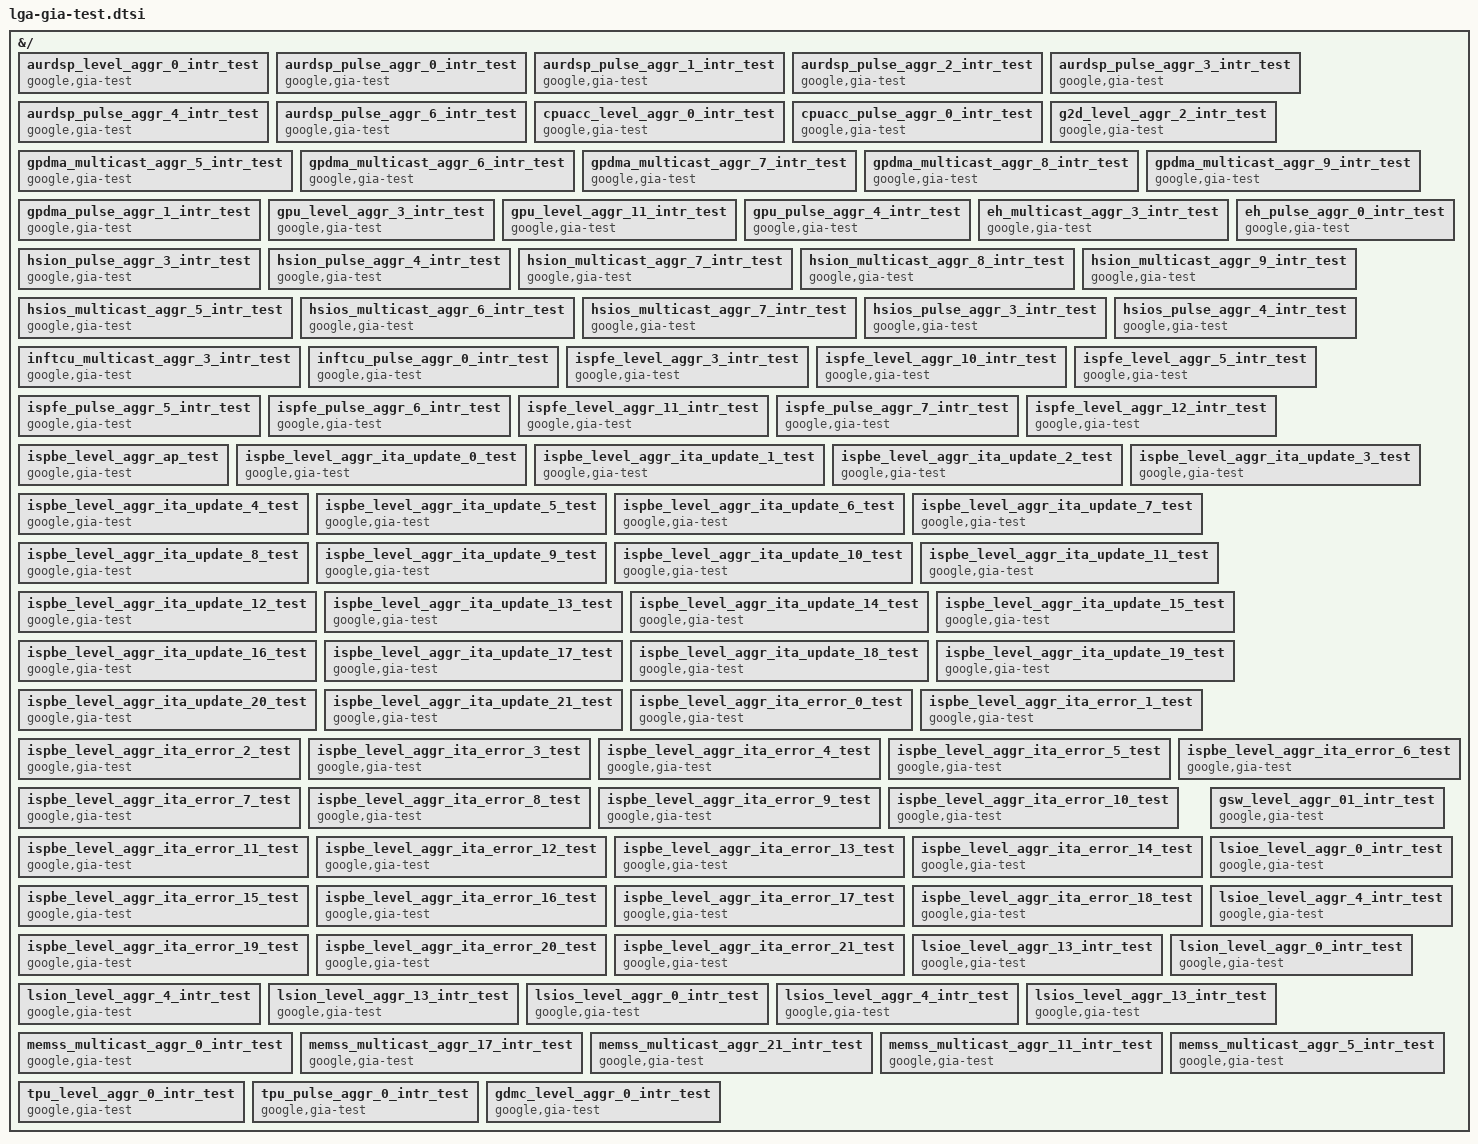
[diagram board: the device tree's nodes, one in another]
// SPDX-License-Identifier: GPL-2.0-only OR BSD-3-Clause
/*
 * !!!!!!!!!!!!!!!!!!!!!!!!!!!!!!!!!!!!!!!!!!!!!!!!!
 * !!!!! THIS IS A GENERATED FILE, DO NOT EDIT !!!!!
 * !!!!!!!!!!!!!!!!!!!!!!!!!!!!!!!!!!!!!!!!!!!!!!!!!
 *
 * This file provides test nodes for use with the GIA test driver
 * Generate using scripts/irqchip/gen-test-gia-dt-nodes.py
 *
 * Copyright 2024 Google LLC
 */

#include <dt-bindings/interrupt-controller/lga-gic.h>
#include <dt-bindings/interrupt-controller/irq-gia-google-lga.h>

&{/} {
	aurdsp_level_aggr_0_intr_test: aurdsp_level_aggr_0_intr_test {
		compatible = "google,gia-test";
		power-domains = <&sswrp_aurora_pd>;
		interrupt-parent = <&aurdsp_level_aggr_0_intr>;
		interrupts =
			<AURDSP_GIA_LEVEL_AGGR_0_AURORA_AUX_RA_CORE_0_NS_INTR>,
			<AURDSP_GIA_LEVEL_AGGR_0_AURORA_AUX_RA_CORE_1_NS_INTR>,
			<AURDSP_GIA_LEVEL_AGGR_0_AURORA_AUX_RA_CORE_2_NS_INTR>,
			<AURDSP_GIA_LEVEL_AGGR_0_AURORA_AUX_RA_MCU_NS_INTR>,
			<AURDSP_GIA_LEVEL_AGGR_0_AURORA_AUX_RFW_XFW_NS_INTR>,
			<AURDSP_GIA_LEVEL_AGGR_0_AURORA_AUX_AUR_TOP_RFW_XFW_NS_INTR>,
			<AURDSP_GIA_LEVEL_AGGR_0_AURORA_AUX_AON_LPCM_RFW_XFW_NS_INTR>,
			<AURDSP_GIA_LEVEL_AGGR_0_AURORA_AUX_TBU0_MFW_NS_INTR>,
			<AURDSP_GIA_LEVEL_AGGR_0_AURORA_AUX_TBU1_MFW_NS_INTR>,
			<AURDSP_GIA_LEVEL_AGGR_0_AURORA_AUX_TBU2_MFW_NS_INTR>,
			<AURDSP_GIA_LEVEL_AGGR_0_AURORA_AUX_TBU3_MFW_NS_INTR>,
			<AURDSP_GIA_LEVEL_AGGR_0_AURORA_AUX_GEM_CORE_0_IRQ>,
			<AURDSP_GIA_LEVEL_AGGR_0_AURORA_AUX_GEM_CORE_1_IRQ>,
			<AURDSP_GIA_LEVEL_AGGR_0_AURORA_AUX_GEM_CORE_2_IRQ>,
			<AURDSP_GIA_LEVEL_AGGR_0_AURORA_AUX_GEM_MCU_IRQ>,
			<AURDSP_GIA_LEVEL_AGGR_0_AURORA_AUX_GEM_TCU_IRQ>,
			<AURDSP_GIA_LEVEL_AGGR_0_AURORA_AURORA_TOP_UNCORE_MCU_UNCORE_NOC_IXBAR0_XBA0_ERR_IRQ>,
			<AURDSP_GIA_LEVEL_AGGR_0_AURORA_AURORA_TOP_UNCORE_MCU_UNCORE_NOC_IXBAR1_XBA1_ERR_IRQ>,
			<AURDSP_GIA_LEVEL_AGGR_0_AURORA_AURORA_TOP_UNCORE_MCU_UNCORE_NOC_IXBAR2_XBA2_ERR_IRQ>,
			<AURDSP_GIA_LEVEL_AGGR_0_AURORA_AURORA_TOP_UNCORE_MCU_UNCORE_NOC_IXBAR3_XBA3_ERR_IRQ>,
			<AURDSP_GIA_LEVEL_AGGR_0_AURORA_AURORA_TOP_UNCORE_MCU_UNCORE_NOC_IXBAR4_XBA4_ERR_IRQ>,
			<AURDSP_GIA_LEVEL_AGGR_0_AURORA_AURORA_TOP_UNCORE_MCU_UNCORE_NOC_IXBAR5_XBA5_ERR_IRQ>,
			<AURDSP_GIA_LEVEL_AGGR_0_AURORA_AUX_CTRL_NOC_XBA0_ERR_IRQ>,
			<AURDSP_GIA_LEVEL_AGGR_0_GIA_PLUSE_PULSE_AGGR_0_INTR>,
			<AURDSP_GIA_LEVEL_AGGR_0_GIA_PLUSE_PULSE_AGGR_1_INTR>,
			<AURDSP_GIA_LEVEL_AGGR_0_GIA_PLUSE_PULSE_AGGR_2_INTR>,
			<AURDSP_GIA_LEVEL_AGGR_0_GIA_PLUSE_PULSE_AGGR_3_INTR>,
			<AURDSP_GIA_LEVEL_AGGR_0_GIA_PLUSE_PULSE_AGGR_4_INTR>,
			<AURDSP_GIA_LEVEL_AGGR_0_GIA_PLUSE_PULSE_AGGR_6_INTR>;
		interrupt-names =
			"AURDSP_GIA_LEVEL_AGGR_0_AURORA_AUX_RA_CORE_0_NS_INTR",
			"AURDSP_GIA_LEVEL_AGGR_0_AURORA_AUX_RA_CORE_1_NS_INTR",
			"AURDSP_GIA_LEVEL_AGGR_0_AURORA_AUX_RA_CORE_2_NS_INTR",
			"AURDSP_GIA_LEVEL_AGGR_0_AURORA_AUX_RA_MCU_NS_INTR",
			"AURDSP_GIA_LEVEL_AGGR_0_AURORA_AUX_RFW_XFW_NS_INTR",
			"AURDSP_GIA_LEVEL_AGGR_0_AURORA_AUX_AUR_TOP_RFW_XFW_NS_INTR",
			"AURDSP_GIA_LEVEL_AGGR_0_AURORA_AUX_AON_LPCM_RFW_XFW_NS_INTR",
			"AURDSP_GIA_LEVEL_AGGR_0_AURORA_AUX_TBU0_MFW_NS_INTR",
			"AURDSP_GIA_LEVEL_AGGR_0_AURORA_AUX_TBU1_MFW_NS_INTR",
			"AURDSP_GIA_LEVEL_AGGR_0_AURORA_AUX_TBU2_MFW_NS_INTR",
			"AURDSP_GIA_LEVEL_AGGR_0_AURORA_AUX_TBU3_MFW_NS_INTR",
			"AURDSP_GIA_LEVEL_AGGR_0_AURORA_AUX_GEM_CORE_0_IRQ",
			"AURDSP_GIA_LEVEL_AGGR_0_AURORA_AUX_GEM_CORE_1_IRQ",
			"AURDSP_GIA_LEVEL_AGGR_0_AURORA_AUX_GEM_CORE_2_IRQ",
			"AURDSP_GIA_LEVEL_AGGR_0_AURORA_AUX_GEM_MCU_IRQ",
			"AURDSP_GIA_LEVEL_AGGR_0_AURORA_AUX_GEM_TCU_IRQ",
			"AURDSP_GIA_LEVEL_AGGR_0_AURORA_AURORA_TOP_UNCORE_MCU_UNCORE_NOC_IXBAR0_XBA0_ERR_IRQ",
			"AURDSP_GIA_LEVEL_AGGR_0_AURORA_AURORA_TOP_UNCORE_MCU_UNCORE_NOC_IXBAR1_XBA1_ERR_IRQ",
			"AURDSP_GIA_LEVEL_AGGR_0_AURORA_AURORA_TOP_UNCORE_MCU_UNCORE_NOC_IXBAR2_XBA2_ERR_IRQ",
			"AURDSP_GIA_LEVEL_AGGR_0_AURORA_AURORA_TOP_UNCORE_MCU_UNCORE_NOC_IXBAR3_XBA3_ERR_IRQ",
			"AURDSP_GIA_LEVEL_AGGR_0_AURORA_AURORA_TOP_UNCORE_MCU_UNCORE_NOC_IXBAR4_XBA4_ERR_IRQ",
			"AURDSP_GIA_LEVEL_AGGR_0_AURORA_AURORA_TOP_UNCORE_MCU_UNCORE_NOC_IXBAR5_XBA5_ERR_IRQ",
			"AURDSP_GIA_LEVEL_AGGR_0_AURORA_AUX_CTRL_NOC_XBA0_ERR_IRQ",
			"AURDSP_GIA_LEVEL_AGGR_0_GIA_PLUSE_PULSE_AGGR_0_INTR",
			"AURDSP_GIA_LEVEL_AGGR_0_GIA_PLUSE_PULSE_AGGR_1_INTR",
			"AURDSP_GIA_LEVEL_AGGR_0_GIA_PLUSE_PULSE_AGGR_2_INTR",
			"AURDSP_GIA_LEVEL_AGGR_0_GIA_PLUSE_PULSE_AGGR_3_INTR",
			"AURDSP_GIA_LEVEL_AGGR_0_GIA_PLUSE_PULSE_AGGR_4_INTR",
			"AURDSP_GIA_LEVEL_AGGR_0_GIA_PLUSE_PULSE_AGGR_6_INTR";
	};

	aurdsp_pulse_aggr_0_intr_test: aurdsp_pulse_aggr_0_intr_test {
		compatible = "google,gia-test";
		power-domains = <&sswrp_aurora_pd>;
		interrupt-parent = <&aurdsp_pulse_aggr_0_intr>;
		interrupts =
			<AURDSP_GIA_PULSE_AGGR_0_AURORA_AUX_SMMU_TBU_WRAPPER_0_TBU_RAS_FHI>,
			<AURDSP_GIA_PULSE_AGGR_0_AURORA_AUX_SMMU_TBU_WRAPPER_0_TBU_RAS_ERI>,
			<AURDSP_GIA_PULSE_AGGR_0_AURORA_AUX_SMMU_TBU_WRAPPER_0_TBU_RAS_CRI>,
			<AURDSP_GIA_PULSE_AGGR_0_AURORA_AUX_SMMU_TBU_WRAPPER_0_TBU_PMU_IRPT>;
		interrupt-names =
			"AURDSP_GIA_PULSE_AGGR_0_AURORA_AUX_SMMU_TBU_WRAPPER_0_TBU_RAS_FHI",
			"AURDSP_GIA_PULSE_AGGR_0_AURORA_AUX_SMMU_TBU_WRAPPER_0_TBU_RAS_ERI",
			"AURDSP_GIA_PULSE_AGGR_0_AURORA_AUX_SMMU_TBU_WRAPPER_0_TBU_RAS_CRI",
			"AURDSP_GIA_PULSE_AGGR_0_AURORA_AUX_SMMU_TBU_WRAPPER_0_TBU_PMU_IRPT";
	};

	aurdsp_pulse_aggr_1_intr_test: aurdsp_pulse_aggr_1_intr_test {
		compatible = "google,gia-test";
		power-domains = <&sswrp_aurora_pd>;
		interrupt-parent = <&aurdsp_pulse_aggr_1_intr>;
		interrupts =
			<AURDSP_GIA_PULSE_AGGR_1_AURORA_AUX_SMMU_TBU_WRAPPER_1_TBU_RAS_FHI>,
			<AURDSP_GIA_PULSE_AGGR_1_AURORA_AUX_SMMU_TBU_WRAPPER_1_TBU_RAS_ERI>,
			<AURDSP_GIA_PULSE_AGGR_1_AURORA_AUX_SMMU_TBU_WRAPPER_1_TBU_RAS_CRI>,
			<AURDSP_GIA_PULSE_AGGR_1_AURORA_AUX_SMMU_TBU_WRAPPER_1_TBU_PMU_IRPT>;
		interrupt-names =
			"AURDSP_GIA_PULSE_AGGR_1_AURORA_AUX_SMMU_TBU_WRAPPER_1_TBU_RAS_FHI",
			"AURDSP_GIA_PULSE_AGGR_1_AURORA_AUX_SMMU_TBU_WRAPPER_1_TBU_RAS_ERI",
			"AURDSP_GIA_PULSE_AGGR_1_AURORA_AUX_SMMU_TBU_WRAPPER_1_TBU_RAS_CRI",
			"AURDSP_GIA_PULSE_AGGR_1_AURORA_AUX_SMMU_TBU_WRAPPER_1_TBU_PMU_IRPT";
	};

	aurdsp_pulse_aggr_2_intr_test: aurdsp_pulse_aggr_2_intr_test {
		compatible = "google,gia-test";
		power-domains = <&sswrp_aurora_pd>;
		interrupt-parent = <&aurdsp_pulse_aggr_2_intr>;
		interrupts =
			<AURDSP_GIA_PULSE_AGGR_2_AURORA_AUX_SMMU_TBU_WRAPPER_2_TBU_RAS_FHI>,
			<AURDSP_GIA_PULSE_AGGR_2_AURORA_AUX_SMMU_TBU_WRAPPER_2_TBU_RAS_ERI>,
			<AURDSP_GIA_PULSE_AGGR_2_AURORA_AUX_SMMU_TBU_WRAPPER_2_TBU_RAS_CRI>,
			<AURDSP_GIA_PULSE_AGGR_2_AURORA_AUX_SMMU_TBU_WRAPPER_2_TBU_PMU_IRPT>;
		interrupt-names =
			"AURDSP_GIA_PULSE_AGGR_2_AURORA_AUX_SMMU_TBU_WRAPPER_2_TBU_RAS_FHI",
			"AURDSP_GIA_PULSE_AGGR_2_AURORA_AUX_SMMU_TBU_WRAPPER_2_TBU_RAS_ERI",
			"AURDSP_GIA_PULSE_AGGR_2_AURORA_AUX_SMMU_TBU_WRAPPER_2_TBU_RAS_CRI",
			"AURDSP_GIA_PULSE_AGGR_2_AURORA_AUX_SMMU_TBU_WRAPPER_2_TBU_PMU_IRPT";
	};

	aurdsp_pulse_aggr_3_intr_test: aurdsp_pulse_aggr_3_intr_test {
		compatible = "google,gia-test";
		power-domains = <&sswrp_aurora_pd>;
		interrupt-parent = <&aurdsp_pulse_aggr_3_intr>;
		interrupts =
			<AURDSP_GIA_PULSE_AGGR_3_AURORA_AUX_SMMU_TBU_WRAPPER_3_TBU_RAS_FHI>,
			<AURDSP_GIA_PULSE_AGGR_3_AURORA_AUX_SMMU_TBU_WRAPPER_3_TBU_RAS_ERI>,
			<AURDSP_GIA_PULSE_AGGR_3_AURORA_AUX_SMMU_TBU_WRAPPER_3_TBU_RAS_CRI>,
			<AURDSP_GIA_PULSE_AGGR_3_AURORA_AUX_SMMU_TBU_WRAPPER_3_TBU_PMU_IRPT>;
		interrupt-names =
			"AURDSP_GIA_PULSE_AGGR_3_AURORA_AUX_SMMU_TBU_WRAPPER_3_TBU_RAS_FHI",
			"AURDSP_GIA_PULSE_AGGR_3_AURORA_AUX_SMMU_TBU_WRAPPER_3_TBU_RAS_ERI",
			"AURDSP_GIA_PULSE_AGGR_3_AURORA_AUX_SMMU_TBU_WRAPPER_3_TBU_RAS_CRI",
			"AURDSP_GIA_PULSE_AGGR_3_AURORA_AUX_SMMU_TBU_WRAPPER_3_TBU_PMU_IRPT";
	};

	aurdsp_pulse_aggr_4_intr_test: aurdsp_pulse_aggr_4_intr_test {
		compatible = "google,gia-test";
		power-domains = <&sswrp_aurora_pd>;
		interrupt-parent = <&aurdsp_pulse_aggr_4_intr>;
		interrupts =
			<AURDSP_GIA_PULSE_AGGR_4_AURORA_AUX_SMMU_TCU_EVENT_Q_IRPT_NS>,
			<AURDSP_GIA_PULSE_AGGR_4_AURORA_AUX_SMMU_TCU_CMD_SYNC_IRPT_NS>,
			<AURDSP_GIA_PULSE_AGGR_4_AURORA_AUX_SMMU_TCU_GLOBAL_IRPT_NS>,
			<AURDSP_GIA_PULSE_AGGR_4_AURORA_AUX_SMMU_TCU_RAS_FHI>,
			<AURDSP_GIA_PULSE_AGGR_4_AURORA_AUX_SMMU_TCU_RAS_ERI>,
			<AURDSP_GIA_PULSE_AGGR_4_AURORA_AUX_SMMU_TCU_RAS_CRI>,
			<AURDSP_GIA_PULSE_AGGR_4_AURORA_AUX_SMMU_TCU_PMU_IRPT>,
			<AURDSP_GIA_PULSE_AGGR_4_AURORA_AUX_SMMU_TCU_PRI_Q_IRPT_NS>;
		interrupt-names =
			"AURDSP_GIA_PULSE_AGGR_4_AURORA_AUX_SMMU_TCU_EVENT_Q_IRPT_NS",
			"AURDSP_GIA_PULSE_AGGR_4_AURORA_AUX_SMMU_TCU_CMD_SYNC_IRPT_NS",
			"AURDSP_GIA_PULSE_AGGR_4_AURORA_AUX_SMMU_TCU_GLOBAL_IRPT_NS",
			"AURDSP_GIA_PULSE_AGGR_4_AURORA_AUX_SMMU_TCU_RAS_FHI",
			"AURDSP_GIA_PULSE_AGGR_4_AURORA_AUX_SMMU_TCU_RAS_ERI",
			"AURDSP_GIA_PULSE_AGGR_4_AURORA_AUX_SMMU_TCU_RAS_CRI",
			"AURDSP_GIA_PULSE_AGGR_4_AURORA_AUX_SMMU_TCU_PMU_IRPT",
			"AURDSP_GIA_PULSE_AGGR_4_AURORA_AUX_SMMU_TCU_PRI_Q_IRPT_NS";
	};

	aurdsp_pulse_aggr_6_intr_test: aurdsp_pulse_aggr_6_intr_test {
		compatible = "google,gia-test";
		power-domains = <&sswrp_aurora_pd>;
		interrupt-parent = <&aurdsp_pulse_aggr_6_intr>;
		interrupts =
			<AURDSP_GIA_PULSE_AGGR_6_AUX_GSPAN_TCU_ICD_ERR_DSCGT>,
			<AURDSP_GIA_PULSE_AGGR_6_AURORA_AUX_GSPAN_CORE_0_ICD_ERR_DSCGT>,
			<AURDSP_GIA_PULSE_AGGR_6_AURORA_AUX_GSPAN_CORE_1_ICD_ERR_DSCGT>,
			<AURDSP_GIA_PULSE_AGGR_6_AURORA_AUX_GSPAN_CORE_2_ICD_ERR_DSCGT>,
			<AURDSP_GIA_PULSE_AGGR_6_AURORA_AUX_GSPAN_MCU_ICD_ERR_DSCGT>,
			<AURDSP_GIA_PULSE_AGGR_6_AURORA_AUX_GSPAN_ATB_ICD_ERR_DSCGT>;
		interrupt-names =
			"AURDSP_GIA_PULSE_AGGR_6_AUX_GSPAN_TCU_ICD_ERR_DSCGT",
			"AURDSP_GIA_PULSE_AGGR_6_AURORA_AUX_GSPAN_CORE_0_ICD_ERR_DSCGT",
			"AURDSP_GIA_PULSE_AGGR_6_AURORA_AUX_GSPAN_CORE_1_ICD_ERR_DSCGT",
			"AURDSP_GIA_PULSE_AGGR_6_AURORA_AUX_GSPAN_CORE_2_ICD_ERR_DSCGT",
			"AURDSP_GIA_PULSE_AGGR_6_AURORA_AUX_GSPAN_MCU_ICD_ERR_DSCGT",
			"AURDSP_GIA_PULSE_AGGR_6_AURORA_AUX_GSPAN_ATB_ICD_ERR_DSCGT";
	};

	cpuacc_level_aggr_0_intr_test: cpuacc_level_aggr_0_intr_test {
		compatible = "google,gia-test";
		interrupt-parent = <&cpuacc_level_aggr_0_intr>;
		interrupts =
			<CPUACC_GIA_LEVEL_AGGR_0_DUMMY_GIA_PULSE_AGGR_0_INTR_10>,
			<CPUACC_GIA_LEVEL_AGGR_0_DUMMY_GIA_PULSE_AGGR_0_INTR_9>,
			<CPUACC_GIA_LEVEL_AGGR_0_DUMMY_GIA_PULSE_AGGR_0_INTR_8>,
			<CPUACC_GIA_LEVEL_AGGR_0_DUMMY_GIA_PULSE_AGGR_0_INTR_7>,
			<CPUACC_GIA_LEVEL_AGGR_0_DUMMY_GIA_PULSE_AGGR_0_INTR_6>,
			<CPUACC_GIA_LEVEL_AGGR_0_DUMMY_GIA_PULSE_AGGR_0_INTR_5>,
			<CPUACC_GIA_LEVEL_AGGR_0_DUMMY_GIA_PULSE_AGGR_0_INTR_4>,
			<CPUACC_GIA_LEVEL_AGGR_0_DUMMY_GIA_PULSE_AGGR_0_INTR_3>,
			<CPUACC_GIA_LEVEL_AGGR_0_DUMMY_GIA_PULSE_AGGR_0_INTR_2>,
			<CPUACC_GIA_LEVEL_AGGR_0_DUMMY_GIA_PULSE_AGGR_0_INTR_1>,
			<CPUACC_GIA_LEVEL_AGGR_0_DUMMY_GIA_PULSE_AGGR_0_INTR_0>,
			<CPUACC_GIA_LEVEL_AGGR_0_AUX_ELA600_ELA_OUTPUT_0>,
			<CPUACC_GIA_LEVEL_AGGR_0_AUX_ELA600_ELA_OUTPUT_1>,
			<CPUACC_GIA_LEVEL_AGGR_0_AUX_ELA600_ELA_OUTPUT_2>,
			<CPUACC_GIA_LEVEL_AGGR_0_AUX_ELA600_ELA_OUTPUT_3>,
			<CPUACC_GIA_LEVEL_AGGR_0_AUX_TCU_ACEM_GEM_IRQ>,
			<CPUACC_GIA_LEVEL_AGGR_0_AUX_GIC_ACEM_GEM_IRQ>,
			<CPUACC_GIA_LEVEL_AGGR_0_AUX_RFW_768_GIC700_NS_INTR>,
			<CPUACC_GIA_LEVEL_AGGR_0_AUX_RFW_128_GIC400_NS_INTR>,
			<CPUACC_GIA_LEVEL_AGGR_0_AUX_AON_RFW_LPCM_NS_INTR>,
			<CPUACC_GIA_LEVEL_AGGR_0_AUX_RFW_768_TCU_NS_INTR>,
			<CPUACC_GIA_LEVEL_AGGR_0_AUX_CPSTBYCPUACC_XBA0_ERR_IRQ>,
			<CPUACC_GIA_LEVEL_AGGR_0_DUMMY_GIA_PULSE_AGGR_1_INTR_3>,
			<CPUACC_GIA_LEVEL_AGGR_0_DUMMY_GIA_PULSE_AGGR_1_INTR_2>,
			<CPUACC_GIA_LEVEL_AGGR_0_DUMMY_GIA_PULSE_AGGR_1_INTR_1>,
			<CPUACC_GIA_LEVEL_AGGR_0_DUMMY_GIA_PULSE_AGGR_1_INTR_0>,
			<CPUACC_GIA_LEVEL_AGGR_0_AUX_GSPAN_ILINK_TGT_ICD_ERR_DSCGT>;
		interrupt-names =
			"CPUACC_GIA_LEVEL_AGGR_0_DUMMY_GIA_PULSE_AGGR_0_INTR_10",
			"CPUACC_GIA_LEVEL_AGGR_0_DUMMY_GIA_PULSE_AGGR_0_INTR_9",
			"CPUACC_GIA_LEVEL_AGGR_0_DUMMY_GIA_PULSE_AGGR_0_INTR_8",
			"CPUACC_GIA_LEVEL_AGGR_0_DUMMY_GIA_PULSE_AGGR_0_INTR_7",
			"CPUACC_GIA_LEVEL_AGGR_0_DUMMY_GIA_PULSE_AGGR_0_INTR_6",
			"CPUACC_GIA_LEVEL_AGGR_0_DUMMY_GIA_PULSE_AGGR_0_INTR_5",
			"CPUACC_GIA_LEVEL_AGGR_0_DUMMY_GIA_PULSE_AGGR_0_INTR_4",
			"CPUACC_GIA_LEVEL_AGGR_0_DUMMY_GIA_PULSE_AGGR_0_INTR_3",
			"CPUACC_GIA_LEVEL_AGGR_0_DUMMY_GIA_PULSE_AGGR_0_INTR_2",
			"CPUACC_GIA_LEVEL_AGGR_0_DUMMY_GIA_PULSE_AGGR_0_INTR_1",
			"CPUACC_GIA_LEVEL_AGGR_0_DUMMY_GIA_PULSE_AGGR_0_INTR_0",
			"CPUACC_GIA_LEVEL_AGGR_0_AUX_ELA600_ELA_OUTPUT_0",
			"CPUACC_GIA_LEVEL_AGGR_0_AUX_ELA600_ELA_OUTPUT_1",
			"CPUACC_GIA_LEVEL_AGGR_0_AUX_ELA600_ELA_OUTPUT_2",
			"CPUACC_GIA_LEVEL_AGGR_0_AUX_ELA600_ELA_OUTPUT_3",
			"CPUACC_GIA_LEVEL_AGGR_0_AUX_TCU_ACEM_GEM_IRQ",
			"CPUACC_GIA_LEVEL_AGGR_0_AUX_GIC_ACEM_GEM_IRQ",
			"CPUACC_GIA_LEVEL_AGGR_0_AUX_RFW_768_GIC700_NS_INTR",
			"CPUACC_GIA_LEVEL_AGGR_0_AUX_RFW_128_GIC400_NS_INTR",
			"CPUACC_GIA_LEVEL_AGGR_0_AUX_AON_RFW_LPCM_NS_INTR",
			"CPUACC_GIA_LEVEL_AGGR_0_AUX_RFW_768_TCU_NS_INTR",
			"CPUACC_GIA_LEVEL_AGGR_0_AUX_CPSTBYCPUACC_XBA0_ERR_IRQ",
			"CPUACC_GIA_LEVEL_AGGR_0_DUMMY_GIA_PULSE_AGGR_1_INTR_3",
			"CPUACC_GIA_LEVEL_AGGR_0_DUMMY_GIA_PULSE_AGGR_1_INTR_2",
			"CPUACC_GIA_LEVEL_AGGR_0_DUMMY_GIA_PULSE_AGGR_1_INTR_1",
			"CPUACC_GIA_LEVEL_AGGR_0_DUMMY_GIA_PULSE_AGGR_1_INTR_0",
			"CPUACC_GIA_LEVEL_AGGR_0_AUX_GSPAN_ILINK_TGT_ICD_ERR_DSCGT";
	};

	cpuacc_pulse_aggr_0_intr_test: cpuacc_pulse_aggr_0_intr_test {
		compatible = "google,gia-test";
		interrupt-parent = <&cpuacc_pulse_aggr_0_intr>;
		interrupts =
			<CPUACC_GIA_PULSE_AGGR_0_AUX_TOP_MMU700_TCU_EVENT_Q_IRPT_NS>,
			<CPUACC_GIA_PULSE_AGGR_0_AUX_TOP_MMU700_TCU_CMD_SYNC_IRPT_NS>,
			<CPUACC_GIA_PULSE_AGGR_0_AUX_TOP_MMU700_TCU_GLOBAL_IRPT_NS>,
			<CPUACC_GIA_PULSE_AGGR_0_AUX_TOP_MMU700_TCU_RAS_FHI>,
			<CPUACC_GIA_PULSE_AGGR_0_AUX_TOP_MMU700_TCU_RAS_ERI>,
			<CPUACC_GIA_PULSE_AGGR_0_AUX_TOP_MMU700_TCU_RAS_CRI>,
			<CPUACC_GIA_PULSE_AGGR_0_AUX_TOP_MMU700_TCU_PMU_IRPT>,
			<CPUACC_GIA_PULSE_AGGR_0_AUX_TOP_MMU700_TCU_PRI_Q_IRPT_NS>,
			<CPUACC_GIA_PULSE_AGGR_0_AUX_TOP_GIC700_FAULT_INT>,
			<CPUACC_GIA_PULSE_AGGR_0_AUX_TOP_GIC700_ERR_INT>,
			<CPUACC_GIA_PULSE_AGGR_0_AUX_TOP_GIC700_PMU_INT>;
		interrupt-names =
			"CPUACC_GIA_PULSE_AGGR_0_AUX_TOP_MMU700_TCU_EVENT_Q_IRPT_NS",
			"CPUACC_GIA_PULSE_AGGR_0_AUX_TOP_MMU700_TCU_CMD_SYNC_IRPT_NS",
			"CPUACC_GIA_PULSE_AGGR_0_AUX_TOP_MMU700_TCU_GLOBAL_IRPT_NS",
			"CPUACC_GIA_PULSE_AGGR_0_AUX_TOP_MMU700_TCU_RAS_FHI",
			"CPUACC_GIA_PULSE_AGGR_0_AUX_TOP_MMU700_TCU_RAS_ERI",
			"CPUACC_GIA_PULSE_AGGR_0_AUX_TOP_MMU700_TCU_RAS_CRI",
			"CPUACC_GIA_PULSE_AGGR_0_AUX_TOP_MMU700_TCU_PMU_IRPT",
			"CPUACC_GIA_PULSE_AGGR_0_AUX_TOP_MMU700_TCU_PRI_Q_IRPT_NS",
			"CPUACC_GIA_PULSE_AGGR_0_AUX_TOP_GIC700_FAULT_INT",
			"CPUACC_GIA_PULSE_AGGR_0_AUX_TOP_GIC700_ERR_INT",
			"CPUACC_GIA_PULSE_AGGR_0_AUX_TOP_GIC700_PMU_INT";
	};

	g2d_level_aggr_2_intr_test: g2d_level_aggr_2_intr_test {
		compatible = "google,gia-test";
		power-domains = <&sswrp_g2d_pd>;
		interrupt-parent = <&g2d_level_aggr_2_intr>;
		interrupts =
			<G2D_GIA_LEVEL_2_AGGR_IP_NS_GIA_INPUT_IRQ_PIPE1_PVRIC_ENCODE_ERROR>,
			<G2D_GIA_LEVEL_2_AGGR_IP_NS_GIA_INPUT_IRQ_PIPE1_PVRIC_DECODE_ERROR>,
			<G2D_GIA_LEVEL_2_AGGR_IP_NS_GIA_INPUT_IRQ_PIPE0_PVRIC_ENCODE_ERROR>,
			<G2D_GIA_LEVEL_2_AGGR_IP_NS_GIA_INPUT_IRQ_PIPE0_PVRIC_DECODE_ERROR>,
			<G2D_GIA_LEVEL_2_AGGR_IP_NS_GIA_INPUT_IRQ_AXI_BUS_ERROR>,
			<G2D_GIA_LEVEL_2_AGGR_IP_NS_GIA_INPUT_IRQ_AXI_WR_BUS_HANG>,
			<G2D_GIA_LEVEL_2_AGGR_IP_NS_GIA_INPUT_IRQ_AXI_RD_BUS_HANG>,
			<G2D_GIA_LEVEL_2_AGGR_IP_NS_GIA_INPUT_IRQ_APB_HANG>,
			<G2D_GIA_LEVEL_2_AGGR_IP_NS_GIA_INPUT_IRQ_PIPE1_FRAME_DONE>,
			<G2D_GIA_LEVEL_2_AGGR_IP_NS_GIA_INPUT_IRQ_PIPE0_FRAME_DONE>,
			<G2D_GIA_LEVEL_2_AGGR_IP_NS_GIA_INPUT_IRQ_PIPE1_FRAME_START>,
			<G2D_GIA_LEVEL_2_AGGR_IP_NS_GIA_INPUT_IRQ_PIPE0_FRAME_START>,
			<G2D_GIA_LEVEL_2_AGGR_IP_NS_GIA_INPUT_IRQ_SW_RST_DONE>,
			<G2D_GIA_LEVEL_2_AGGR_CORE_PDMA_0_NS_GIA_INPUT_NS_PDMA0_IRQ>,
			<G2D_GIA_LEVEL_2_AGGR_CORE_PDMA_1_NS_GIA_INPUT_NS_PDMA1_IRQ>,
			<G2D_GIA_LEVEL_2_AGGR_CORE_RA_NS_GIA_INPUT_NS_RA_INTR>,
			<G2D_GIA_LEVEL_2_AGGR_CORE_MFW_TBU_NS_GIA_INPUT_NS_XFW_INTR>,
			<G2D_GIA_LEVEL_2_AGGR_CORE_RFW_CFGBRG_NS_GIA_INPUT_NS_RFW_INTR>,
			<G2D_GIA_LEVEL_2_AGGR_DUMMY_GIA_NS_GIA_INPUT_PULSE_AGGR_2_INTR>,
			<G2D_GIA_LEVEL_2_AGGR_DUMMY_GIA_NS_GIA_INPUT_PULSE_AGGR_3_INTR>,
			<G2D_GIA_LEVEL_2_AGGR_DUMMY_GIA_NS_GIA_INPUT_PULSE_AGGR_4_INTR>,
			<G2D_GIA_LEVEL_2_AGGR_DUMMY_GIA_NS_GIA_INPUT_PULSE_AGGR_5_INTR>,
			<G2D_GIA_LEVEL_2_AGGR_CORE_GEM_NS_GIA_INPUT_NS_IRQ_GEM>,
			<G2D_GIA_LEVEL_2_AGGR_CPRTG2D_IFABRIC_RT_DPU_NS_GIA_INPUT_NS_XBA0_ERR_IRQ>,
			<G2D_GIA_LEVEL_2_AGGR_DUMMY_GIA_NS_GIA_INPUT_PULSE_AGGR_0_INTR>,
			<G2D_GIA_LEVEL_2_AGGR_DUMMY_GIA_NS_GIA_INPUT_PULSE_AGGR_1_INTR>;
		interrupt-names =
			"G2D_GIA_LEVEL_2_AGGR_IP_NS_GIA_INPUT_IRQ_PIPE1_PVRIC_ENCODE_ERROR",
			"G2D_GIA_LEVEL_2_AGGR_IP_NS_GIA_INPUT_IRQ_PIPE1_PVRIC_DECODE_ERROR",
			"G2D_GIA_LEVEL_2_AGGR_IP_NS_GIA_INPUT_IRQ_PIPE0_PVRIC_ENCODE_ERROR",
			"G2D_GIA_LEVEL_2_AGGR_IP_NS_GIA_INPUT_IRQ_PIPE0_PVRIC_DECODE_ERROR",
			"G2D_GIA_LEVEL_2_AGGR_IP_NS_GIA_INPUT_IRQ_AXI_BUS_ERROR",
			"G2D_GIA_LEVEL_2_AGGR_IP_NS_GIA_INPUT_IRQ_AXI_WR_BUS_HANG",
			"G2D_GIA_LEVEL_2_AGGR_IP_NS_GIA_INPUT_IRQ_AXI_RD_BUS_HANG",
			"G2D_GIA_LEVEL_2_AGGR_IP_NS_GIA_INPUT_IRQ_APB_HANG",
			"G2D_GIA_LEVEL_2_AGGR_IP_NS_GIA_INPUT_IRQ_PIPE1_FRAME_DONE",
			"G2D_GIA_LEVEL_2_AGGR_IP_NS_GIA_INPUT_IRQ_PIPE0_FRAME_DONE",
			"G2D_GIA_LEVEL_2_AGGR_IP_NS_GIA_INPUT_IRQ_PIPE1_FRAME_START",
			"G2D_GIA_LEVEL_2_AGGR_IP_NS_GIA_INPUT_IRQ_PIPE0_FRAME_START",
			"G2D_GIA_LEVEL_2_AGGR_IP_NS_GIA_INPUT_IRQ_SW_RST_DONE",
			"G2D_GIA_LEVEL_2_AGGR_CORE_PDMA_0_NS_GIA_INPUT_NS_PDMA0_IRQ",
			"G2D_GIA_LEVEL_2_AGGR_CORE_PDMA_1_NS_GIA_INPUT_NS_PDMA1_IRQ",
			"G2D_GIA_LEVEL_2_AGGR_CORE_RA_NS_GIA_INPUT_NS_RA_INTR",
			"G2D_GIA_LEVEL_2_AGGR_CORE_MFW_TBU_NS_GIA_INPUT_NS_XFW_INTR",
			"G2D_GIA_LEVEL_2_AGGR_CORE_RFW_CFGBRG_NS_GIA_INPUT_NS_RFW_INTR",
			"G2D_GIA_LEVEL_2_AGGR_DUMMY_GIA_NS_GIA_INPUT_PULSE_AGGR_2_INTR",
			"G2D_GIA_LEVEL_2_AGGR_DUMMY_GIA_NS_GIA_INPUT_PULSE_AGGR_3_INTR",
			"G2D_GIA_LEVEL_2_AGGR_DUMMY_GIA_NS_GIA_INPUT_PULSE_AGGR_4_INTR",
			"G2D_GIA_LEVEL_2_AGGR_DUMMY_GIA_NS_GIA_INPUT_PULSE_AGGR_5_INTR",
			"G2D_GIA_LEVEL_2_AGGR_CORE_GEM_NS_GIA_INPUT_NS_IRQ_GEM",
			"G2D_GIA_LEVEL_2_AGGR_CPRTG2D_IFABRIC_RT_DPU_NS_GIA_INPUT_NS_XBA0_ERR_IRQ",
			"G2D_GIA_LEVEL_2_AGGR_DUMMY_GIA_NS_GIA_INPUT_PULSE_AGGR_0_INTR",
			"G2D_GIA_LEVEL_2_AGGR_DUMMY_GIA_NS_GIA_INPUT_PULSE_AGGR_1_INTR";
	};

	gpdma_multicast_aggr_5_intr_test: gpdma_multicast_aggr_5_intr_test {
		compatible = "google,gia-test";
		power-domains = <&sswrp_gpdma_pd>;
		interrupt-parent = <&gpdma_multicast_aggr_5_intr>;
		interrupts =
			<GPDMA_GIA_MULTICAST_AGGR_5_IP_TOP_GPDMA0_IRQ_0>,
			<GPDMA_GIA_MULTICAST_AGGR_5_IP_TOP_GPDMA0_IRQ_1>,
			<GPDMA_GIA_MULTICAST_AGGR_5_IP_TOP_GPDMA0_IRQ_2>,
			<GPDMA_GIA_MULTICAST_AGGR_5_IP_TOP_GPDMA0_IRQ_3>,
			<GPDMA_GIA_MULTICAST_AGGR_5_IP_TOP_GPDMA0_IRQ_4>,
			<GPDMA_GIA_MULTICAST_AGGR_5_IP_TOP_GPDMA0_IRQ_5>,
			<GPDMA_GIA_MULTICAST_AGGR_5_IP_TOP_GPDMA0_IRQ_6>,
			<GPDMA_GIA_MULTICAST_AGGR_5_IP_TOP_GPDMA0_IRQ_7>,
			<GPDMA_GIA_MULTICAST_AGGR_5_IP_TOP_GPDMA0_IRQ_8>,
			<GPDMA_GIA_MULTICAST_AGGR_5_IP_TOP_GPDMA0_IRQ_9>,
			<GPDMA_GIA_MULTICAST_AGGR_5_IP_TOP_GPDMA0_IRQ_10>,
			<GPDMA_GIA_MULTICAST_AGGR_5_IP_TOP_GPDMA0_IRQ_11>,
			<GPDMA_GIA_MULTICAST_AGGR_5_IP_TOP_GPDMA0_IRQ_12>,
			<GPDMA_GIA_MULTICAST_AGGR_5_IP_TOP_GPDMA0_IRQ_13>,
			<GPDMA_GIA_MULTICAST_AGGR_5_IP_TOP_GPDMA0_IRQ_14>,
			<GPDMA_GIA_MULTICAST_AGGR_5_IP_TOP_GPDMA0_IRQ_15>,
			<GPDMA_GIA_MULTICAST_AGGR_5_IP_TOP_GPDMA0_IRQ_16>,
			<GPDMA_GIA_MULTICAST_AGGR_5_IP_TOP_GPDMA0_IRQ_17>,
			<GPDMA_GIA_MULTICAST_AGGR_5_IP_TOP_GPDMA0_IRQ_18>,
			<GPDMA_GIA_MULTICAST_AGGR_5_IP_TOP_GPDMA0_IRQ_19>,
			<GPDMA_GIA_MULTICAST_AGGR_5_IP_TOP_GPDMA0_IRQ_20>,
			<GPDMA_GIA_MULTICAST_AGGR_5_IP_TOP_GPDMA0_IRQ_21>,
			<GPDMA_GIA_MULTICAST_AGGR_5_IP_TOP_GPDMA0_IRQ_22>,
			<GPDMA_GIA_MULTICAST_AGGR_5_IP_TOP_GPDMA0_IRQ_23>,
			<GPDMA_GIA_MULTICAST_AGGR_5_IP_TOP_GPDMA0_IRQ_24>,
			<GPDMA_GIA_MULTICAST_AGGR_5_IP_TOP_GPDMA0_IRQ_25>,
			<GPDMA_GIA_MULTICAST_AGGR_5_IP_TOP_GPDMA0_IRQ_26>,
			<GPDMA_GIA_MULTICAST_AGGR_5_IP_TOP_GPDMA0_IRQ_27>,
			<GPDMA_GIA_MULTICAST_AGGR_5_IP_TOP_GPDMA0_IRQ_28>,
			<GPDMA_GIA_MULTICAST_AGGR_5_IP_TOP_GPDMA0_IRQ_29>,
			<GPDMA_GIA_MULTICAST_AGGR_5_IP_TOP_GPDMA0_IRQ_30>,
			<GPDMA_GIA_MULTICAST_AGGR_5_IP_TOP_GPDMA0_IRQ_31>;
		interrupt-names =
			"GPDMA_GIA_MULTICAST_AGGR_5_IP_TOP_GPDMA0_IRQ_0",
			"GPDMA_GIA_MULTICAST_AGGR_5_IP_TOP_GPDMA0_IRQ_1",
			"GPDMA_GIA_MULTICAST_AGGR_5_IP_TOP_GPDMA0_IRQ_2",
			"GPDMA_GIA_MULTICAST_AGGR_5_IP_TOP_GPDMA0_IRQ_3",
			"GPDMA_GIA_MULTICAST_AGGR_5_IP_TOP_GPDMA0_IRQ_4",
			"GPDMA_GIA_MULTICAST_AGGR_5_IP_TOP_GPDMA0_IRQ_5",
			"GPDMA_GIA_MULTICAST_AGGR_5_IP_TOP_GPDMA0_IRQ_6",
			"GPDMA_GIA_MULTICAST_AGGR_5_IP_TOP_GPDMA0_IRQ_7",
			"GPDMA_GIA_MULTICAST_AGGR_5_IP_TOP_GPDMA0_IRQ_8",
			"GPDMA_GIA_MULTICAST_AGGR_5_IP_TOP_GPDMA0_IRQ_9",
			"GPDMA_GIA_MULTICAST_AGGR_5_IP_TOP_GPDMA0_IRQ_10",
			"GPDMA_GIA_MULTICAST_AGGR_5_IP_TOP_GPDMA0_IRQ_11",
			"GPDMA_GIA_MULTICAST_AGGR_5_IP_TOP_GPDMA0_IRQ_12",
			"GPDMA_GIA_MULTICAST_AGGR_5_IP_TOP_GPDMA0_IRQ_13",
			"GPDMA_GIA_MULTICAST_AGGR_5_IP_TOP_GPDMA0_IRQ_14",
			"GPDMA_GIA_MULTICAST_AGGR_5_IP_TOP_GPDMA0_IRQ_15",
			"GPDMA_GIA_MULTICAST_AGGR_5_IP_TOP_GPDMA0_IRQ_16",
			"GPDMA_GIA_MULTICAST_AGGR_5_IP_TOP_GPDMA0_IRQ_17",
			"GPDMA_GIA_MULTICAST_AGGR_5_IP_TOP_GPDMA0_IRQ_18",
			"GPDMA_GIA_MULTICAST_AGGR_5_IP_TOP_GPDMA0_IRQ_19",
			"GPDMA_GIA_MULTICAST_AGGR_5_IP_TOP_GPDMA0_IRQ_20",
			"GPDMA_GIA_MULTICAST_AGGR_5_IP_TOP_GPDMA0_IRQ_21",
			"GPDMA_GIA_MULTICAST_AGGR_5_IP_TOP_GPDMA0_IRQ_22",
			"GPDMA_GIA_MULTICAST_AGGR_5_IP_TOP_GPDMA0_IRQ_23",
			"GPDMA_GIA_MULTICAST_AGGR_5_IP_TOP_GPDMA0_IRQ_24",
			"GPDMA_GIA_MULTICAST_AGGR_5_IP_TOP_GPDMA0_IRQ_25",
			"GPDMA_GIA_MULTICAST_AGGR_5_IP_TOP_GPDMA0_IRQ_26",
			"GPDMA_GIA_MULTICAST_AGGR_5_IP_TOP_GPDMA0_IRQ_27",
			"GPDMA_GIA_MULTICAST_AGGR_5_IP_TOP_GPDMA0_IRQ_28",
			"GPDMA_GIA_MULTICAST_AGGR_5_IP_TOP_GPDMA0_IRQ_29",
			"GPDMA_GIA_MULTICAST_AGGR_5_IP_TOP_GPDMA0_IRQ_30",
			"GPDMA_GIA_MULTICAST_AGGR_5_IP_TOP_GPDMA0_IRQ_31";
	};

	gpdma_multicast_aggr_6_intr_test: gpdma_multicast_aggr_6_intr_test {
		compatible = "google,gia-test";
		power-domains = <&sswrp_gpdma_pd>;
		interrupt-parent = <&gpdma_multicast_aggr_6_intr>;
		interrupts =
			<GPDMA_GIA_MULTICAST_AGGR_6_IP_TOP_GPDMA1_IRQ_0>,
			<GPDMA_GIA_MULTICAST_AGGR_6_IP_TOP_GPDMA1_IRQ_1>,
			<GPDMA_GIA_MULTICAST_AGGR_6_IP_TOP_GPDMA1_IRQ_2>,
			<GPDMA_GIA_MULTICAST_AGGR_6_IP_TOP_GPDMA1_IRQ_3>,
			<GPDMA_GIA_MULTICAST_AGGR_6_IP_TOP_GPDMA1_IRQ_4>,
			<GPDMA_GIA_MULTICAST_AGGR_6_IP_TOP_GPDMA1_IRQ_5>,
			<GPDMA_GIA_MULTICAST_AGGR_6_IP_TOP_GPDMA1_IRQ_6>,
			<GPDMA_GIA_MULTICAST_AGGR_6_IP_TOP_GPDMA1_IRQ_7>,
			<GPDMA_GIA_MULTICAST_AGGR_6_IP_TOP_GPDMA1_IRQ_8>,
			<GPDMA_GIA_MULTICAST_AGGR_6_IP_TOP_GPDMA1_IRQ_9>,
			<GPDMA_GIA_MULTICAST_AGGR_6_IP_TOP_GPDMA1_IRQ_10>,
			<GPDMA_GIA_MULTICAST_AGGR_6_IP_TOP_GPDMA1_IRQ_11>,
			<GPDMA_GIA_MULTICAST_AGGR_6_IP_TOP_GPDMA1_IRQ_12>,
			<GPDMA_GIA_MULTICAST_AGGR_6_IP_TOP_GPDMA1_IRQ_13>,
			<GPDMA_GIA_MULTICAST_AGGR_6_IP_TOP_GPDMA1_IRQ_14>,
			<GPDMA_GIA_MULTICAST_AGGR_6_IP_TOP_GPDMA1_IRQ_15>,
			<GPDMA_GIA_MULTICAST_AGGR_6_IP_TOP_GPDMA1_IRQ_16>,
			<GPDMA_GIA_MULTICAST_AGGR_6_IP_TOP_GPDMA1_IRQ_17>,
			<GPDMA_GIA_MULTICAST_AGGR_6_IP_TOP_GPDMA1_IRQ_18>,
			<GPDMA_GIA_MULTICAST_AGGR_6_IP_TOP_GPDMA1_IRQ_19>,
			<GPDMA_GIA_MULTICAST_AGGR_6_IP_TOP_GPDMA1_IRQ_20>,
			<GPDMA_GIA_MULTICAST_AGGR_6_IP_TOP_GPDMA1_IRQ_21>,
			<GPDMA_GIA_MULTICAST_AGGR_6_IP_TOP_GPDMA1_IRQ_22>,
			<GPDMA_GIA_MULTICAST_AGGR_6_IP_TOP_GPDMA1_IRQ_23>,
			<GPDMA_GIA_MULTICAST_AGGR_6_IP_TOP_GPDMA1_IRQ_24>,
			<GPDMA_GIA_MULTICAST_AGGR_6_IP_TOP_GPDMA1_IRQ_25>,
			<GPDMA_GIA_MULTICAST_AGGR_6_IP_TOP_GPDMA1_IRQ_26>,
			<GPDMA_GIA_MULTICAST_AGGR_6_IP_TOP_GPDMA1_IRQ_27>,
			<GPDMA_GIA_MULTICAST_AGGR_6_IP_TOP_GPDMA1_IRQ_28>,
			<GPDMA_GIA_MULTICAST_AGGR_6_IP_TOP_GPDMA1_IRQ_29>,
			<GPDMA_GIA_MULTICAST_AGGR_6_IP_TOP_GPDMA1_IRQ_30>,
			<GPDMA_GIA_MULTICAST_AGGR_6_IP_TOP_GPDMA1_IRQ_31>;
		interrupt-names =
			"GPDMA_GIA_MULTICAST_AGGR_6_IP_TOP_GPDMA1_IRQ_0",
			"GPDMA_GIA_MULTICAST_AGGR_6_IP_TOP_GPDMA1_IRQ_1",
			"GPDMA_GIA_MULTICAST_AGGR_6_IP_TOP_GPDMA1_IRQ_2",
			"GPDMA_GIA_MULTICAST_AGGR_6_IP_TOP_GPDMA1_IRQ_3",
			"GPDMA_GIA_MULTICAST_AGGR_6_IP_TOP_GPDMA1_IRQ_4",
			"GPDMA_GIA_MULTICAST_AGGR_6_IP_TOP_GPDMA1_IRQ_5",
			"GPDMA_GIA_MULTICAST_AGGR_6_IP_TOP_GPDMA1_IRQ_6",
			"GPDMA_GIA_MULTICAST_AGGR_6_IP_TOP_GPDMA1_IRQ_7",
			"GPDMA_GIA_MULTICAST_AGGR_6_IP_TOP_GPDMA1_IRQ_8",
			"GPDMA_GIA_MULTICAST_AGGR_6_IP_TOP_GPDMA1_IRQ_9",
			"GPDMA_GIA_MULTICAST_AGGR_6_IP_TOP_GPDMA1_IRQ_10",
			"GPDMA_GIA_MULTICAST_AGGR_6_IP_TOP_GPDMA1_IRQ_11",
			"GPDMA_GIA_MULTICAST_AGGR_6_IP_TOP_GPDMA1_IRQ_12",
			"GPDMA_GIA_MULTICAST_AGGR_6_IP_TOP_GPDMA1_IRQ_13",
			"GPDMA_GIA_MULTICAST_AGGR_6_IP_TOP_GPDMA1_IRQ_14",
			"GPDMA_GIA_MULTICAST_AGGR_6_IP_TOP_GPDMA1_IRQ_15",
			"GPDMA_GIA_MULTICAST_AGGR_6_IP_TOP_GPDMA1_IRQ_16",
			"GPDMA_GIA_MULTICAST_AGGR_6_IP_TOP_GPDMA1_IRQ_17",
			"GPDMA_GIA_MULTICAST_AGGR_6_IP_TOP_GPDMA1_IRQ_18",
			"GPDMA_GIA_MULTICAST_AGGR_6_IP_TOP_GPDMA1_IRQ_19",
			"GPDMA_GIA_MULTICAST_AGGR_6_IP_TOP_GPDMA1_IRQ_20",
			"GPDMA_GIA_MULTICAST_AGGR_6_IP_TOP_GPDMA1_IRQ_21",
			"GPDMA_GIA_MULTICAST_AGGR_6_IP_TOP_GPDMA1_IRQ_22",
			"GPDMA_GIA_MULTICAST_AGGR_6_IP_TOP_GPDMA1_IRQ_23",
			"GPDMA_GIA_MULTICAST_AGGR_6_IP_TOP_GPDMA1_IRQ_24",
			"GPDMA_GIA_MULTICAST_AGGR_6_IP_TOP_GPDMA1_IRQ_25",
			"GPDMA_GIA_MULTICAST_AGGR_6_IP_TOP_GPDMA1_IRQ_26",
			"GPDMA_GIA_MULTICAST_AGGR_6_IP_TOP_GPDMA1_IRQ_27",
			"GPDMA_GIA_MULTICAST_AGGR_6_IP_TOP_GPDMA1_IRQ_28",
			"GPDMA_GIA_MULTICAST_AGGR_6_IP_TOP_GPDMA1_IRQ_29",
			"GPDMA_GIA_MULTICAST_AGGR_6_IP_TOP_GPDMA1_IRQ_30",
			"GPDMA_GIA_MULTICAST_AGGR_6_IP_TOP_GPDMA1_IRQ_31";
	};

	gpdma_multicast_aggr_7_intr_test: gpdma_multicast_aggr_7_intr_test {
		compatible = "google,gia-test";
		power-domains = <&sswrp_gpdma_pd>;
		interrupt-parent = <&gpdma_multicast_aggr_7_intr>;
		interrupts =
			<GPDMA_GIA_MULTICAST_AGGR_7_IP_TOP_GPDMA2_IRQ_0>,
			<GPDMA_GIA_MULTICAST_AGGR_7_IP_TOP_GPDMA2_IRQ_1>,
			<GPDMA_GIA_MULTICAST_AGGR_7_IP_TOP_GPDMA2_IRQ_2>,
			<GPDMA_GIA_MULTICAST_AGGR_7_IP_TOP_GPDMA2_IRQ_3>,
			<GPDMA_GIA_MULTICAST_AGGR_7_IP_TOP_GPDMA2_IRQ_4>,
			<GPDMA_GIA_MULTICAST_AGGR_7_IP_TOP_GPDMA2_IRQ_5>,
			<GPDMA_GIA_MULTICAST_AGGR_7_IP_TOP_GPDMA2_IRQ_6>,
			<GPDMA_GIA_MULTICAST_AGGR_7_IP_TOP_GPDMA2_IRQ_7>,
			<GPDMA_GIA_MULTICAST_AGGR_7_IP_TOP_GPDMA2_IRQ_8>,
			<GPDMA_GIA_MULTICAST_AGGR_7_IP_TOP_GPDMA2_IRQ_9>,
			<GPDMA_GIA_MULTICAST_AGGR_7_IP_TOP_GPDMA2_IRQ_10>,
			<GPDMA_GIA_MULTICAST_AGGR_7_IP_TOP_GPDMA2_IRQ_11>,
			<GPDMA_GIA_MULTICAST_AGGR_7_IP_TOP_GPDMA2_IRQ_12>,
			<GPDMA_GIA_MULTICAST_AGGR_7_IP_TOP_GPDMA2_IRQ_13>,
			<GPDMA_GIA_MULTICAST_AGGR_7_IP_TOP_GPDMA2_IRQ_14>,
			<GPDMA_GIA_MULTICAST_AGGR_7_IP_TOP_GPDMA2_IRQ_15>,
			<GPDMA_GIA_MULTICAST_AGGR_7_IP_TOP_GPDMA2_IRQ_16>,
			<GPDMA_GIA_MULTICAST_AGGR_7_IP_TOP_GPDMA2_IRQ_17>,
			<GPDMA_GIA_MULTICAST_AGGR_7_IP_TOP_GPDMA2_IRQ_18>,
			<GPDMA_GIA_MULTICAST_AGGR_7_IP_TOP_GPDMA2_IRQ_19>,
			<GPDMA_GIA_MULTICAST_AGGR_7_IP_TOP_GPDMA2_IRQ_20>,
			<GPDMA_GIA_MULTICAST_AGGR_7_IP_TOP_GPDMA2_IRQ_21>,
			<GPDMA_GIA_MULTICAST_AGGR_7_IP_TOP_GPDMA2_IRQ_22>,
			<GPDMA_GIA_MULTICAST_AGGR_7_IP_TOP_GPDMA2_IRQ_23>,
			<GPDMA_GIA_MULTICAST_AGGR_7_IP_TOP_GPDMA2_IRQ_24>,
			<GPDMA_GIA_MULTICAST_AGGR_7_IP_TOP_GPDMA2_IRQ_25>,
			<GPDMA_GIA_MULTICAST_AGGR_7_IP_TOP_GPDMA2_IRQ_26>,
			<GPDMA_GIA_MULTICAST_AGGR_7_IP_TOP_GPDMA2_IRQ_27>,
			<GPDMA_GIA_MULTICAST_AGGR_7_IP_TOP_GPDMA2_IRQ_28>,
			<GPDMA_GIA_MULTICAST_AGGR_7_IP_TOP_GPDMA2_IRQ_29>,
			<GPDMA_GIA_MULTICAST_AGGR_7_IP_TOP_GPDMA2_IRQ_30>,
			<GPDMA_GIA_MULTICAST_AGGR_7_IP_TOP_GPDMA2_IRQ_31>;
		interrupt-names =
			"GPDMA_GIA_MULTICAST_AGGR_7_IP_TOP_GPDMA2_IRQ_0",
			"GPDMA_GIA_MULTICAST_AGGR_7_IP_TOP_GPDMA2_IRQ_1",
			"GPDMA_GIA_MULTICAST_AGGR_7_IP_TOP_GPDMA2_IRQ_2",
			"GPDMA_GIA_MULTICAST_AGGR_7_IP_TOP_GPDMA2_IRQ_3",
			"GPDMA_GIA_MULTICAST_AGGR_7_IP_TOP_GPDMA2_IRQ_4",
			"GPDMA_GIA_MULTICAST_AGGR_7_IP_TOP_GPDMA2_IRQ_5",
			"GPDMA_GIA_MULTICAST_AGGR_7_IP_TOP_GPDMA2_IRQ_6",
			"GPDMA_GIA_MULTICAST_AGGR_7_IP_TOP_GPDMA2_IRQ_7",
			"GPDMA_GIA_MULTICAST_AGGR_7_IP_TOP_GPDMA2_IRQ_8",
			"GPDMA_GIA_MULTICAST_AGGR_7_IP_TOP_GPDMA2_IRQ_9",
			"GPDMA_GIA_MULTICAST_AGGR_7_IP_TOP_GPDMA2_IRQ_10",
			"GPDMA_GIA_MULTICAST_AGGR_7_IP_TOP_GPDMA2_IRQ_11",
			"GPDMA_GIA_MULTICAST_AGGR_7_IP_TOP_GPDMA2_IRQ_12",
			"GPDMA_GIA_MULTICAST_AGGR_7_IP_TOP_GPDMA2_IRQ_13",
			"GPDMA_GIA_MULTICAST_AGGR_7_IP_TOP_GPDMA2_IRQ_14",
			"GPDMA_GIA_MULTICAST_AGGR_7_IP_TOP_GPDMA2_IRQ_15",
			"GPDMA_GIA_MULTICAST_AGGR_7_IP_TOP_GPDMA2_IRQ_16",
			"GPDMA_GIA_MULTICAST_AGGR_7_IP_TOP_GPDMA2_IRQ_17",
			"GPDMA_GIA_MULTICAST_AGGR_7_IP_TOP_GPDMA2_IRQ_18",
			"GPDMA_GIA_MULTICAST_AGGR_7_IP_TOP_GPDMA2_IRQ_19",
			"GPDMA_GIA_MULTICAST_AGGR_7_IP_TOP_GPDMA2_IRQ_20",
			"GPDMA_GIA_MULTICAST_AGGR_7_IP_TOP_GPDMA2_IRQ_21",
			"GPDMA_GIA_MULTICAST_AGGR_7_IP_TOP_GPDMA2_IRQ_22",
			"GPDMA_GIA_MULTICAST_AGGR_7_IP_TOP_GPDMA2_IRQ_23",
			"GPDMA_GIA_MULTICAST_AGGR_7_IP_TOP_GPDMA2_IRQ_24",
			"GPDMA_GIA_MULTICAST_AGGR_7_IP_TOP_GPDMA2_IRQ_25",
			"GPDMA_GIA_MULTICAST_AGGR_7_IP_TOP_GPDMA2_IRQ_26",
			"GPDMA_GIA_MULTICAST_AGGR_7_IP_TOP_GPDMA2_IRQ_27",
			"GPDMA_GIA_MULTICAST_AGGR_7_IP_TOP_GPDMA2_IRQ_28",
			"GPDMA_GIA_MULTICAST_AGGR_7_IP_TOP_GPDMA2_IRQ_29",
			"GPDMA_GIA_MULTICAST_AGGR_7_IP_TOP_GPDMA2_IRQ_30",
			"GPDMA_GIA_MULTICAST_AGGR_7_IP_TOP_GPDMA2_IRQ_31";
	};

	gpdma_multicast_aggr_8_intr_test: gpdma_multicast_aggr_8_intr_test {
		compatible = "google,gia-test";
		power-domains = <&sswrp_gpdma_pd>;
		interrupt-parent = <&gpdma_multicast_aggr_8_intr>;
		interrupts =
			<GPDMA_GIA_MULTICAST_AGGR_8_IP_TOP_GPDMA3_IRQ_0>,
			<GPDMA_GIA_MULTICAST_AGGR_8_IP_TOP_GPDMA3_IRQ_1>,
			<GPDMA_GIA_MULTICAST_AGGR_8_IP_TOP_GPDMA3_IRQ_2>,
			<GPDMA_GIA_MULTICAST_AGGR_8_IP_TOP_GPDMA3_IRQ_3>,
			<GPDMA_GIA_MULTICAST_AGGR_8_IP_TOP_GPDMA3_IRQ_4>,
			<GPDMA_GIA_MULTICAST_AGGR_8_IP_TOP_GPDMA3_IRQ_5>,
			<GPDMA_GIA_MULTICAST_AGGR_8_IP_TOP_GPDMA3_IRQ_6>,
			<GPDMA_GIA_MULTICAST_AGGR_8_IP_TOP_GPDMA3_IRQ_7>,
			<GPDMA_GIA_MULTICAST_AGGR_8_IP_TOP_GPDMA3_IRQ_8>,
			<GPDMA_GIA_MULTICAST_AGGR_8_IP_TOP_GPDMA3_IRQ_9>,
			<GPDMA_GIA_MULTICAST_AGGR_8_IP_TOP_GPDMA3_IRQ_10>,
			<GPDMA_GIA_MULTICAST_AGGR_8_IP_TOP_GPDMA3_IRQ_11>,
			<GPDMA_GIA_MULTICAST_AGGR_8_IP_TOP_GPDMA3_IRQ_12>,
			<GPDMA_GIA_MULTICAST_AGGR_8_IP_TOP_GPDMA3_IRQ_13>,
			<GPDMA_GIA_MULTICAST_AGGR_8_IP_TOP_GPDMA3_IRQ_14>,
			<GPDMA_GIA_MULTICAST_AGGR_8_IP_TOP_GPDMA3_IRQ_15>,
			<GPDMA_GIA_MULTICAST_AGGR_8_IP_TOP_GPDMA3_IRQ_16>,
			<GPDMA_GIA_MULTICAST_AGGR_8_IP_TOP_GPDMA3_IRQ_17>,
			<GPDMA_GIA_MULTICAST_AGGR_8_IP_TOP_GPDMA3_IRQ_18>,
			<GPDMA_GIA_MULTICAST_AGGR_8_IP_TOP_GPDMA3_IRQ_19>,
			<GPDMA_GIA_MULTICAST_AGGR_8_IP_TOP_GPDMA3_IRQ_20>,
			<GPDMA_GIA_MULTICAST_AGGR_8_IP_TOP_GPDMA3_IRQ_21>,
			<GPDMA_GIA_MULTICAST_AGGR_8_IP_TOP_GPDMA3_IRQ_22>,
			<GPDMA_GIA_MULTICAST_AGGR_8_IP_TOP_GPDMA3_IRQ_23>,
			<GPDMA_GIA_MULTICAST_AGGR_8_IP_TOP_GPDMA3_IRQ_24>,
			<GPDMA_GIA_MULTICAST_AGGR_8_IP_TOP_GPDMA3_IRQ_25>,
			<GPDMA_GIA_MULTICAST_AGGR_8_IP_TOP_GPDMA3_IRQ_26>,
			<GPDMA_GIA_MULTICAST_AGGR_8_IP_TOP_GPDMA3_IRQ_27>,
			<GPDMA_GIA_MULTICAST_AGGR_8_IP_TOP_GPDMA3_IRQ_28>,
			<GPDMA_GIA_MULTICAST_AGGR_8_IP_TOP_GPDMA3_IRQ_29>,
			<GPDMA_GIA_MULTICAST_AGGR_8_IP_TOP_GPDMA3_IRQ_30>,
			<GPDMA_GIA_MULTICAST_AGGR_8_IP_TOP_GPDMA3_IRQ_31>;
		interrupt-names =
			"GPDMA_GIA_MULTICAST_AGGR_8_IP_TOP_GPDMA3_IRQ_0",
			"GPDMA_GIA_MULTICAST_AGGR_8_IP_TOP_GPDMA3_IRQ_1",
			"GPDMA_GIA_MULTICAST_AGGR_8_IP_TOP_GPDMA3_IRQ_2",
			"GPDMA_GIA_MULTICAST_AGGR_8_IP_TOP_GPDMA3_IRQ_3",
			"GPDMA_GIA_MULTICAST_AGGR_8_IP_TOP_GPDMA3_IRQ_4",
			"GPDMA_GIA_MULTICAST_AGGR_8_IP_TOP_GPDMA3_IRQ_5",
			"GPDMA_GIA_MULTICAST_AGGR_8_IP_TOP_GPDMA3_IRQ_6",
			"GPDMA_GIA_MULTICAST_AGGR_8_IP_TOP_GPDMA3_IRQ_7",
			"GPDMA_GIA_MULTICAST_AGGR_8_IP_TOP_GPDMA3_IRQ_8",
			"GPDMA_GIA_MULTICAST_AGGR_8_IP_TOP_GPDMA3_IRQ_9",
			"GPDMA_GIA_MULTICAST_AGGR_8_IP_TOP_GPDMA3_IRQ_10",
			"GPDMA_GIA_MULTICAST_AGGR_8_IP_TOP_GPDMA3_IRQ_11",
			"GPDMA_GIA_MULTICAST_AGGR_8_IP_TOP_GPDMA3_IRQ_12",
			"GPDMA_GIA_MULTICAST_AGGR_8_IP_TOP_GPDMA3_IRQ_13",
			"GPDMA_GIA_MULTICAST_AGGR_8_IP_TOP_GPDMA3_IRQ_14",
			"GPDMA_GIA_MULTICAST_AGGR_8_IP_TOP_GPDMA3_IRQ_15",
			"GPDMA_GIA_MULTICAST_AGGR_8_IP_TOP_GPDMA3_IRQ_16",
			"GPDMA_GIA_MULTICAST_AGGR_8_IP_TOP_GPDMA3_IRQ_17",
			"GPDMA_GIA_MULTICAST_AGGR_8_IP_TOP_GPDMA3_IRQ_18",
			"GPDMA_GIA_MULTICAST_AGGR_8_IP_TOP_GPDMA3_IRQ_19",
			"GPDMA_GIA_MULTICAST_AGGR_8_IP_TOP_GPDMA3_IRQ_20",
			"GPDMA_GIA_MULTICAST_AGGR_8_IP_TOP_GPDMA3_IRQ_21",
			"GPDMA_GIA_MULTICAST_AGGR_8_IP_TOP_GPDMA3_IRQ_22",
			"GPDMA_GIA_MULTICAST_AGGR_8_IP_TOP_GPDMA3_IRQ_23",
			"GPDMA_GIA_MULTICAST_AGGR_8_IP_TOP_GPDMA3_IRQ_24",
			"GPDMA_GIA_MULTICAST_AGGR_8_IP_TOP_GPDMA3_IRQ_25",
			"GPDMA_GIA_MULTICAST_AGGR_8_IP_TOP_GPDMA3_IRQ_26",
			"GPDMA_GIA_MULTICAST_AGGR_8_IP_TOP_GPDMA3_IRQ_27",
			"GPDMA_GIA_MULTICAST_AGGR_8_IP_TOP_GPDMA3_IRQ_28",
			"GPDMA_GIA_MULTICAST_AGGR_8_IP_TOP_GPDMA3_IRQ_29",
			"GPDMA_GIA_MULTICAST_AGGR_8_IP_TOP_GPDMA3_IRQ_30",
			"GPDMA_GIA_MULTICAST_AGGR_8_IP_TOP_GPDMA3_IRQ_31";
	};

	gpdma_multicast_aggr_9_intr_test: gpdma_multicast_aggr_9_intr_test {
		compatible = "google,gia-test";
		power-domains = <&sswrp_gpdma_pd>;
		interrupt-parent = <&gpdma_multicast_aggr_9_intr>;
		interrupts =
			<GPDMA_GIA_MULTICAST_AGGR_9_AUX_AON_LPCM_XFW_PWRAP_NS_INTR>,
			<GPDMA_GIA_MULTICAST_AGGR_9_AUX_GIA_PULSE_AGGR_1_INTR>,
			<GPDMA_GIA_MULTICAST_AGGR_9_AUX_NIC_XFW_AWRAP_NS_INTR>,
			<GPDMA_GIA_MULTICAST_AGGR_9_AUX_TBU_SS_TBU_MFW_NS_INTR>,
			<GPDMA_GIA_MULTICAST_AGGR_9_AUX_TBU_SS_RA_NS_INTR>,
			<GPDMA_GIA_MULTICAST_AGGR_9_AUX_TBU_SS_GEM_IRQ>,
			<GPDMA_GIA_MULTICAST_AGGR_9_AUX_CPSYSSGPDMA_SYSS_GPDMATOP_XBA0_ERR_IRQ>,
			<GPDMA_GIA_MULTICAST_AGGR_9_IP_TOP_GPDMA0_IRQ_ABORT>,
			<GPDMA_GIA_MULTICAST_AGGR_9_IP_TOP_GPDMA1_IRQ_ABORT>,
			<GPDMA_GIA_MULTICAST_AGGR_9_IP_TOP_GPDMA2_IRQ_ABORT>,
			<GPDMA_GIA_MULTICAST_AGGR_9_IP_TOP_GPDMA3_IRQ_ABORT>,
			<31>;
		interrupt-names =
			"GPDMA_GIA_MULTICAST_AGGR_9_AUX_AON_LPCM_XFW_PWRAP_NS_INTR",
			"GPDMA_GIA_MULTICAST_AGGR_9_AUX_GIA_PULSE_AGGR_1_INTR",
			"GPDMA_GIA_MULTICAST_AGGR_9_AUX_NIC_XFW_AWRAP_NS_INTR",
			"GPDMA_GIA_MULTICAST_AGGR_9_AUX_TBU_SS_TBU_MFW_NS_INTR",
			"GPDMA_GIA_MULTICAST_AGGR_9_AUX_TBU_SS_RA_NS_INTR",
			"GPDMA_GIA_MULTICAST_AGGR_9_AUX_TBU_SS_GEM_IRQ",
			"GPDMA_GIA_MULTICAST_AGGR_9_AUX_CPSYSSGPDMA_SYSS_GPDMATOP_XBA0_ERR_IRQ",
			"GPDMA_GIA_MULTICAST_AGGR_9_IP_TOP_GPDMA0_IRQ_ABORT",
			"GPDMA_GIA_MULTICAST_AGGR_9_IP_TOP_GPDMA1_IRQ_ABORT",
			"GPDMA_GIA_MULTICAST_AGGR_9_IP_TOP_GPDMA2_IRQ_ABORT",
			"GPDMA_GIA_MULTICAST_AGGR_9_IP_TOP_GPDMA3_IRQ_ABORT",
			"TEST_LINE_31";
	};

	gpdma_pulse_aggr_1_intr_test: gpdma_pulse_aggr_1_intr_test {
		compatible = "google,gia-test";
		power-domains = <&sswrp_gpdma_pd>;
		interrupt-parent = <&gpdma_pulse_aggr_1_intr>;
		interrupts =
			<GPDMA_GIA_PULSE_AGGR_1_AUX_GSPAN_AXI_INI_ICD_ERR_DSCGT>,
			<GPDMA_GIA_PULSE_AGGR_1_AUX_TBU_SS_TBU_TBU_RAS_FHI>,
			<GPDMA_GIA_PULSE_AGGR_1_AUX_TBU_SS_TBU_TBU_RAS_ERI>,
			<GPDMA_GIA_PULSE_AGGR_1_AUX_TBU_SS_TBU_TBU_RAS_CRI>,
			<GPDMA_GIA_PULSE_AGGR_1_AUX_TBU_SS_TBU_TBU_PMU_IRPT>,
			<31>;
		interrupt-names =
			"GPDMA_GIA_PULSE_AGGR_1_AUX_GSPAN_AXI_INI_ICD_ERR_DSCGT",
			"GPDMA_GIA_PULSE_AGGR_1_AUX_TBU_SS_TBU_TBU_RAS_FHI",
			"GPDMA_GIA_PULSE_AGGR_1_AUX_TBU_SS_TBU_TBU_RAS_ERI",
			"GPDMA_GIA_PULSE_AGGR_1_AUX_TBU_SS_TBU_TBU_RAS_CRI",
			"GPDMA_GIA_PULSE_AGGR_1_AUX_TBU_SS_TBU_TBU_PMU_IRPT",
			"TEST_LINE_31";
	};

	gpu_level_aggr_3_intr_test: gpu_level_aggr_3_intr_test {
		compatible = "google,gia-test";
		power-domains = <&sswrp_gpu_pd>;
		interrupt-parent = <&gpu_level_aggr_3_intr>;
		interrupts =
			<GPU_GIA_LEVEL_AGGR_3_AUX_AON_LPCM_PWRAP_RFW_G0R128_NS_INTR>,
			<GPU_GIA_LEVEL_AGGR_3_AUX_AON_AON_PWRAP_RFW_G0R32_NS_INTR>,
			<GPU_GIA_LEVEL_AGGR_3_DUMMY_GIA_LEVEL_AGGR_11_INTR>;
		interrupt-names =
			"GPU_GIA_LEVEL_AGGR_3_AUX_AON_LPCM_PWRAP_RFW_G0R128_NS_INTR",
			"GPU_GIA_LEVEL_AGGR_3_AUX_AON_AON_PWRAP_RFW_G0R32_NS_INTR",
			"GPU_GIA_LEVEL_AGGR_3_DUMMY_GIA_LEVEL_AGGR_11_INTR";
	};

	gpu_level_aggr_11_intr_test: gpu_level_aggr_11_intr_test {
		compatible = "google,gia-test";
		power-domains = <&sswrp_gpu_pd>;
		interrupt-parent = <&gpu_level_aggr_11_intr>;
		interrupts =
			<GPU_GIA_LEVEL_AGGR_11_AUX_APB2MAPB_PWRAP_RFW_G0R1280_NS_INTR>,
			<GPU_GIA_LEVEL_AGGR_11_AUX_TOP_AWRAP_RFW_G0R512_NS_INTR>,
			<GPU_GIA_LEVEL_AGGR_11_AUX_DS_INST_RA_TOP_0_NS_INTR>,
			<GPU_GIA_LEVEL_AGGR_11_AUX_DS_INST_RA_TOP_1_NS_INTR>,
			<GPU_GIA_LEVEL_AGGR_11_AUX_DS_INST_RA_TOP_2_NS_INTR>,
			<GPU_GIA_LEVEL_AGGR_11_AUX_DS_INST_GEM_TOP_TBU_MST0_IRQ>,
			<GPU_GIA_LEVEL_AGGR_11_AUX_DS_INST_GEM_TOP_TBU_MST1_IRQ>,
			<GPU_GIA_LEVEL_AGGR_11_AUX_DS_INST_GEM_TOP_TBU_MST2_IRQ>,
			<GPU_GIA_LEVEL_AGGR_11_AUX_DS_INST_GEM_TOP_TCU_INST_IRQ>,
			<GPU_GIA_LEVEL_AGGR_11_DUMMY_GIA_PULSE_AGGR_0_INTR>,
			<GPU_GIA_LEVEL_AGGR_11_DUMMY_GIA_PULSE_AGGR_1_INTR>,
			<GPU_GIA_LEVEL_AGGR_11_DUMMY_GIA_PULSE_AGGR_2_INTR>,
			<GPU_GIA_LEVEL_AGGR_11_DUMMY_GIA_PULSE_AGGR_4_INTR>,
			<GPU_GIA_LEVEL_AGGR_11_DUMMY_GIA_PULSE_AGGR_5_INTR>,
			<GPU_GIA_LEVEL_AGGR_11_AUX_DS_INST_CPHBWGPU_IFABRIC_HBW_CTRL_PLANE_FABRIC_INTR>,
			<GPU_GIA_LEVEL_AGGR_11_AUX_DS_INST_IFABRIC_FABWRPGPU_IWLINK_FABRIC_INTR>;
		interrupt-names =
			"GPU_GIA_LEVEL_AGGR_11_AUX_APB2MAPB_PWRAP_RFW_G0R1280_NS_INTR",
			"GPU_GIA_LEVEL_AGGR_11_AUX_TOP_AWRAP_RFW_G0R512_NS_INTR",
			"GPU_GIA_LEVEL_AGGR_11_AUX_DS_INST_RA_TOP_0_NS_INTR",
			"GPU_GIA_LEVEL_AGGR_11_AUX_DS_INST_RA_TOP_1_NS_INTR",
			"GPU_GIA_LEVEL_AGGR_11_AUX_DS_INST_RA_TOP_2_NS_INTR",
			"GPU_GIA_LEVEL_AGGR_11_AUX_DS_INST_GEM_TOP_TBU_MST0_IRQ",
			"GPU_GIA_LEVEL_AGGR_11_AUX_DS_INST_GEM_TOP_TBU_MST1_IRQ",
			"GPU_GIA_LEVEL_AGGR_11_AUX_DS_INST_GEM_TOP_TBU_MST2_IRQ",
			"GPU_GIA_LEVEL_AGGR_11_AUX_DS_INST_GEM_TOP_TCU_INST_IRQ",
			"GPU_GIA_LEVEL_AGGR_11_DUMMY_GIA_PULSE_AGGR_0_INTR",
			"GPU_GIA_LEVEL_AGGR_11_DUMMY_GIA_PULSE_AGGR_1_INTR",
			"GPU_GIA_LEVEL_AGGR_11_DUMMY_GIA_PULSE_AGGR_2_INTR",
			"GPU_GIA_LEVEL_AGGR_11_DUMMY_GIA_PULSE_AGGR_4_INTR",
			"GPU_GIA_LEVEL_AGGR_11_DUMMY_GIA_PULSE_AGGR_5_INTR",
			"GPU_GIA_LEVEL_AGGR_11_AUX_DS_INST_CPHBWGPU_IFABRIC_HBW_CTRL_PLANE_FABRIC_INTR",
			"GPU_GIA_LEVEL_AGGR_11_AUX_DS_INST_IFABRIC_FABWRPGPU_IWLINK_FABRIC_INTR";
	};

	gpu_pulse_aggr_4_intr_test: gpu_pulse_aggr_4_intr_test {
		compatible = "google,gia-test";
		power-domains = <&sswrp_gpu_pd>;
		interrupt-parent = <&gpu_pulse_aggr_4_intr>;
		interrupts =
			<GPU_GIA_PULSE_AGGR_4_AUX_DS_INST_SMMU_TCU_PMU_IRPT>,
			<GPU_GIA_PULSE_AGGR_4_AUX_DS_INST_SMMU_TCU_RAS_CRI>,
			<GPU_GIA_PULSE_AGGR_4_AUX_DS_INST_SMMU_TCU_RAS_ERI>,
			<GPU_GIA_PULSE_AGGR_4_AUX_DS_INST_SMMU_TCU_RAS_FHI>,
			<GPU_GIA_PULSE_AGGR_4_AUX_DS_INST_SMMU_TCU_GLOBAL_IRPT_NS>,
			<GPU_GIA_PULSE_AGGR_4_AUX_DS_INST_SMMU_TCU_CMD_SYNC_IRPT_NS>,
			<GPU_GIA_PULSE_AGGR_4_AUX_DS_INST_SMMU_TCU_EVENT_Q_IRPT_NS>;
		interrupt-names =
			"GPU_GIA_PULSE_AGGR_4_AUX_DS_INST_SMMU_TCU_PMU_IRPT",
			"GPU_GIA_PULSE_AGGR_4_AUX_DS_INST_SMMU_TCU_RAS_CRI",
			"GPU_GIA_PULSE_AGGR_4_AUX_DS_INST_SMMU_TCU_RAS_ERI",
			"GPU_GIA_PULSE_AGGR_4_AUX_DS_INST_SMMU_TCU_RAS_FHI",
			"GPU_GIA_PULSE_AGGR_4_AUX_DS_INST_SMMU_TCU_GLOBAL_IRPT_NS",
			"GPU_GIA_PULSE_AGGR_4_AUX_DS_INST_SMMU_TCU_CMD_SYNC_IRPT_NS",
			"GPU_GIA_PULSE_AGGR_4_AUX_DS_INST_SMMU_TCU_EVENT_Q_IRPT_NS";
	};

	eh_multicast_aggr_3_intr_test: eh_multicast_aggr_3_intr_test {
		compatible = "google,gia-test";
		power-domains = <&sswrp_eh_pd>;
		interrupt-parent = <&eh_multicast_aggr_3_intr>;
		interrupts =
			<EH_GIA_MULTICAST_AGGR_3_AUX_RFW_LPCM_IRQ_NS>,
			<EH_GIA_MULTICAST_AGGR_3_AUX_RFW_AWRAP_NS_INTR>,
			<EH_GIA_MULTICAST_AGGR_3_AUX_RA_NS_INTR>,
			<EH_GIA_MULTICAST_AGGR_3_AUX_GEM_IRQ>,
			<EH_GIA_MULTICAST_AGGR_3_AUX_TOP_INST_IRQ_0>,
			<EH_GIA_MULTICAST_AGGR_3_AUX_GIA_PULSE_AGGR_0_INTR>,
			<EH_GIA_MULTICAST_AGGR_3_AUX_IFABRIC_XBA0_ERR_IRQ>,
			<31>;
		interrupt-names =
			"EH_GIA_MULTICAST_AGGR_3_AUX_RFW_LPCM_IRQ_NS",
			"EH_GIA_MULTICAST_AGGR_3_AUX_RFW_AWRAP_NS_INTR",
			"EH_GIA_MULTICAST_AGGR_3_AUX_RA_NS_INTR",
			"EH_GIA_MULTICAST_AGGR_3_AUX_GEM_IRQ",
			"EH_GIA_MULTICAST_AGGR_3_AUX_TOP_INST_IRQ_0",
			"EH_GIA_MULTICAST_AGGR_3_AUX_GIA_PULSE_AGGR_0_INTR",
			"EH_GIA_MULTICAST_AGGR_3_AUX_IFABRIC_XBA0_ERR_IRQ",
			"TEST_LINE_31";
	};

	eh_pulse_aggr_0_intr_test: eh_pulse_aggr_0_intr_test {
		compatible = "google,gia-test";
		power-domains = <&sswrp_eh_pd>;
		interrupt-parent = <&eh_pulse_aggr_0_intr>;
		interrupts =
			<EH_GIA_PULSE_AGGR_0_AUX_TBU_TBU_PMU_IRPT>,
			<EH_GIA_PULSE_AGGR_0_AUX_TBU_TBU_RAS_CRI>,
			<EH_GIA_PULSE_AGGR_0_AUX_TBU_TBU_RAS_ERI>,
			<EH_GIA_PULSE_AGGR_0_AUX_TBU_TBU_RAS_FHI>,
			<EH_GIA_PULSE_AGGR_0_AUX_GSPAN_AXI_INITIATOR_INST_ICD_ERR_DSCGT>,
			<EH_GIA_PULSE_AGGR_0_AUX_GSPAN_ATB_INITIATOR_INST_ICD_ERR_DSCGT>,
			<31>;
		interrupt-names =
			"EH_GIA_PULSE_AGGR_0_AUX_TBU_TBU_PMU_IRPT",
			"EH_GIA_PULSE_AGGR_0_AUX_TBU_TBU_RAS_CRI",
			"EH_GIA_PULSE_AGGR_0_AUX_TBU_TBU_RAS_ERI",
			"EH_GIA_PULSE_AGGR_0_AUX_TBU_TBU_RAS_FHI",
			"EH_GIA_PULSE_AGGR_0_AUX_GSPAN_AXI_INITIATOR_INST_ICD_ERR_DSCGT",
			"EH_GIA_PULSE_AGGR_0_AUX_GSPAN_ATB_INITIATOR_INST_ICD_ERR_DSCGT",
			"TEST_LINE_31";
	};

	hsion_pulse_aggr_3_intr_test: hsion_pulse_aggr_3_intr_test {
		compatible = "google,gia-test";
		interrupt-parent = <&hsion_pulse_aggr_3_intr>;
		interrupts =
			<HSIO_N_GIA_PULSE_AGGR_3_AUX_GSPAN_PCIE0_INITIATOR_ICD_ERR_DSCGT>,
			<HSIO_N_GIA_PULSE_AGGR_3_AUX_USBM_ACCESS_CNTL_TBU_TBU_RAS_ERI>,
			<HSIO_N_GIA_PULSE_AGGR_3_AUX_USBM_ACCESS_CNTL_TBU_TBU_RAS_CRI>,
			<HSIO_N_GIA_PULSE_AGGR_3_AUX_USBM_ACCESS_CNTL_TBU_TBU_PMU_IRPT>,
			<HSIO_N_GIA_PULSE_AGGR_3_AUX_HSION_PCIE0_TRGT_CPL_TIMEOUT_INT_TRIG>,
			<HSIO_N_GIA_PULSE_AGGR_3_AUX_HSION_PCIE0_SMLH_REQ_RST>,
			<HSIO_N_GIA_PULSE_AGGR_3_AUX_HSION_GSPAN_USB_INITIATOR_ICD_ERR_DSCGT>,
			<HSIO_N_GIA_PULSE_AGGR_3_AUX_HSION_PCIE0_RADM_INTA_ASSERTED_INT_TRIG>,
			<HSIO_N_GIA_PULSE_AGGR_3_AUX_HSION_PCIE0_RADM_INTA_DEASSERTED_INT_TRIG>,
			<HSIO_N_GIA_PULSE_AGGR_3_AUX_HSION_PCIE0_RADM_INTB_ASSERTED_INT_TRIG>,
			<HSIO_N_GIA_PULSE_AGGR_3_AUX_HSION_PCIE0_RADM_INTB_DEASSERTED_INT_TRIG>,
			<HSIO_N_GIA_PULSE_AGGR_3_AUX_HSION_PCIE0_RADM_INTC_ASSERTED_INT_TRIG>,
			<HSIO_N_GIA_PULSE_AGGR_3_AUX_HSION_PCIE0_RADM_INTC_DEASSERTED_INT_TRIG>,
			<HSIO_N_GIA_PULSE_AGGR_3_AUX_HSION_PCIE0_RADM_INTD_ASSERTED_INT_TRIG>,
			<HSIO_N_GIA_PULSE_AGGR_3_AUX_HSION_PCIE0_RADM_INTD_DEASSERTED_INT_TRIG>,
			<HSIO_N_GIA_PULSE_AGGR_3_AUX_HSION_PCIE0_RADM_VENDOR_MSG_INT>,
			<HSIO_N_GIA_PULSE_AGGR_3_AUX_EBU_INIT_PULSE_SYNC_RPULSE>,
			<HSIO_N_GIA_PULSE_AGGR_3_AUX_HSION_PCIE0_HP_MSI_TRIG>,
			<HSIO_N_GIA_PULSE_AGGR_3_AUX_HSION_PCIE0_HP_PME_TRIG>,
			<HSIO_N_GIA_PULSE_AGGR_3_AUX_GSPAN_ILINK_ENDPOINT_RX_ERR>,
			<HSIO_N_GIA_PULSE_AGGR_3_AUX_CTL_PLANE_AGG4_IWL_TX_ERR>,
			<HSIO_N_GIA_PULSE_AGGR_3_AUX_GSPAN_ATB_INITIATOR_ICD_ERR_DSCGT>,
			<HSIO_N_GIA_PULSE_AGGR_3_AUX_AXIM_ACCESS_CNTL_PCIE_TBU_TBU_RAS_FHI>,
			<HSIO_N_GIA_PULSE_AGGR_3_AUX_AXIM_ACCESS_CNTL_PCIE_TBU_TBU_RAS_ERI>,
			<HSIO_N_GIA_PULSE_AGGR_3_AUX_AXIM_ACCESS_CNTL_PCIE_TBU_TBU_RAS_CRI>,
			<HSIO_N_GIA_PULSE_AGGR_3_AUX_AXIM_ACCESS_CNTL_PCIE_TBU_TBU_PMU_IRPT>,
			<HSIO_N_GIA_PULSE_AGGR_3_AUX_USBM_ACCESS_CNTL_TBU_TBU_RAS_FHI>,
			<31>;
		interrupt-names =
			"HSIO_N_GIA_PULSE_AGGR_3_AUX_GSPAN_PCIE0_INITIATOR_ICD_ERR_DSCGT",
			"HSIO_N_GIA_PULSE_AGGR_3_AUX_USBM_ACCESS_CNTL_TBU_TBU_RAS_ERI",
			"HSIO_N_GIA_PULSE_AGGR_3_AUX_USBM_ACCESS_CNTL_TBU_TBU_RAS_CRI",
			"HSIO_N_GIA_PULSE_AGGR_3_AUX_USBM_ACCESS_CNTL_TBU_TBU_PMU_IRPT",
			"HSIO_N_GIA_PULSE_AGGR_3_AUX_HSION_PCIE0_TRGT_CPL_TIMEOUT_INT_TRIG",
			"HSIO_N_GIA_PULSE_AGGR_3_AUX_HSION_PCIE0_SMLH_REQ_RST",
			"HSIO_N_GIA_PULSE_AGGR_3_AUX_HSION_GSPAN_USB_INITIATOR_ICD_ERR_DSCGT",
			"HSIO_N_GIA_PULSE_AGGR_3_AUX_HSION_PCIE0_RADM_INTA_ASSERTED_INT_TRIG",
			"HSIO_N_GIA_PULSE_AGGR_3_AUX_HSION_PCIE0_RADM_INTA_DEASSERTED_INT_TRIG",
			"HSIO_N_GIA_PULSE_AGGR_3_AUX_HSION_PCIE0_RADM_INTB_ASSERTED_INT_TRIG",
			"HSIO_N_GIA_PULSE_AGGR_3_AUX_HSION_PCIE0_RADM_INTB_DEASSERTED_INT_TRIG",
			"HSIO_N_GIA_PULSE_AGGR_3_AUX_HSION_PCIE0_RADM_INTC_ASSERTED_INT_TRIG",
			"HSIO_N_GIA_PULSE_AGGR_3_AUX_HSION_PCIE0_RADM_INTC_DEASSERTED_INT_TRIG",
			"HSIO_N_GIA_PULSE_AGGR_3_AUX_HSION_PCIE0_RADM_INTD_ASSERTED_INT_TRIG",
			"HSIO_N_GIA_PULSE_AGGR_3_AUX_HSION_PCIE0_RADM_INTD_DEASSERTED_INT_TRIG",
			"HSIO_N_GIA_PULSE_AGGR_3_AUX_HSION_PCIE0_RADM_VENDOR_MSG_INT",
			"HSIO_N_GIA_PULSE_AGGR_3_AUX_EBU_INIT_PULSE_SYNC_RPULSE",
			"HSIO_N_GIA_PULSE_AGGR_3_AUX_HSION_PCIE0_HP_MSI_TRIG",
			"HSIO_N_GIA_PULSE_AGGR_3_AUX_HSION_PCIE0_HP_PME_TRIG",
			"HSIO_N_GIA_PULSE_AGGR_3_AUX_GSPAN_ILINK_ENDPOINT_RX_ERR",
			"HSIO_N_GIA_PULSE_AGGR_3_AUX_CTL_PLANE_AGG4_IWL_TX_ERR",
			"HSIO_N_GIA_PULSE_AGGR_3_AUX_GSPAN_ATB_INITIATOR_ICD_ERR_DSCGT",
			"HSIO_N_GIA_PULSE_AGGR_3_AUX_AXIM_ACCESS_CNTL_PCIE_TBU_TBU_RAS_FHI",
			"HSIO_N_GIA_PULSE_AGGR_3_AUX_AXIM_ACCESS_CNTL_PCIE_TBU_TBU_RAS_ERI",
			"HSIO_N_GIA_PULSE_AGGR_3_AUX_AXIM_ACCESS_CNTL_PCIE_TBU_TBU_RAS_CRI",
			"HSIO_N_GIA_PULSE_AGGR_3_AUX_AXIM_ACCESS_CNTL_PCIE_TBU_TBU_PMU_IRPT",
			"HSIO_N_GIA_PULSE_AGGR_3_AUX_USBM_ACCESS_CNTL_TBU_TBU_RAS_FHI",
			"TEST_LINE_31";
	};

	hsion_pulse_aggr_4_intr_test: hsion_pulse_aggr_4_intr_test {
		compatible = "google,gia-test";
		interrupt-parent = <&hsion_pulse_aggr_4_intr>;
		interrupts =
			<HSIO_N_GIA_PULSE_AGGR_4_AUX_PCIE0_CFG_AER_RC_ERR_MSI_INT>,
			<HSIO_N_GIA_PULSE_AGGR_4_AUX_PCIE0_CFG_BW_MGT_MSI_INT>,
			<HSIO_N_GIA_PULSE_AGGR_4_AUX_PCIE0_CFG_LINK_AUTO_BW_MSI_INT>,
			<HSIO_N_GIA_PULSE_AGGR_4_AUX_PCIE0_CFG_PME_MSI_INT>,
			<HSIO_N_GIA_PULSE_AGGR_4_AUX_HSION_PCIE0_CFG_SYS_ERR_RC_INT_TRIG>,
			<HSIO_N_GIA_PULSE_AGGR_4_AUX_HSION_PCIE0_RADM_CORRECTABLE_ERR_INT_TRIG>,
			<HSIO_N_GIA_PULSE_AGGR_4_AUX_HSION_PCIE0_RADM_CPL_TIMEOUT_INT_TRIG>,
			<HSIO_N_GIA_PULSE_AGGR_4_AUX_HSION_PCIE0_RADM_FATAL_ERR_INT_TRIG>,
			<HSIO_N_GIA_PULSE_AGGR_4_AUX_HSION_PCIE0_RADM_NONFATAL_ERR_INT_TRIG>,
			<31>;
		interrupt-names =
			"HSIO_N_GIA_PULSE_AGGR_4_AUX_PCIE0_CFG_AER_RC_ERR_MSI_INT",
			"HSIO_N_GIA_PULSE_AGGR_4_AUX_PCIE0_CFG_BW_MGT_MSI_INT",
			"HSIO_N_GIA_PULSE_AGGR_4_AUX_PCIE0_CFG_LINK_AUTO_BW_MSI_INT",
			"HSIO_N_GIA_PULSE_AGGR_4_AUX_PCIE0_CFG_PME_MSI_INT",
			"HSIO_N_GIA_PULSE_AGGR_4_AUX_HSION_PCIE0_CFG_SYS_ERR_RC_INT_TRIG",
			"HSIO_N_GIA_PULSE_AGGR_4_AUX_HSION_PCIE0_RADM_CORRECTABLE_ERR_INT_TRIG",
			"HSIO_N_GIA_PULSE_AGGR_4_AUX_HSION_PCIE0_RADM_CPL_TIMEOUT_INT_TRIG",
			"HSIO_N_GIA_PULSE_AGGR_4_AUX_HSION_PCIE0_RADM_FATAL_ERR_INT_TRIG",
			"HSIO_N_GIA_PULSE_AGGR_4_AUX_HSION_PCIE0_RADM_NONFATAL_ERR_INT_TRIG",
			"TEST_LINE_31";
	};

	hsion_multicast_aggr_7_intr_test: hsion_multicast_aggr_7_intr_test {
		compatible = "google,gia-test";
		interrupt-parent = <&hsion_multicast_aggr_7_intr>;
		interrupts =
			<HSIO_N_GIA_MULTICAST_AGGR_7_AUX_LPCM_RFW_NS_INTR>,
			<HSIO_N_GIA_MULTICAST_AGGR_7_AUX_HDCP_MFW_NS_INTR>,
			<HSIO_N_GIA_MULTICAST_AGGR_7_AUX_AXIM_ACCESS_CNTL_PCIE_RA_NS_INTR>,
			<HSIO_N_GIA_MULTICAST_AGGR_7_AUX_USBM_ACCESS_CNTL_RA_NS_INTR>,
			<HSIO_N_GIA_MULTICAST_AGGR_7_AUX_AXIM_ACCESS_CNTL_PCIE_GEM_IRQ>,
			<HSIO_N_GIA_MULTICAST_AGGR_7_AUX_USBM_ACCESS_CNTL_GEM_IRQ>,
			<HSIO_N_GIA_MULTICAST_AGGR_7_AUX_PCIESLV_GEM_IRQ>,
			<HSIO_N_GIA_MULTICAST_AGGR_7_AUX_CTL_PLANE_XBA0_ERR_IRQ>,
			<HSIO_N_GIA_MULTICAST_AGGR_7_AUX_PCIE0_DBI_RFW_NS_INTR>,
			<HSIO_N_GIA_MULTICAST_AGGR_7_AUX_DTA_TOP_ELA600_ELAOUTPUT>,
			<HSIO_N_GIA_MULTICAST_AGGR_7_AUX_HSION_PCIE0_MSI_CTRL_INT>,
			<HSIO_N_GIA_MULTICAST_AGGR_7_AUX_USB_NIC_RFW_NS_INTR>,
			<HSIO_N_GIA_MULTICAST_AGGR_7_AUX_HSION_PCIE0_HP_INT>,
			<HSIO_N_GIA_MULTICAST_AGGR_7_AUX_HSION_PCIE0_CFG_AER_RC_ERR_INT_TRIG>,
			<HSIO_N_GIA_MULTICAST_AGGR_7_AUX_PCIE_NIC_RFW_NS_INTR>,
			<HSIO_N_GIA_MULTICAST_AGGR_7_AUX_GENIP_RFW_NS_INTR>,
			<HSIO_N_GIA_MULTICAST_AGGR_7_AUX_GEMIP_RFW_NS_INTR>,
			<HSIO_N_GIA_MULTICAST_AGGR_7_AUX_DP_NIC_RFW_NS_INTR>,
			<HSIO_N_GIA_MULTICAST_AGGR_7_AUX_AXIM_ACCESS_CNTL_PCIE_MFW_NS_INTR>,
			<HSIO_N_GIA_MULTICAST_AGGR_7_AUX_USBM_ACCESS_CNTL_MFW_NS_INTR>,
			<HSIO_N_GIA_MULTICAST_AGGR_7_AUX_PCIE_SLV_MFW_NS_INTR>,
			<31>;
		interrupt-names =
			"HSIO_N_GIA_MULTICAST_AGGR_7_AUX_LPCM_RFW_NS_INTR",
			"HSIO_N_GIA_MULTICAST_AGGR_7_AUX_HDCP_MFW_NS_INTR",
			"HSIO_N_GIA_MULTICAST_AGGR_7_AUX_AXIM_ACCESS_CNTL_PCIE_RA_NS_INTR",
			"HSIO_N_GIA_MULTICAST_AGGR_7_AUX_USBM_ACCESS_CNTL_RA_NS_INTR",
			"HSIO_N_GIA_MULTICAST_AGGR_7_AUX_AXIM_ACCESS_CNTL_PCIE_GEM_IRQ",
			"HSIO_N_GIA_MULTICAST_AGGR_7_AUX_USBM_ACCESS_CNTL_GEM_IRQ",
			"HSIO_N_GIA_MULTICAST_AGGR_7_AUX_PCIESLV_GEM_IRQ",
			"HSIO_N_GIA_MULTICAST_AGGR_7_AUX_CTL_PLANE_XBA0_ERR_IRQ",
			"HSIO_N_GIA_MULTICAST_AGGR_7_AUX_PCIE0_DBI_RFW_NS_INTR",
			"HSIO_N_GIA_MULTICAST_AGGR_7_AUX_DTA_TOP_ELA600_ELAOUTPUT",
			"HSIO_N_GIA_MULTICAST_AGGR_7_AUX_HSION_PCIE0_MSI_CTRL_INT",
			"HSIO_N_GIA_MULTICAST_AGGR_7_AUX_USB_NIC_RFW_NS_INTR",
			"HSIO_N_GIA_MULTICAST_AGGR_7_AUX_HSION_PCIE0_HP_INT",
			"HSIO_N_GIA_MULTICAST_AGGR_7_AUX_HSION_PCIE0_CFG_AER_RC_ERR_INT_TRIG",
			"HSIO_N_GIA_MULTICAST_AGGR_7_AUX_PCIE_NIC_RFW_NS_INTR",
			"HSIO_N_GIA_MULTICAST_AGGR_7_AUX_GENIP_RFW_NS_INTR",
			"HSIO_N_GIA_MULTICAST_AGGR_7_AUX_GEMIP_RFW_NS_INTR",
			"HSIO_N_GIA_MULTICAST_AGGR_7_AUX_DP_NIC_RFW_NS_INTR",
			"HSIO_N_GIA_MULTICAST_AGGR_7_AUX_AXIM_ACCESS_CNTL_PCIE_MFW_NS_INTR",
			"HSIO_N_GIA_MULTICAST_AGGR_7_AUX_USBM_ACCESS_CNTL_MFW_NS_INTR",
			"HSIO_N_GIA_MULTICAST_AGGR_7_AUX_PCIE_SLV_MFW_NS_INTR",
			"TEST_LINE_31";
	};

	hsion_multicast_aggr_8_intr_test: hsion_multicast_aggr_8_intr_test {
		compatible = "google,gia-test";
		interrupt-parent = <&hsion_multicast_aggr_8_intr>;
		interrupts =
			<HSIO_N_GIA_MULTICAST_AGGR_8_AUX_HSION_PCIE0_EDMA_INT>,
			<HSIO_N_GIA_MULTICAST_AGGR_8_AUX_HSION_PCIE0_CFG_BW_MGT_INT>,
			<HSIO_N_GIA_MULTICAST_AGGR_8_AUX_HSION_PCIE0_CFG_LINK_AUTO_BW_INT>,
			<HSIO_N_GIA_MULTICAST_AGGR_8_AUX_HSION_PCIE0_CFG_LINK_EQ_REQ_INT>,
			<HSIO_N_GIA_MULTICAST_AGGR_8_AUX_HSION_PCIE0_CFG_PME_INT>,
			<HSIO_N_GIA_MULTICAST_AGGR_8_AUX_HSION_PCIE0_USP_EQ_REDO_EXECUTED_INT>,
			<HSIO_N_GIA_MULTICAST_AGGR_8_AUX_HSION_PCIE0_RADM_MSG_LTR_INT>,
			<HSIO_N_GIA_MULTICAST_AGGR_8_AUX_HSION_BK_XHSION_GPIO0_IRQ>,
			<HSIO_N_GIA_MULTICAST_AGGR_8_AUX_HSION_BK_XHSION_GPIO1_IRQ>,
			<HSIO_N_GIA_MULTICAST_AGGR_8_AUX_HSION_BK_XHSION_GPIO2_IRQ>,
			<HSIO_N_GIA_MULTICAST_AGGR_8_AUX_HSION_BK_XHSION_GPIO3_IRQ>,
			<HSIO_N_GIA_MULTICAST_AGGR_8_AUX_HSION_BK_XHSION_GPIO4_IRQ>,
			<HSIO_N_GIA_MULTICAST_AGGR_8_AUX_HSION_BK_XHSION_GPIO5_IRQ>,
			<HSIO_N_GIA_MULTICAST_AGGR_8_AUX_HSION_BK_XHSION_GPIO6_IRQ>,
			<HSIO_N_GIA_MULTICAST_AGGR_8_AUX_HSION_BK_XHSION_GPIO7_IRQ>,
			<HSIO_N_GIA_MULTICAST_AGGR_8_AUX_HSION_BK_XHSION_GPIO8_IRQ>,
			<HSIO_N_GIA_MULTICAST_AGGR_8_AUX_HSION_BK_XHSION_PCIE0_CLKREQN0_IRQ>,
			<HSIO_N_GIA_MULTICAST_AGGR_8_AUX_HSION_BK_XHSION_PCIE0_PERSTN0_IRQ>,
			<HSIO_N_GIA_MULTICAST_AGGR_8_AUX_HSION_EBU_TOP_INTR>,
			<HSIO_N_GIA_MULTICAST_AGGR_8_AUX_HSION_DP_INTERRUPT_O>,
			<HSIO_N_GIA_MULTICAST_AGGR_8_AUX_HSION_PCIE0_MSI_CTRL_INT_VEC>,
			<31>;
		interrupt-names =
			"HSIO_N_GIA_MULTICAST_AGGR_8_AUX_HSION_PCIE0_EDMA_INT",
			"HSIO_N_GIA_MULTICAST_AGGR_8_AUX_HSION_PCIE0_CFG_BW_MGT_INT",
			"HSIO_N_GIA_MULTICAST_AGGR_8_AUX_HSION_PCIE0_CFG_LINK_AUTO_BW_INT",
			"HSIO_N_GIA_MULTICAST_AGGR_8_AUX_HSION_PCIE0_CFG_LINK_EQ_REQ_INT",
			"HSIO_N_GIA_MULTICAST_AGGR_8_AUX_HSION_PCIE0_CFG_PME_INT",
			"HSIO_N_GIA_MULTICAST_AGGR_8_AUX_HSION_PCIE0_USP_EQ_REDO_EXECUTED_INT",
			"HSIO_N_GIA_MULTICAST_AGGR_8_AUX_HSION_PCIE0_RADM_MSG_LTR_INT",
			"HSIO_N_GIA_MULTICAST_AGGR_8_AUX_HSION_BK_XHSION_GPIO0_IRQ",
			"HSIO_N_GIA_MULTICAST_AGGR_8_AUX_HSION_BK_XHSION_GPIO1_IRQ",
			"HSIO_N_GIA_MULTICAST_AGGR_8_AUX_HSION_BK_XHSION_GPIO2_IRQ",
			"HSIO_N_GIA_MULTICAST_AGGR_8_AUX_HSION_BK_XHSION_GPIO3_IRQ",
			"HSIO_N_GIA_MULTICAST_AGGR_8_AUX_HSION_BK_XHSION_GPIO4_IRQ",
			"HSIO_N_GIA_MULTICAST_AGGR_8_AUX_HSION_BK_XHSION_GPIO5_IRQ",
			"HSIO_N_GIA_MULTICAST_AGGR_8_AUX_HSION_BK_XHSION_GPIO6_IRQ",
			"HSIO_N_GIA_MULTICAST_AGGR_8_AUX_HSION_BK_XHSION_GPIO7_IRQ",
			"HSIO_N_GIA_MULTICAST_AGGR_8_AUX_HSION_BK_XHSION_GPIO8_IRQ",
			"HSIO_N_GIA_MULTICAST_AGGR_8_AUX_HSION_BK_XHSION_PCIE0_CLKREQN0_IRQ",
			"HSIO_N_GIA_MULTICAST_AGGR_8_AUX_HSION_BK_XHSION_PCIE0_PERSTN0_IRQ",
			"HSIO_N_GIA_MULTICAST_AGGR_8_AUX_HSION_EBU_TOP_INTR",
			"HSIO_N_GIA_MULTICAST_AGGR_8_AUX_HSION_DP_INTERRUPT_O",
			"HSIO_N_GIA_MULTICAST_AGGR_8_AUX_HSION_PCIE0_MSI_CTRL_INT_VEC",
			"TEST_LINE_31";
	};

	hsion_multicast_aggr_9_intr_test: hsion_multicast_aggr_9_intr_test {
		compatible = "google,gia-test";
		interrupt-parent = <&hsion_multicast_aggr_9_intr>;
		interrupts =
			<HSIO_N_GIA_MULTICAST_AGGR_9_AUX_HSION_DP_TRNG_O_IRQ>,
			<HSIO_N_GIA_MULTICAST_AGGR_9_AUX_HSION_USBDRD_PME_GEN_U3P_INTR>,
			<HSIO_N_GIA_MULTICAST_AGGR_9_AUX_HSION_U2PHY_LINESTATE_CHANGE_P_INTR>,
			<HSIO_N_GIA_MULTICAST_AGGR_9_AUX_HSION_U2PHY_LINESTATE_CHANGE_M_INTR>,
			<HSIO_N_GIA_MULTICAST_AGGR_9_AUX_HSION_USBDRD_SOF_NUM_CHANGE_INTR>,
			<HSIO_N_GIA_MULTICAST_AGGR_9_AUX_HSION_USBDRD_PS_CHANGE_INTR>,
			<HSIO_N_GIA_MULTICAST_AGGR_9_AUX_HSION_USBDP_TCA_INT>,
			<HSIO_N_GIA_MULTICAST_AGGR_9_AUX_HSION_DP_TRNG_O_EDU_VTRNG_IRQ_2>,
			<HSIO_N_GIA_MULTICAST_AGGR_9_AUX_HSION_DP_TRNG_O_EDU_VTRNG_IRQ_3>,
			<HSIO_N_GIA_MULTICAST_AGGR_9_AUX_HSION_DP_TRNG_O_EDU_VTRNG_IRQ_4>,
			<HSIO_N_GIA_MULTICAST_AGGR_9_AUX_HSION_DP_TRNG_O_EDU_VTRNG_IRQ_5>,
			<HSIO_N_GIA_MULTICAST_AGGR_9_AUX_HSION_DP_TRNG_O_EDU_IRQ>,
			<HSIO_N_GIA_MULTICAST_AGGR_9_AUX_HSION_DP_TRNG_O_EDU_VTRNG_IRQ_0>,
			<HSIO_N_GIA_MULTICAST_AGGR_9_AUX_HSION_DP_TRNG_O_EDU_VTRNG_IRQ_1>,
			<HSIO_N_GIA_MULTICAST_AGGR_9_AUX_HSION_DP_HDCP_O_HPI_IRQ>,
			<HSIO_N_GIA_MULTICAST_AGGR_9_AUX_HSION_USBDRD_INTERRUPT>,
			<HSIO_N_GIA_MULTICAST_AGGR_9_AUX_HSION_USBDRD_HOST_SYSTEM_ERR>,
			<HSIO_N_GIA_MULTICAST_AGGR_9_AUX_HSION_USBDRD_PME_GEN_INTR>,
			<HSIO_N_GIA_MULTICAST_AGGR_9_AUX_HSION_USBDRD_PME_GEN_U2P_INTR>,
			<31>;
		interrupt-names =
			"HSIO_N_GIA_MULTICAST_AGGR_9_AUX_HSION_DP_TRNG_O_IRQ",
			"HSIO_N_GIA_MULTICAST_AGGR_9_AUX_HSION_USBDRD_PME_GEN_U3P_INTR",
			"HSIO_N_GIA_MULTICAST_AGGR_9_AUX_HSION_U2PHY_LINESTATE_CHANGE_P_INTR",
			"HSIO_N_GIA_MULTICAST_AGGR_9_AUX_HSION_U2PHY_LINESTATE_CHANGE_M_INTR",
			"HSIO_N_GIA_MULTICAST_AGGR_9_AUX_HSION_USBDRD_SOF_NUM_CHANGE_INTR",
			"HSIO_N_GIA_MULTICAST_AGGR_9_AUX_HSION_USBDRD_PS_CHANGE_INTR",
			"HSIO_N_GIA_MULTICAST_AGGR_9_AUX_HSION_USBDP_TCA_INT",
			"HSIO_N_GIA_MULTICAST_AGGR_9_AUX_HSION_DP_TRNG_O_EDU_VTRNG_IRQ_2",
			"HSIO_N_GIA_MULTICAST_AGGR_9_AUX_HSION_DP_TRNG_O_EDU_VTRNG_IRQ_3",
			"HSIO_N_GIA_MULTICAST_AGGR_9_AUX_HSION_DP_TRNG_O_EDU_VTRNG_IRQ_4",
			"HSIO_N_GIA_MULTICAST_AGGR_9_AUX_HSION_DP_TRNG_O_EDU_VTRNG_IRQ_5",
			"HSIO_N_GIA_MULTICAST_AGGR_9_AUX_HSION_DP_TRNG_O_EDU_IRQ",
			"HSIO_N_GIA_MULTICAST_AGGR_9_AUX_HSION_DP_TRNG_O_EDU_VTRNG_IRQ_0",
			"HSIO_N_GIA_MULTICAST_AGGR_9_AUX_HSION_DP_TRNG_O_EDU_VTRNG_IRQ_1",
			"HSIO_N_GIA_MULTICAST_AGGR_9_AUX_HSION_DP_HDCP_O_HPI_IRQ",
			"HSIO_N_GIA_MULTICAST_AGGR_9_AUX_HSION_USBDRD_INTERRUPT",
			"HSIO_N_GIA_MULTICAST_AGGR_9_AUX_HSION_USBDRD_HOST_SYSTEM_ERR",
			"HSIO_N_GIA_MULTICAST_AGGR_9_AUX_HSION_USBDRD_PME_GEN_INTR",
			"HSIO_N_GIA_MULTICAST_AGGR_9_AUX_HSION_USBDRD_PME_GEN_U2P_INTR",
			"TEST_LINE_31";
	};

	hsios_multicast_aggr_5_intr_test: hsios_multicast_aggr_5_intr_test {
		compatible = "google,gia-test";
		power-domains = <&sswrp_hsio_s_pd>;
		interrupt-parent = <&hsios_multicast_aggr_5_intr>;
		interrupts =
			<HSIO_S_GIA_MULTICAST_AGGR_5_AUX_AON_XFW_PWRAP_RFW_G0R128_LPCM_NS_INTR>,
			<HSIO_S_GIA_MULTICAST_AGGR_5_AUX_XFW_AWRAP_RFW_G0R1024_PCIE0_NS_INTR>,
			<HSIO_S_GIA_MULTICAST_AGGR_5_AUX_XFW_AWRAP_RFW_G0R256_NS_INTR>,
			<HSIO_S_GIA_MULTICAST_AGGR_5_AUX_XFW_AWRAP_RFW_G0R256_GEM_NS_INTR>,
			<HSIO_S_GIA_MULTICAST_AGGR_5_AUX_XFW_AWRAP_RFW_G0R256_UFS_NS_INTR>,
			<HSIO_S_GIA_MULTICAST_AGGR_5_AUX_XFW_AWRAP_RFW_G0R256_PCIECSR_NS_INTR>,
			<HSIO_S_GIA_MULTICAST_AGGR_5_AUX_XFW_AWRAP_RFW_G0R32_SD_NS_INTR>,
			<HSIO_S_GIA_MULTICAST_AGGR_5_AUX_MASTER_WRAPPER_SD_MFW_NS_INTR>,
			<HSIO_S_GIA_MULTICAST_AGGR_5_AUX_MASTER_WRAPPER_PCIE_MFW_NS_INTR>,
			<HSIO_S_GIA_MULTICAST_AGGR_5_AUX_MASTER_WRAPPER_UFS_MFW_NS_INTR>,
			<HSIO_S_GIA_MULTICAST_AGGR_5_AUX_XFW_AWRAP_MFW_T_G0R32M35_PCIE_NS_INTR>,
			<HSIO_S_GIA_MULTICAST_AGGR_5_AUX_XFW_AWRAP_MFW_T_G0R32M35_UFS_NS_INTR>,
			<HSIO_S_GIA_MULTICAST_AGGR_5_AUX_MASTER_WRAPPER_SD_RA_NS_INTR>,
			<HSIO_S_GIA_MULTICAST_AGGR_5_AUX_MASTER_WRAPPER_PCIE_RA_NS_INTR>,
			<HSIO_S_GIA_MULTICAST_AGGR_5_AUX_MASTER_WRAPPER_UFS_RA_NS_INTR>,
			<HSIO_S_GIA_MULTICAST_AGGR_5_AUX_MASTER_WRAPPER_SD_GEM_IRQ>,
			<HSIO_S_GIA_MULTICAST_AGGR_5_AUX_MASTER_WRAPPER_PCIE_GEM_IRQ>,
			<HSIO_S_GIA_MULTICAST_AGGR_5_AUX_MASTER_WRAPPER_UFS_GEM_IRQ>,
			<HSIO_S_GIA_MULTICAST_AGGR_5_AUX_GEM3_TOP_IRQ>,
			<HSIO_S_GIA_MULTICAST_AGGR_5_AUX_CPSYSSHSIOS_IFABRIC_SYSS_XBA0_ERR_IRQ>,
			<HSIO_S_GIA_MULTICAST_AGGR_5_AUX_DTA_TOP_ELA600_ELAOUTPUT_0>,
			<HSIO_S_GIA_MULTICAST_AGGR_5_AUX_DTA_TOP_ELA600_ELAOUTPUT_1>,
			<HSIO_S_GIA_MULTICAST_AGGR_5_AUX_DTA_TOP_ELA600_ELAOUTPUT_2>,
			<HSIO_S_GIA_MULTICAST_AGGR_5_AUX_DTA_TOP_ELA600_ELAOUTPUT_3>,
			<31>;
		interrupt-names =
			"HSIO_S_GIA_MULTICAST_AGGR_5_AUX_AON_XFW_PWRAP_RFW_G0R128_LPCM_NS_INTR",
			"HSIO_S_GIA_MULTICAST_AGGR_5_AUX_XFW_AWRAP_RFW_G0R1024_PCIE0_NS_INTR",
			"HSIO_S_GIA_MULTICAST_AGGR_5_AUX_XFW_AWRAP_RFW_G0R256_NS_INTR",
			"HSIO_S_GIA_MULTICAST_AGGR_5_AUX_XFW_AWRAP_RFW_G0R256_GEM_NS_INTR",
			"HSIO_S_GIA_MULTICAST_AGGR_5_AUX_XFW_AWRAP_RFW_G0R256_UFS_NS_INTR",
			"HSIO_S_GIA_MULTICAST_AGGR_5_AUX_XFW_AWRAP_RFW_G0R256_PCIECSR_NS_INTR",
			"HSIO_S_GIA_MULTICAST_AGGR_5_AUX_XFW_AWRAP_RFW_G0R32_SD_NS_INTR",
			"HSIO_S_GIA_MULTICAST_AGGR_5_AUX_MASTER_WRAPPER_SD_MFW_NS_INTR",
			"HSIO_S_GIA_MULTICAST_AGGR_5_AUX_MASTER_WRAPPER_PCIE_MFW_NS_INTR",
			"HSIO_S_GIA_MULTICAST_AGGR_5_AUX_MASTER_WRAPPER_UFS_MFW_NS_INTR",
			"HSIO_S_GIA_MULTICAST_AGGR_5_AUX_XFW_AWRAP_MFW_T_G0R32M35_PCIE_NS_INTR",
			"HSIO_S_GIA_MULTICAST_AGGR_5_AUX_XFW_AWRAP_MFW_T_G0R32M35_UFS_NS_INTR",
			"HSIO_S_GIA_MULTICAST_AGGR_5_AUX_MASTER_WRAPPER_SD_RA_NS_INTR",
			"HSIO_S_GIA_MULTICAST_AGGR_5_AUX_MASTER_WRAPPER_PCIE_RA_NS_INTR",
			"HSIO_S_GIA_MULTICAST_AGGR_5_AUX_MASTER_WRAPPER_UFS_RA_NS_INTR",
			"HSIO_S_GIA_MULTICAST_AGGR_5_AUX_MASTER_WRAPPER_SD_GEM_IRQ",
			"HSIO_S_GIA_MULTICAST_AGGR_5_AUX_MASTER_WRAPPER_PCIE_GEM_IRQ",
			"HSIO_S_GIA_MULTICAST_AGGR_5_AUX_MASTER_WRAPPER_UFS_GEM_IRQ",
			"HSIO_S_GIA_MULTICAST_AGGR_5_AUX_GEM3_TOP_IRQ",
			"HSIO_S_GIA_MULTICAST_AGGR_5_AUX_CPSYSSHSIOS_IFABRIC_SYSS_XBA0_ERR_IRQ",
			"HSIO_S_GIA_MULTICAST_AGGR_5_AUX_DTA_TOP_ELA600_ELAOUTPUT_0",
			"HSIO_S_GIA_MULTICAST_AGGR_5_AUX_DTA_TOP_ELA600_ELAOUTPUT_1",
			"HSIO_S_GIA_MULTICAST_AGGR_5_AUX_DTA_TOP_ELA600_ELAOUTPUT_2",
			"HSIO_S_GIA_MULTICAST_AGGR_5_AUX_DTA_TOP_ELA600_ELAOUTPUT_3",
			"TEST_LINE_31";
	};

	hsios_multicast_aggr_6_intr_test: hsios_multicast_aggr_6_intr_test {
		compatible = "google,gia-test";
		power-domains = <&sswrp_hsio_s_pd>;
		interrupt-parent = <&hsios_multicast_aggr_6_intr>;
		interrupts =
			<HSIO_S_GIA_MULTICAST_AGGR_6_AUX_GPIO_HSIOS_BK_XHSIOS_GPIO0_IRQ>,
			<HSIO_S_GIA_MULTICAST_AGGR_6_AUX_GPIO_HSIOS_BK_XHSIOS_GPIO1_IRQ>,
			<HSIO_S_GIA_MULTICAST_AGGR_6_AUX_GPIO_HSIOS_BK_XHSIOS_GPIO2_IRQ>,
			<HSIO_S_GIA_MULTICAST_AGGR_6_AUX_GPIO_HSIOS_BK_XHSIOS_GPIO3_IRQ>,
			<HSIO_S_GIA_MULTICAST_AGGR_6_AUX_GPIO_HSIOS_BK_XHSIOS_GPIO4_IRQ>,
			<HSIO_S_GIA_MULTICAST_AGGR_6_AUX_GPIO_HSIOS_BK_XHSIOS_GPIO5_IRQ>,
			<HSIO_S_GIA_MULTICAST_AGGR_6_AUX_GPIO_HSIOS_BK_XHSIOS_GPIO6_IRQ>,
			<HSIO_S_GIA_MULTICAST_AGGR_6_AUX_GPIO_HSIOS_BK_XHSIOS_GPIO7_IRQ>,
			<HSIO_S_GIA_MULTICAST_AGGR_6_AUX_GPIO_HSIOS_BK_XHSIOS_GPIO8_IRQ>,
			<HSIO_S_GIA_MULTICAST_AGGR_6_AUX_GPIO_HSIOS_BK_XHSIOS_UFS_RESETB_IRQ>,
			<HSIO_S_GIA_MULTICAST_AGGR_6_AUX_GPIO_HSIOS_BK_XHSIOS_UFS_PWR_EN_IRQ>,
			<HSIO_S_GIA_MULTICAST_AGGR_6_AUX_GPIO_HSIOS_BK_XHSIOS_PCIE1_CLKREQN0_IRQ>,
			<HSIO_S_GIA_MULTICAST_AGGR_6_AUX_GPIO_HSIOS_BK_XHSIOS_PCIE1_PERSTN0_IRQ>,
			<HSIO_S_GIA_MULTICAST_AGGR_6_AUX_GPIO_HSIOS_BK_XHSIOS_VSYNC4_IRQ>,
			<HSIO_S_GIA_MULTICAST_AGGR_6_UFS_SD_TOP_UFS_TOP_UFS_SS_SINTERRUPT>,
			<HSIO_S_GIA_MULTICAST_AGGR_6_UFS_SD_TOP_UFSWR_SELFTEST_FAIL_INTR>,
			<HSIO_S_GIA_MULTICAST_AGGR_6_UFS_SD_TOP_UFSWR_SELFTEST_PASS_INTR>,
			<HSIO_S_GIA_MULTICAST_AGGR_6_UFS_SD_TOP_SD_TOP_INTR>,
			<HSIO_S_GIA_MULTICAST_AGGR_6_UFS_SD_TOP_SD_TOP_WAKEUP_INTR>,
			<HSIO_S_GIA_MULTICAST_AGGR_6_PCIE_TOP_PCIE0_MSI_CTRL_INT>,
			<HSIO_S_GIA_MULTICAST_AGGR_6_PCIE_TOP_PCIE_MSI_CTRL_INT_VEC_0>,
			<HSIO_S_GIA_MULTICAST_AGGR_6_PCIE_TOP_PCIE_MSI_CTRL_INT_VEC_1>,
			<HSIO_S_GIA_MULTICAST_AGGR_6_PCIE_TOP_PCIE_MSI_CTRL_INT_VEC_2>,
			<HSIO_S_GIA_MULTICAST_AGGR_6_PCIE_TOP_PCIE_MSI_CTRL_INT_VEC_3>,
			<HSIO_S_GIA_MULTICAST_AGGR_6_PCIE_TOP_PCIE_MSI_CTRL_INT_VEC_4>,
			<HSIO_S_GIA_MULTICAST_AGGR_6_PCIE_TOP_PCIE_MSI_CTRL_INT_VEC_5>,
			<HSIO_S_GIA_MULTICAST_AGGR_6_PCIE_TOP_PCIE_MSI_CTRL_INT_VEC_6>,
			<HSIO_S_GIA_MULTICAST_AGGR_6_PCIE_TOP_PCIE_MSI_CTRL_INT_VEC_7>,
			<HSIO_S_GIA_MULTICAST_AGGR_6_PCIE_TOP_PCIE0_HP_INT>,
			<31>;
		interrupt-names =
			"HSIO_S_GIA_MULTICAST_AGGR_6_AUX_GPIO_HSIOS_BK_XHSIOS_GPIO0_IRQ",
			"HSIO_S_GIA_MULTICAST_AGGR_6_AUX_GPIO_HSIOS_BK_XHSIOS_GPIO1_IRQ",
			"HSIO_S_GIA_MULTICAST_AGGR_6_AUX_GPIO_HSIOS_BK_XHSIOS_GPIO2_IRQ",
			"HSIO_S_GIA_MULTICAST_AGGR_6_AUX_GPIO_HSIOS_BK_XHSIOS_GPIO3_IRQ",
			"HSIO_S_GIA_MULTICAST_AGGR_6_AUX_GPIO_HSIOS_BK_XHSIOS_GPIO4_IRQ",
			"HSIO_S_GIA_MULTICAST_AGGR_6_AUX_GPIO_HSIOS_BK_XHSIOS_GPIO5_IRQ",
			"HSIO_S_GIA_MULTICAST_AGGR_6_AUX_GPIO_HSIOS_BK_XHSIOS_GPIO6_IRQ",
			"HSIO_S_GIA_MULTICAST_AGGR_6_AUX_GPIO_HSIOS_BK_XHSIOS_GPIO7_IRQ",
			"HSIO_S_GIA_MULTICAST_AGGR_6_AUX_GPIO_HSIOS_BK_XHSIOS_GPIO8_IRQ",
			"HSIO_S_GIA_MULTICAST_AGGR_6_AUX_GPIO_HSIOS_BK_XHSIOS_UFS_RESETB_IRQ",
			"HSIO_S_GIA_MULTICAST_AGGR_6_AUX_GPIO_HSIOS_BK_XHSIOS_UFS_PWR_EN_IRQ",
			"HSIO_S_GIA_MULTICAST_AGGR_6_AUX_GPIO_HSIOS_BK_XHSIOS_PCIE1_CLKREQN0_IRQ",
			"HSIO_S_GIA_MULTICAST_AGGR_6_AUX_GPIO_HSIOS_BK_XHSIOS_PCIE1_PERSTN0_IRQ",
			"HSIO_S_GIA_MULTICAST_AGGR_6_AUX_GPIO_HSIOS_BK_XHSIOS_VSYNC4_IRQ",
			"HSIO_S_GIA_MULTICAST_AGGR_6_UFS_SD_TOP_UFS_TOP_UFS_SS_SINTERRUPT",
			"HSIO_S_GIA_MULTICAST_AGGR_6_UFS_SD_TOP_UFSWR_SELFTEST_FAIL_INTR",
			"HSIO_S_GIA_MULTICAST_AGGR_6_UFS_SD_TOP_UFSWR_SELFTEST_PASS_INTR",
			"HSIO_S_GIA_MULTICAST_AGGR_6_UFS_SD_TOP_SD_TOP_INTR",
			"HSIO_S_GIA_MULTICAST_AGGR_6_UFS_SD_TOP_SD_TOP_WAKEUP_INTR",
			"HSIO_S_GIA_MULTICAST_AGGR_6_PCIE_TOP_PCIE0_MSI_CTRL_INT",
			"HSIO_S_GIA_MULTICAST_AGGR_6_PCIE_TOP_PCIE_MSI_CTRL_INT_VEC_0",
			"HSIO_S_GIA_MULTICAST_AGGR_6_PCIE_TOP_PCIE_MSI_CTRL_INT_VEC_1",
			"HSIO_S_GIA_MULTICAST_AGGR_6_PCIE_TOP_PCIE_MSI_CTRL_INT_VEC_2",
			"HSIO_S_GIA_MULTICAST_AGGR_6_PCIE_TOP_PCIE_MSI_CTRL_INT_VEC_3",
			"HSIO_S_GIA_MULTICAST_AGGR_6_PCIE_TOP_PCIE_MSI_CTRL_INT_VEC_4",
			"HSIO_S_GIA_MULTICAST_AGGR_6_PCIE_TOP_PCIE_MSI_CTRL_INT_VEC_5",
			"HSIO_S_GIA_MULTICAST_AGGR_6_PCIE_TOP_PCIE_MSI_CTRL_INT_VEC_6",
			"HSIO_S_GIA_MULTICAST_AGGR_6_PCIE_TOP_PCIE_MSI_CTRL_INT_VEC_7",
			"HSIO_S_GIA_MULTICAST_AGGR_6_PCIE_TOP_PCIE0_HP_INT",
			"TEST_LINE_31";
	};

	hsios_multicast_aggr_7_intr_test: hsios_multicast_aggr_7_intr_test {
		compatible = "google,gia-test";
		power-domains = <&sswrp_hsio_s_pd>;
		interrupt-parent = <&hsios_multicast_aggr_7_intr>;
		interrupts =
			<HSIO_S_GIA_MULTICAST_AGGR_7_PCIE_TOP_PCIE0_EDMA_INT_0>,
			<HSIO_S_GIA_MULTICAST_AGGR_7_PCIE_TOP_PCIE0_EDMA_INT_1>,
			<HSIO_S_GIA_MULTICAST_AGGR_7_PCIE_TOP_PCIE0_EDMA_INT_2>,
			<HSIO_S_GIA_MULTICAST_AGGR_7_PCIE_TOP_PCIE0_EDMA_INT_3>,
			<HSIO_S_GIA_MULTICAST_AGGR_7_PCIE_TOP_PCIE0_CFG_AER_RC_ERR_INT>,
			<HSIO_S_GIA_MULTICAST_AGGR_7_PCIE_TOP_PCIE0_CFG_BW_MGT_INT>,
			<HSIO_S_GIA_MULTICAST_AGGR_7_PCIE_TOP_PCIE0_CFG_LINK_AUTO_BW_INT>,
			<HSIO_S_GIA_MULTICAST_AGGR_7_PCIE_TOP_PCIE0_CFG_LINK_EQ_REQ_INT>,
			<HSIO_S_GIA_MULTICAST_AGGR_7_PCIE_TOP_PCIE0_CFG_PME_INT>,
			<HSIO_S_GIA_MULTICAST_AGGR_7_PCIE_TOP_PCIE0_USP_EQ_REDO_EXECUTED_INT>,
			<HSIO_S_GIA_MULTICAST_AGGR_7_PCIE_TOP_PCIE0_RADM_MSG_LTR_INT>,
			<31>;
		interrupt-names =
			"HSIO_S_GIA_MULTICAST_AGGR_7_PCIE_TOP_PCIE0_EDMA_INT_0",
			"HSIO_S_GIA_MULTICAST_AGGR_7_PCIE_TOP_PCIE0_EDMA_INT_1",
			"HSIO_S_GIA_MULTICAST_AGGR_7_PCIE_TOP_PCIE0_EDMA_INT_2",
			"HSIO_S_GIA_MULTICAST_AGGR_7_PCIE_TOP_PCIE0_EDMA_INT_3",
			"HSIO_S_GIA_MULTICAST_AGGR_7_PCIE_TOP_PCIE0_CFG_AER_RC_ERR_INT",
			"HSIO_S_GIA_MULTICAST_AGGR_7_PCIE_TOP_PCIE0_CFG_BW_MGT_INT",
			"HSIO_S_GIA_MULTICAST_AGGR_7_PCIE_TOP_PCIE0_CFG_LINK_AUTO_BW_INT",
			"HSIO_S_GIA_MULTICAST_AGGR_7_PCIE_TOP_PCIE0_CFG_LINK_EQ_REQ_INT",
			"HSIO_S_GIA_MULTICAST_AGGR_7_PCIE_TOP_PCIE0_CFG_PME_INT",
			"HSIO_S_GIA_MULTICAST_AGGR_7_PCIE_TOP_PCIE0_USP_EQ_REDO_EXECUTED_INT",
			"HSIO_S_GIA_MULTICAST_AGGR_7_PCIE_TOP_PCIE0_RADM_MSG_LTR_INT",
			"TEST_LINE_31";
	};

	hsios_pulse_aggr_3_intr_test: hsios_pulse_aggr_3_intr_test {
		compatible = "google,gia-test";
		power-domains = <&sswrp_hsio_s_pd>;
		interrupt-parent = <&hsios_pulse_aggr_3_intr>;
		interrupts =
			<HSIO_S_GIA_PULSE_AGGR_3_AUX_SD_GSPAN_ACELITE_INI_ICD_ERR_DSCGT>,
			<HSIO_S_GIA_PULSE_AGGR_3_AUX_PCI_GSPAN_ACELITE_INI_1_ICD_ERR_DSCGT>,
			<HSIO_S_GIA_PULSE_AGGR_3_AUX_UFS_GSPAN_ACELITE_INI_ICD_ERR_DSCGT>,
			<HSIO_S_GIA_PULSE_AGGR_3_AUX_GSPAN_ATB_INITIATOR_ICD_ERR_DSCGT>,
			<HSIO_S_GIA_PULSE_AGGR_3_AUX_MASTER_WRAPPER_SD_TBU_TBU_RAS_FHI>,
			<HSIO_S_GIA_PULSE_AGGR_3_AUX_MASTER_WRAPPER_SD_TBU_TBU_RAS_ERI>,
			<HSIO_S_GIA_PULSE_AGGR_3_AUX_MASTER_WRAPPER_SD_TBU_TBU_RAS_CRI>,
			<HSIO_S_GIA_PULSE_AGGR_3_AUX_MASTER_WRAPPER_SD_TBU_TBU_PMU_IRPT>,
			<HSIO_S_GIA_PULSE_AGGR_3_AUX_MASTER_WRAPPER_PCIE_TBU_TBU_RAS_FHI>,
			<HSIO_S_GIA_PULSE_AGGR_3_AUX_MASTER_WRAPPER_PCIE_TBU_TBU_RAS_ERI>,
			<HSIO_S_GIA_PULSE_AGGR_3_AUX_MASTER_WRAPPER_PCIE_TBU_TBU_RAS_CRI>,
			<HSIO_S_GIA_PULSE_AGGR_3_AUX_MASTER_WRAPPER_PCIE_TBU_TBU_PMU_IRPT>,
			<HSIO_S_GIA_PULSE_AGGR_3_AUX_MASTER_WRAPPER_UFS_TBU_TBU_RAS_FHI>,
			<HSIO_S_GIA_PULSE_AGGR_3_AUX_MASTER_WRAPPER_UFS_TBU_TBU_RAS_ERI>,
			<HSIO_S_GIA_PULSE_AGGR_3_AUX_MASTER_WRAPPER_UFS_TBU_TBU_RAS_CRI>,
			<HSIO_S_GIA_PULSE_AGGR_3_AUX_MASTER_WRAPPER_UFS_TBU_TBU_PMU_IRPT>,
			<HSIO_S_GIA_PULSE_AGGR_3_PCIE_TOP_TRGT_CPL_TIMEOUT_INT>,
			<HSIO_S_GIA_PULSE_AGGR_3_PCIE_TOP_PCIE_SPARE_OUT_4>,
			<HSIO_S_GIA_PULSE_AGGR_3_AUX_HSIOS_UFS_FBE_TOP_ACCESS_CONTROL_ERR>,
			<HSIO_S_GIA_PULSE_AGGR_3_AUX_HSIOS_UFS_FBE_TOP_KEY_SLOT_ID_ERR>,
			<HSIO_S_GIA_PULSE_AGGR_3_AUX_HSIOS_UFS_FBE_TOP_KEY_POLICY_ERR>,
			<HSIO_S_GIA_PULSE_AGGR_3_AUX_HSIOS_UFS_FBE_TOP_KDN_SW_MODE_ERR>,
			<HSIO_S_GIA_PULSE_AGGR_3_AUX_HSIOS_UFS_FBE_TOP_CRC_CHECK_ERR>,
			<HSIO_S_GIA_PULSE_AGGR_3_PCIE_TOP_PCIE0_RADM_INTA_ASSERTED_INT>,
			<HSIO_S_GIA_PULSE_AGGR_3_PCIE_TOP_PCIE0_RADM_INTA_DEASSERTED_INT>,
			<HSIO_S_GIA_PULSE_AGGR_3_PCIE_TOP_PCIE0_RADM_INTB_ASSERTED_INT>,
			<31>;
		interrupt-names =
			"HSIO_S_GIA_PULSE_AGGR_3_AUX_SD_GSPAN_ACELITE_INI_ICD_ERR_DSCGT",
			"HSIO_S_GIA_PULSE_AGGR_3_AUX_PCI_GSPAN_ACELITE_INI_1_ICD_ERR_DSCGT",
			"HSIO_S_GIA_PULSE_AGGR_3_AUX_UFS_GSPAN_ACELITE_INI_ICD_ERR_DSCGT",
			"HSIO_S_GIA_PULSE_AGGR_3_AUX_GSPAN_ATB_INITIATOR_ICD_ERR_DSCGT",
			"HSIO_S_GIA_PULSE_AGGR_3_AUX_MASTER_WRAPPER_SD_TBU_TBU_RAS_FHI",
			"HSIO_S_GIA_PULSE_AGGR_3_AUX_MASTER_WRAPPER_SD_TBU_TBU_RAS_ERI",
			"HSIO_S_GIA_PULSE_AGGR_3_AUX_MASTER_WRAPPER_SD_TBU_TBU_RAS_CRI",
			"HSIO_S_GIA_PULSE_AGGR_3_AUX_MASTER_WRAPPER_SD_TBU_TBU_PMU_IRPT",
			"HSIO_S_GIA_PULSE_AGGR_3_AUX_MASTER_WRAPPER_PCIE_TBU_TBU_RAS_FHI",
			"HSIO_S_GIA_PULSE_AGGR_3_AUX_MASTER_WRAPPER_PCIE_TBU_TBU_RAS_ERI",
			"HSIO_S_GIA_PULSE_AGGR_3_AUX_MASTER_WRAPPER_PCIE_TBU_TBU_RAS_CRI",
			"HSIO_S_GIA_PULSE_AGGR_3_AUX_MASTER_WRAPPER_PCIE_TBU_TBU_PMU_IRPT",
			"HSIO_S_GIA_PULSE_AGGR_3_AUX_MASTER_WRAPPER_UFS_TBU_TBU_RAS_FHI",
			"HSIO_S_GIA_PULSE_AGGR_3_AUX_MASTER_WRAPPER_UFS_TBU_TBU_RAS_ERI",
			"HSIO_S_GIA_PULSE_AGGR_3_AUX_MASTER_WRAPPER_UFS_TBU_TBU_RAS_CRI",
			"HSIO_S_GIA_PULSE_AGGR_3_AUX_MASTER_WRAPPER_UFS_TBU_TBU_PMU_IRPT",
			"HSIO_S_GIA_PULSE_AGGR_3_PCIE_TOP_TRGT_CPL_TIMEOUT_INT",
			"HSIO_S_GIA_PULSE_AGGR_3_PCIE_TOP_PCIE_SPARE_OUT_4",
			"HSIO_S_GIA_PULSE_AGGR_3_AUX_HSIOS_UFS_FBE_TOP_ACCESS_CONTROL_ERR",
			"HSIO_S_GIA_PULSE_AGGR_3_AUX_HSIOS_UFS_FBE_TOP_KEY_SLOT_ID_ERR",
			"HSIO_S_GIA_PULSE_AGGR_3_AUX_HSIOS_UFS_FBE_TOP_KEY_POLICY_ERR",
			"HSIO_S_GIA_PULSE_AGGR_3_AUX_HSIOS_UFS_FBE_TOP_KDN_SW_MODE_ERR",
			"HSIO_S_GIA_PULSE_AGGR_3_AUX_HSIOS_UFS_FBE_TOP_CRC_CHECK_ERR",
			"HSIO_S_GIA_PULSE_AGGR_3_PCIE_TOP_PCIE0_RADM_INTA_ASSERTED_INT",
			"HSIO_S_GIA_PULSE_AGGR_3_PCIE_TOP_PCIE0_RADM_INTA_DEASSERTED_INT",
			"HSIO_S_GIA_PULSE_AGGR_3_PCIE_TOP_PCIE0_RADM_INTB_ASSERTED_INT",
			"TEST_LINE_31";
	};

	hsios_pulse_aggr_4_intr_test: hsios_pulse_aggr_4_intr_test {
		compatible = "google,gia-test";
		power-domains = <&sswrp_hsio_s_pd>;
		interrupt-parent = <&hsios_pulse_aggr_4_intr>;
		interrupts =
			<HSIO_S_GIA_PULSE_AGGR_4_PCIE_TOP_PCIE0_RADM_INTB_DEASSERTED_INT>,
			<HSIO_S_GIA_PULSE_AGGR_4_PCIE_TOP_PCIE0_RADM_INTC_ASSERTED_INT>,
			<HSIO_S_GIA_PULSE_AGGR_4_PCIE_TOP_PCIE0_RADM_INTC_DEASSERTED_INT>,
			<HSIO_S_GIA_PULSE_AGGR_4_PCIE_TOP_PCIE0_RADM_INTD_ASSERTED_INT>,
			<HSIO_S_GIA_PULSE_AGGR_4_PCIE_TOP_PCIE0_RADM_INTD_DEASSERTED_INT>,
			<HSIO_S_GIA_PULSE_AGGR_4_PCIE_TOP_PCIE0_RADM_VENDOR_MSG_INT>,
			<HSIO_S_GIA_PULSE_AGGR_4_PCIE_TOP_PCIE0_HP_MSI_INT>,
			<HSIO_S_GIA_PULSE_AGGR_4_PCIE_TOP_PCIE0_HP_PME_INT>,
			<HSIO_S_GIA_PULSE_AGGR_4_PCIE_TOP_PCIE0_CFG_AER_RC_ERR_MSI_INT>,
			<HSIO_S_GIA_PULSE_AGGR_4_PCIE_TOP_PCIE0_CFG_BW_MGT_MSI_INT>,
			<HSIO_S_GIA_PULSE_AGGR_4_PCIE_TOP_PCIE0_CFG_LINK_AUTO_BW_MSI_INT>,
			<HSIO_S_GIA_PULSE_AGGR_4_PCIE_TOP_PCIE0_CFG_PME_MSI_INT>,
			<HSIO_S_GIA_PULSE_AGGR_4_PCIE_TOP_PCIE0_CFG_SYS_ERR_RC_INT>,
			<HSIO_S_GIA_PULSE_AGGR_4_PCIE_TOP_PCIE0_RADM_CORRECTABLE_ERR_INT>,
			<HSIO_S_GIA_PULSE_AGGR_4_PCIE_TOP_PCIE0_RADM_CPL_TIMEOUT_INT>,
			<HSIO_S_GIA_PULSE_AGGR_4_PCIE_TOP_PCIE0_RADM_FATAL_ERR_INT>,
			<HSIO_S_GIA_PULSE_AGGR_4_PCIE_TOP_PCIE0_RADM_NONFATAL_ERR_INT>,
			<31>;
		interrupt-names =
			"HSIO_S_GIA_PULSE_AGGR_4_PCIE_TOP_PCIE0_RADM_INTB_DEASSERTED_INT",
			"HSIO_S_GIA_PULSE_AGGR_4_PCIE_TOP_PCIE0_RADM_INTC_ASSERTED_INT",
			"HSIO_S_GIA_PULSE_AGGR_4_PCIE_TOP_PCIE0_RADM_INTC_DEASSERTED_INT",
			"HSIO_S_GIA_PULSE_AGGR_4_PCIE_TOP_PCIE0_RADM_INTD_ASSERTED_INT",
			"HSIO_S_GIA_PULSE_AGGR_4_PCIE_TOP_PCIE0_RADM_INTD_DEASSERTED_INT",
			"HSIO_S_GIA_PULSE_AGGR_4_PCIE_TOP_PCIE0_RADM_VENDOR_MSG_INT",
			"HSIO_S_GIA_PULSE_AGGR_4_PCIE_TOP_PCIE0_HP_MSI_INT",
			"HSIO_S_GIA_PULSE_AGGR_4_PCIE_TOP_PCIE0_HP_PME_INT",
			"HSIO_S_GIA_PULSE_AGGR_4_PCIE_TOP_PCIE0_CFG_AER_RC_ERR_MSI_INT",
			"HSIO_S_GIA_PULSE_AGGR_4_PCIE_TOP_PCIE0_CFG_BW_MGT_MSI_INT",
			"HSIO_S_GIA_PULSE_AGGR_4_PCIE_TOP_PCIE0_CFG_LINK_AUTO_BW_MSI_INT",
			"HSIO_S_GIA_PULSE_AGGR_4_PCIE_TOP_PCIE0_CFG_PME_MSI_INT",
			"HSIO_S_GIA_PULSE_AGGR_4_PCIE_TOP_PCIE0_CFG_SYS_ERR_RC_INT",
			"HSIO_S_GIA_PULSE_AGGR_4_PCIE_TOP_PCIE0_RADM_CORRECTABLE_ERR_INT",
			"HSIO_S_GIA_PULSE_AGGR_4_PCIE_TOP_PCIE0_RADM_CPL_TIMEOUT_INT",
			"HSIO_S_GIA_PULSE_AGGR_4_PCIE_TOP_PCIE0_RADM_FATAL_ERR_INT",
			"HSIO_S_GIA_PULSE_AGGR_4_PCIE_TOP_PCIE0_RADM_NONFATAL_ERR_INT",
			"TEST_LINE_31";
	};

	inftcu_multicast_aggr_3_intr_test: inftcu_multicast_aggr_3_intr_test {
		compatible = "google,gia-test";
		interrupt-parent = <&inftcu_multicast_aggr_3_intr>;
		interrupts =
			<INF_TCU_GIA_MULTICAST_AGGR_3_AUX_AON_GIA_PULSE_AGGR_0_INTR>,
			<INF_TCU_GIA_MULTICAST_AGGR_3_AUX_AON_XFW_TOP_LPCM_RFW_G0R32_NS_INTR>,
			<INF_TCU_GIA_MULTICAST_AGGR_3_AUX_AON_RFW_AP_NS_INTR>,
			<INF_TCU_GIA_MULTICAST_AGGR_3_AUX_AON_XBA0_ERR_IRQ>,
			<INF_TCU_GIA_MULTICAST_AGGR_3_AUX_AON_ELAOUTPUT0>,
			<INF_TCU_GIA_MULTICAST_AGGR_3_AUX_AON_ELAOUTPUT1>,
			<INF_TCU_GIA_MULTICAST_AGGR_3_AUX_AON_ELAOUTPUT2>,
			<INF_TCU_GIA_MULTICAST_AGGR_3_AUX_AON_ELAOUTPUT3>,
			<INF_TCU_GIA_MULTICAST_AGGR_3_AUX_AON_GEM_IRQ>,
			<31>;
		interrupt-names =
			"INF_TCU_GIA_MULTICAST_AGGR_3_AUX_AON_GIA_PULSE_AGGR_0_INTR",
			"INF_TCU_GIA_MULTICAST_AGGR_3_AUX_AON_XFW_TOP_LPCM_RFW_G0R32_NS_INTR",
			"INF_TCU_GIA_MULTICAST_AGGR_3_AUX_AON_RFW_AP_NS_INTR",
			"INF_TCU_GIA_MULTICAST_AGGR_3_AUX_AON_XBA0_ERR_IRQ",
			"INF_TCU_GIA_MULTICAST_AGGR_3_AUX_AON_ELAOUTPUT0",
			"INF_TCU_GIA_MULTICAST_AGGR_3_AUX_AON_ELAOUTPUT1",
			"INF_TCU_GIA_MULTICAST_AGGR_3_AUX_AON_ELAOUTPUT2",
			"INF_TCU_GIA_MULTICAST_AGGR_3_AUX_AON_ELAOUTPUT3",
			"INF_TCU_GIA_MULTICAST_AGGR_3_AUX_AON_GEM_IRQ",
			"TEST_LINE_31";
	};

	inftcu_pulse_aggr_0_intr_test: inftcu_pulse_aggr_0_intr_test {
		compatible = "google,gia-test";
		interrupt-parent = <&inftcu_pulse_aggr_0_intr>;
		interrupts =
			<INF_TCU_GIA_PULSE_AGGR_0_AUX_AON_EVENT_Q_IRPT_NS_RIS_SYNC>,
			<INF_TCU_GIA_PULSE_AGGR_0_AUX_AON_CMD_SYNC_IRPT_NS_RIS_SYNC>,
			<INF_TCU_GIA_PULSE_AGGR_0_AUX_AON_GLOBAL_IRPT_NS_RIS_SYNC>,
			<INF_TCU_GIA_PULSE_AGGR_0_AUX_AON_RAS_FHI_RIS_SYNC>,
			<INF_TCU_GIA_PULSE_AGGR_0_AUX_AON_RAS_ERI_RIS_SYNC>,
			<INF_TCU_GIA_PULSE_AGGR_0_AUX_AON_RAS_CRI_RIS_SYNC>,
			<INF_TCU_GIA_PULSE_AGGR_0_AUX_AON_PMU_IRPT_RIS_SYNC>,
			<INF_TCU_GIA_PULSE_AGGR_0_AUX_AON_PRI_Q_IRPT_NS_RIS_SYNC>,
			<INF_TCU_GIA_PULSE_AGGR_0_AUX_AON_ACELITE_INIT_ICD_ERR_DSCGT_SYNC>,
			<INF_TCU_GIA_PULSE_AGGR_0_AUX_AON_ATB_INIT_ICD_ERR_DSCGT_SYNC>,
			<31>;
		interrupt-names =
			"INF_TCU_GIA_PULSE_AGGR_0_AUX_AON_EVENT_Q_IRPT_NS_RIS_SYNC",
			"INF_TCU_GIA_PULSE_AGGR_0_AUX_AON_CMD_SYNC_IRPT_NS_RIS_SYNC",
			"INF_TCU_GIA_PULSE_AGGR_0_AUX_AON_GLOBAL_IRPT_NS_RIS_SYNC",
			"INF_TCU_GIA_PULSE_AGGR_0_AUX_AON_RAS_FHI_RIS_SYNC",
			"INF_TCU_GIA_PULSE_AGGR_0_AUX_AON_RAS_ERI_RIS_SYNC",
			"INF_TCU_GIA_PULSE_AGGR_0_AUX_AON_RAS_CRI_RIS_SYNC",
			"INF_TCU_GIA_PULSE_AGGR_0_AUX_AON_PMU_IRPT_RIS_SYNC",
			"INF_TCU_GIA_PULSE_AGGR_0_AUX_AON_PRI_Q_IRPT_NS_RIS_SYNC",
			"INF_TCU_GIA_PULSE_AGGR_0_AUX_AON_ACELITE_INIT_ICD_ERR_DSCGT_SYNC",
			"INF_TCU_GIA_PULSE_AGGR_0_AUX_AON_ATB_INIT_ICD_ERR_DSCGT_SYNC",
			"TEST_LINE_31";
	};

	ispfe_level_aggr_3_intr_test: ispfe_level_aggr_3_intr_test {
		compatible = "google,gia-test";
		power-domains = <&ispfe_pipe_pd>;
		interrupt-parent = <&ispfe_level_aggr_3_intr>;
		interrupts =
			<ISPFE_GIA_LEVEL_AGGR_3_GIA_LEVEL_AGGR_10_INTR>,
			<ISPFE_GIA_LEVEL_AGGR_3_BFC_FC_AP_IRQ>,
			<ISPFE_GIA_LEVEL_AGGR_3_BFC_CORE_AP_IRQ>,
			<ISPFE_GIA_LEVEL_AGGR_3_LMP_IRQ_AP>,
			<ISPFE_GIA_LEVEL_AGGR_3_PDAF_IRQ_AP>,
			<ISPFE_GIA_LEVEL_AGGR_3_PDMA_0_AP_IRQ>,
			<ISPFE_GIA_LEVEL_AGGR_3_PDMA_1_AP_IRQ>,
			<ISPFE_GIA_LEVEL_AGGR_3_PDMA_2_AP_IRQ>,
			<ISPFE_GIA_LEVEL_AGGR_3_PDMA_3_AP_IRQ>,
			<ISPFE_GIA_LEVEL_AGGR_3_PDMA_4_AP_IRQ>;
		interrupt-names =
			"ISPFE_GIA_LEVEL_AGGR_3_GIA_LEVEL_AGGR_10_INTR",
			"ISPFE_GIA_LEVEL_AGGR_3_BFC_FC_AP_IRQ",
			"ISPFE_GIA_LEVEL_AGGR_3_BFC_CORE_AP_IRQ",
			"ISPFE_GIA_LEVEL_AGGR_3_LMP_IRQ_AP",
			"ISPFE_GIA_LEVEL_AGGR_3_PDAF_IRQ_AP",
			"ISPFE_GIA_LEVEL_AGGR_3_PDMA_0_AP_IRQ",
			"ISPFE_GIA_LEVEL_AGGR_3_PDMA_1_AP_IRQ",
			"ISPFE_GIA_LEVEL_AGGR_3_PDMA_2_AP_IRQ",
			"ISPFE_GIA_LEVEL_AGGR_3_PDMA_3_AP_IRQ",
			"ISPFE_GIA_LEVEL_AGGR_3_PDMA_4_AP_IRQ";
	};

	ispfe_level_aggr_10_intr_test: ispfe_level_aggr_10_intr_test {
		compatible = "google,gia-test";
		power-domains = <&ispfe_pipe_pd>;
		interrupt-parent = <&ispfe_level_aggr_10_intr>;
		interrupts =
			<ISPFE_GIA_LEVEL_AGGR_10_DLI0_IRQ>,
			<ISPFE_GIA_LEVEL_AGGR_10_DLI1_IRQ>,
			<ISPFE_GIA_LEVEL_AGGR_10_DLI2_IRQ>,
			<ISPFE_GIA_LEVEL_AGGR_10_DLI3_IRQ>,
			<ISPFE_GIA_LEVEL_AGGR_10_DLI4_IRQ>,
			<ISPFE_GIA_LEVEL_AGGR_10_DLI5_IRQ>,
			<ISPFE_GIA_LEVEL_AGGR_10_DLI6_IRQ>,
			<ISPFE_GIA_LEVEL_AGGR_10_DLI7_IRQ>;
		interrupt-names =
			"ISPFE_GIA_LEVEL_AGGR_10_DLI0_IRQ",
			"ISPFE_GIA_LEVEL_AGGR_10_DLI1_IRQ",
			"ISPFE_GIA_LEVEL_AGGR_10_DLI2_IRQ",
			"ISPFE_GIA_LEVEL_AGGR_10_DLI3_IRQ",
			"ISPFE_GIA_LEVEL_AGGR_10_DLI4_IRQ",
			"ISPFE_GIA_LEVEL_AGGR_10_DLI5_IRQ",
			"ISPFE_GIA_LEVEL_AGGR_10_DLI6_IRQ",
			"ISPFE_GIA_LEVEL_AGGR_10_DLI7_IRQ";
	};

	ispfe_level_aggr_5_intr_test: ispfe_level_aggr_5_intr_test {
		compatible = "google,gia-test";
		power-domains = <&sswrp_ispfe_pd>;
		interrupt-parent = <&ispfe_level_aggr_5_intr>;
		interrupts =
			<ISPFE_GIA_LEVEL_AGGR_5_DATA_RA0_NS_INTR>,
			<ISPFE_GIA_LEVEL_AGGR_5_DATA_RA1_NS_INTR>,
			<ISPFE_GIA_LEVEL_AGGR_5_DATA_RA2_NS_INTR>,
			<ISPFE_GIA_LEVEL_AGGR_5_DATA_RA3_NS_INTR>,
			<ISPFE_GIA_LEVEL_AGGR_5_DATA_XFW0_NS_INTR>,
			<ISPFE_GIA_LEVEL_AGGR_5_DATA_XFW1_NS_INTR>,
			<ISPFE_GIA_LEVEL_AGGR_5_DATA_XFW2_NS_INTR>,
			<ISPFE_GIA_LEVEL_AGGR_5_DATA_XFW3_NS_INTR>,
			<ISPFE_GIA_LEVEL_AGGR_5_CFG_BRG_RFW_NS_INTR>,
			<ISPFE_GIA_LEVEL_AGGR_5_GIA_PULSE_AGGR_5_INTR>,
			<ISPFE_GIA_LEVEL_AGGR_5_GIA_PULSE_AGGR_6_INTR>,
			<ISPFE_GIA_LEVEL_AGGR_5_GIA_LEVEL_AGGR_11_INTR>,
			<ISPFE_GIA_LEVEL_AGGR_5_CPRTISPFE_IFABRIC_RT_XBA0_ERR_IRQ>,
			<ISPFE_GIA_LEVEL_AGGR_5_GIA_PULSE_AGGR_7_INTR>,
			<ISPFE_GIA_LEVEL_AGGR_5_GIA_LEVEL_AGGR_12_INTR>;
		interrupt-names =
			"ISPFE_GIA_LEVEL_AGGR_5_DATA_RA0_NS_INTR",
			"ISPFE_GIA_LEVEL_AGGR_5_DATA_RA1_NS_INTR",
			"ISPFE_GIA_LEVEL_AGGR_5_DATA_RA2_NS_INTR",
			"ISPFE_GIA_LEVEL_AGGR_5_DATA_RA3_NS_INTR",
			"ISPFE_GIA_LEVEL_AGGR_5_DATA_XFW0_NS_INTR",
			"ISPFE_GIA_LEVEL_AGGR_5_DATA_XFW1_NS_INTR",
			"ISPFE_GIA_LEVEL_AGGR_5_DATA_XFW2_NS_INTR",
			"ISPFE_GIA_LEVEL_AGGR_5_DATA_XFW3_NS_INTR",
			"ISPFE_GIA_LEVEL_AGGR_5_CFG_BRG_RFW_NS_INTR",
			"ISPFE_GIA_LEVEL_AGGR_5_GIA_PULSE_AGGR_5_INTR",
			"ISPFE_GIA_LEVEL_AGGR_5_GIA_PULSE_AGGR_6_INTR",
			"ISPFE_GIA_LEVEL_AGGR_5_GIA_LEVEL_AGGR_11_INTR",
			"ISPFE_GIA_LEVEL_AGGR_5_CPRTISPFE_IFABRIC_RT_XBA0_ERR_IRQ",
			"ISPFE_GIA_LEVEL_AGGR_5_GIA_PULSE_AGGR_7_INTR",
			"ISPFE_GIA_LEVEL_AGGR_5_GIA_LEVEL_AGGR_12_INTR";
	};

	ispfe_pulse_aggr_5_intr_test: ispfe_pulse_aggr_5_intr_test {
		compatible = "google,gia-test";
		power-domains = <&sswrp_ispfe_pd>;
		interrupt-parent = <&ispfe_pulse_aggr_5_intr>;
		interrupts =
			<ISPFE_GIA_PULSE_AGGR_5_SMMU_TCU_EVENT_Q_IRPT_NS>,
			<ISPFE_GIA_PULSE_AGGR_5_SMMU_TCU_CMD_SYNC_IRPT_NS>,
			<ISPFE_GIA_PULSE_AGGR_5_SMMU_TCU_GLOBAL_IRPT_NS>,
			<ISPFE_GIA_PULSE_AGGR_5_SMMU_TCU_RAS_FHI>,
			<ISPFE_GIA_PULSE_AGGR_5_SMMU_TCU_RAS_ERI>,
			<ISPFE_GIA_PULSE_AGGR_5_SMMU_TCU_RAS_CRI>,
			<ISPFE_GIA_PULSE_AGGR_5_SMMU_TCU_PMU_IRPT>,
			<ISPFE_GIA_PULSE_AGGR_5_SMMU_TCU_PRI_Q_IRPT_NS>;
		interrupt-names =
			"ISPFE_GIA_PULSE_AGGR_5_SMMU_TCU_EVENT_Q_IRPT_NS",
			"ISPFE_GIA_PULSE_AGGR_5_SMMU_TCU_CMD_SYNC_IRPT_NS",
			"ISPFE_GIA_PULSE_AGGR_5_SMMU_TCU_GLOBAL_IRPT_NS",
			"ISPFE_GIA_PULSE_AGGR_5_SMMU_TCU_RAS_FHI",
			"ISPFE_GIA_PULSE_AGGR_5_SMMU_TCU_RAS_ERI",
			"ISPFE_GIA_PULSE_AGGR_5_SMMU_TCU_RAS_CRI",
			"ISPFE_GIA_PULSE_AGGR_5_SMMU_TCU_PMU_IRPT",
			"ISPFE_GIA_PULSE_AGGR_5_SMMU_TCU_PRI_Q_IRPT_NS";
	};

	ispfe_pulse_aggr_6_intr_test: ispfe_pulse_aggr_6_intr_test {
		compatible = "google,gia-test";
		power-domains = <&sswrp_ispfe_pd>;
		interrupt-parent = <&ispfe_pulse_aggr_6_intr>;
		interrupts =
			<ISPFE_GIA_PULSE_AGGR_6_SMMU_TBU0_RAS_FHI>,
			<ISPFE_GIA_PULSE_AGGR_6_SMMU_TBU1_RAS_FHI>,
			<ISPFE_GIA_PULSE_AGGR_6_SMMU_TBU2_RAS_FHI>,
			<ISPFE_GIA_PULSE_AGGR_6_SMMU_TBU3_RAS_FHI>,
			<ISPFE_GIA_PULSE_AGGR_6_SMMU_TBU0_RAS_ERI>,
			<ISPFE_GIA_PULSE_AGGR_6_SMMU_TBU1_RAS_ERI>,
			<ISPFE_GIA_PULSE_AGGR_6_SMMU_TBU2_RAS_ERI>,
			<ISPFE_GIA_PULSE_AGGR_6_SMMU_TBU3_RAS_ERI>,
			<ISPFE_GIA_PULSE_AGGR_6_SMMU_TBU0_RAS_CRI>,
			<ISPFE_GIA_PULSE_AGGR_6_SMMU_TBU1_RAS_CRI>,
			<ISPFE_GIA_PULSE_AGGR_6_SMMU_TBU2_RAS_CRI>,
			<ISPFE_GIA_PULSE_AGGR_6_SMMU_TBU3_RAS_CRI>,
			<ISPFE_GIA_PULSE_AGGR_6_SMMU_TBU0_PMU_IRPT>,
			<ISPFE_GIA_PULSE_AGGR_6_SMMU_TBU1_PMU_IRPT>,
			<ISPFE_GIA_PULSE_AGGR_6_SMMU_TBU2_PMU_IRPT>,
			<ISPFE_GIA_PULSE_AGGR_6_SMMU_TBU3_PMU_IRPT>;
		interrupt-names =
			"ISPFE_GIA_PULSE_AGGR_6_SMMU_TBU0_RAS_FHI",
			"ISPFE_GIA_PULSE_AGGR_6_SMMU_TBU1_RAS_FHI",
			"ISPFE_GIA_PULSE_AGGR_6_SMMU_TBU2_RAS_FHI",
			"ISPFE_GIA_PULSE_AGGR_6_SMMU_TBU3_RAS_FHI",
			"ISPFE_GIA_PULSE_AGGR_6_SMMU_TBU0_RAS_ERI",
			"ISPFE_GIA_PULSE_AGGR_6_SMMU_TBU1_RAS_ERI",
			"ISPFE_GIA_PULSE_AGGR_6_SMMU_TBU2_RAS_ERI",
			"ISPFE_GIA_PULSE_AGGR_6_SMMU_TBU3_RAS_ERI",
			"ISPFE_GIA_PULSE_AGGR_6_SMMU_TBU0_RAS_CRI",
			"ISPFE_GIA_PULSE_AGGR_6_SMMU_TBU1_RAS_CRI",
			"ISPFE_GIA_PULSE_AGGR_6_SMMU_TBU2_RAS_CRI",
			"ISPFE_GIA_PULSE_AGGR_6_SMMU_TBU3_RAS_CRI",
			"ISPFE_GIA_PULSE_AGGR_6_SMMU_TBU0_PMU_IRPT",
			"ISPFE_GIA_PULSE_AGGR_6_SMMU_TBU1_PMU_IRPT",
			"ISPFE_GIA_PULSE_AGGR_6_SMMU_TBU2_PMU_IRPT",
			"ISPFE_GIA_PULSE_AGGR_6_SMMU_TBU3_PMU_IRPT";
	};

	ispfe_level_aggr_11_intr_test: ispfe_level_aggr_11_intr_test {
		compatible = "google,gia-test";
		power-domains = <&sswrp_ispfe_pd>;
		interrupt-parent = <&ispfe_level_aggr_11_intr>;
		interrupts =
			<ISPFE_GIA_LEVEL_AGGR_11_TCU_GEM_IRQ>,
			<ISPFE_GIA_LEVEL_AGGR_11_DATA_GEM0_IRQ>,
			<ISPFE_GIA_LEVEL_AGGR_11_DATA_GEM1_IRQ>,
			<ISPFE_GIA_LEVEL_AGGR_11_DATA_GEM2_IRQ>,
			<ISPFE_GIA_LEVEL_AGGR_11_DATA_GEM3_IRQ>;
		interrupt-names =
			"ISPFE_GIA_LEVEL_AGGR_11_TCU_GEM_IRQ",
			"ISPFE_GIA_LEVEL_AGGR_11_DATA_GEM0_IRQ",
			"ISPFE_GIA_LEVEL_AGGR_11_DATA_GEM1_IRQ",
			"ISPFE_GIA_LEVEL_AGGR_11_DATA_GEM2_IRQ",
			"ISPFE_GIA_LEVEL_AGGR_11_DATA_GEM3_IRQ";
	};

	ispfe_pulse_aggr_7_intr_test: ispfe_pulse_aggr_7_intr_test {
		compatible = "google,gia-test";
		power-domains = <&sswrp_ispfe_pd>;
		interrupt-parent = <&ispfe_pulse_aggr_7_intr>;
		interrupts =
			<ISPFE_GIA_PULSE_AGGR_7_TCU_GSPAN_ICD_ERR_DSCGT>,
			<ISPFE_GIA_PULSE_AGGR_7_TRACE_GSPAN_ICD_ERR_DSCGT>,
			<ISPFE_GIA_PULSE_AGGR_7_DATA_GSPAN0_ICD_ERR_DSCGT>,
			<ISPFE_GIA_PULSE_AGGR_7_DATA_GSPAN1_ICD_ERR_DSCGT>,
			<ISPFE_GIA_PULSE_AGGR_7_DATA_GSPAN2_ICD_ERR_DSCGT>,
			<ISPFE_GIA_PULSE_AGGR_7_DATA_GSPAN3_ICD_ERR_DSCGT>;
		interrupt-names =
			"ISPFE_GIA_PULSE_AGGR_7_TCU_GSPAN_ICD_ERR_DSCGT",
			"ISPFE_GIA_PULSE_AGGR_7_TRACE_GSPAN_ICD_ERR_DSCGT",
			"ISPFE_GIA_PULSE_AGGR_7_DATA_GSPAN0_ICD_ERR_DSCGT",
			"ISPFE_GIA_PULSE_AGGR_7_DATA_GSPAN1_ICD_ERR_DSCGT",
			"ISPFE_GIA_PULSE_AGGR_7_DATA_GSPAN2_ICD_ERR_DSCGT",
			"ISPFE_GIA_PULSE_AGGR_7_DATA_GSPAN3_ICD_ERR_DSCGT";
	};

	ispfe_level_aggr_12_intr_test: ispfe_level_aggr_12_intr_test {
		compatible = "google,gia-test";
		power-domains = <&sswrp_ispfe_pd>;
		interrupt-parent = <&ispfe_level_aggr_12_intr>;
		interrupts =
			<ISPFE_GIA_LEVEL_AGGR_12_ELA_SMMU_ELAOUTPUT_0>,
			<ISPFE_GIA_LEVEL_AGGR_12_ELA_SMMU_ELAOUTPUT_1>,
			<ISPFE_GIA_LEVEL_AGGR_12_ELA_SMMU_ELAOUTPUT_2>,
			<ISPFE_GIA_LEVEL_AGGR_12_ELA_SMMU_ELAOUTPUT_3>;
		interrupt-names =
			"ISPFE_GIA_LEVEL_AGGR_12_ELA_SMMU_ELAOUTPUT_0",
			"ISPFE_GIA_LEVEL_AGGR_12_ELA_SMMU_ELAOUTPUT_1",
			"ISPFE_GIA_LEVEL_AGGR_12_ELA_SMMU_ELAOUTPUT_2",
			"ISPFE_GIA_LEVEL_AGGR_12_ELA_SMMU_ELAOUTPUT_3";
	};

	ispbe_level_aggr_ap_test: ispbe_level_aggr_ap_test {
		compatible = "google,gia-test";
		power-domains = <&sswrp_ispbe_pd>;
		interrupt-parent = <&ispbe_level_aggr_ap>;
		interrupts =
			<31>;
		interrupt-names =
			"TEST_LINE_31";
	};

	ispbe_level_aggr_ita_update_0_test: ispbe_level_aggr_ita_update_0_test {
		compatible = "google,gia-test";
		power-domains = <&sswrp_ispbe_pd>;
		interrupt-parent = <&ispbe_level_aggr_ita_update_0>;
		interrupts =
			<31>;
		interrupt-names =
			"TEST_LINE_31";
	};

	ispbe_level_aggr_ita_update_1_test: ispbe_level_aggr_ita_update_1_test {
		compatible = "google,gia-test";
		power-domains = <&sswrp_ispbe_pd>;
		interrupt-parent = <&ispbe_level_aggr_ita_update_1>;
		interrupts =
			<31>;
		interrupt-names =
			"TEST_LINE_31";
	};

	ispbe_level_aggr_ita_update_2_test: ispbe_level_aggr_ita_update_2_test {
		compatible = "google,gia-test";
		power-domains = <&sswrp_ispbe_pd>;
		interrupt-parent = <&ispbe_level_aggr_ita_update_2>;
		interrupts =
			<31>;
		interrupt-names =
			"TEST_LINE_31";
	};

	ispbe_level_aggr_ita_update_3_test: ispbe_level_aggr_ita_update_3_test {
		compatible = "google,gia-test";
		power-domains = <&sswrp_ispbe_pd>;
		interrupt-parent = <&ispbe_level_aggr_ita_update_3>;
		interrupts =
			<31>;
		interrupt-names =
			"TEST_LINE_31";
	};

	ispbe_level_aggr_ita_update_4_test: ispbe_level_aggr_ita_update_4_test {
		compatible = "google,gia-test";
		power-domains = <&sswrp_ispbe_pd>;
		interrupt-parent = <&ispbe_level_aggr_ita_update_4>;
		interrupts =
			<31>;
		interrupt-names =
			"TEST_LINE_31";
	};

	ispbe_level_aggr_ita_update_5_test: ispbe_level_aggr_ita_update_5_test {
		compatible = "google,gia-test";
		power-domains = <&sswrp_ispbe_pd>;
		interrupt-parent = <&ispbe_level_aggr_ita_update_5>;
		interrupts =
			<31>;
		interrupt-names =
			"TEST_LINE_31";
	};

	ispbe_level_aggr_ita_update_6_test: ispbe_level_aggr_ita_update_6_test {
		compatible = "google,gia-test";
		power-domains = <&sswrp_ispbe_pd>;
		interrupt-parent = <&ispbe_level_aggr_ita_update_6>;
		interrupts =
			<31>;
		interrupt-names =
			"TEST_LINE_31";
	};

	ispbe_level_aggr_ita_update_7_test: ispbe_level_aggr_ita_update_7_test {
		compatible = "google,gia-test";
		power-domains = <&sswrp_ispbe_pd>;
		interrupt-parent = <&ispbe_level_aggr_ita_update_7>;
		interrupts =
			<31>;
		interrupt-names =
			"TEST_LINE_31";
	};

	ispbe_level_aggr_ita_update_8_test: ispbe_level_aggr_ita_update_8_test {
		compatible = "google,gia-test";
		power-domains = <&sswrp_ispbe_pd>;
		interrupt-parent = <&ispbe_level_aggr_ita_update_8>;
		interrupts =
			<31>;
		interrupt-names =
			"TEST_LINE_31";
	};

	ispbe_level_aggr_ita_update_9_test: ispbe_level_aggr_ita_update_9_test {
		compatible = "google,gia-test";
		power-domains = <&sswrp_ispbe_pd>;
		interrupt-parent = <&ispbe_level_aggr_ita_update_9>;
		interrupts =
			<31>;
		interrupt-names =
			"TEST_LINE_31";
	};

	ispbe_level_aggr_ita_update_10_test: ispbe_level_aggr_ita_update_10_test {
		compatible = "google,gia-test";
		power-domains = <&sswrp_ispbe_pd>;
		interrupt-parent = <&ispbe_level_aggr_ita_update_10>;
		interrupts =
			<31>;
		interrupt-names =
			"TEST_LINE_31";
	};

	ispbe_level_aggr_ita_update_11_test: ispbe_level_aggr_ita_update_11_test {
		compatible = "google,gia-test";
		power-domains = <&sswrp_ispbe_pd>;
		interrupt-parent = <&ispbe_level_aggr_ita_update_11>;
		interrupts =
			<31>;
		interrupt-names =
			"TEST_LINE_31";
	};

	ispbe_level_aggr_ita_update_12_test: ispbe_level_aggr_ita_update_12_test {
		compatible = "google,gia-test";
		power-domains = <&sswrp_ispbe_pd>;
		interrupt-parent = <&ispbe_level_aggr_ita_update_12>;
		interrupts =
			<31>;
		interrupt-names =
			"TEST_LINE_31";
	};

	ispbe_level_aggr_ita_update_13_test: ispbe_level_aggr_ita_update_13_test {
		compatible = "google,gia-test";
		power-domains = <&sswrp_ispbe_pd>;
		interrupt-parent = <&ispbe_level_aggr_ita_update_13>;
		interrupts =
			<31>;
		interrupt-names =
			"TEST_LINE_31";
	};

	ispbe_level_aggr_ita_update_14_test: ispbe_level_aggr_ita_update_14_test {
		compatible = "google,gia-test";
		power-domains = <&sswrp_ispbe_pd>;
		interrupt-parent = <&ispbe_level_aggr_ita_update_14>;
		interrupts =
			<31>;
		interrupt-names =
			"TEST_LINE_31";
	};

	ispbe_level_aggr_ita_update_15_test: ispbe_level_aggr_ita_update_15_test {
		compatible = "google,gia-test";
		power-domains = <&sswrp_ispbe_pd>;
		interrupt-parent = <&ispbe_level_aggr_ita_update_15>;
		interrupts =
			<31>;
		interrupt-names =
			"TEST_LINE_31";
	};

	ispbe_level_aggr_ita_update_16_test: ispbe_level_aggr_ita_update_16_test {
		compatible = "google,gia-test";
		power-domains = <&sswrp_ispbe_pd>;
		interrupt-parent = <&ispbe_level_aggr_ita_update_16>;
		interrupts =
			<31>;
		interrupt-names =
			"TEST_LINE_31";
	};

	ispbe_level_aggr_ita_update_17_test: ispbe_level_aggr_ita_update_17_test {
		compatible = "google,gia-test";
		power-domains = <&sswrp_ispbe_pd>;
		interrupt-parent = <&ispbe_level_aggr_ita_update_17>;
		interrupts =
			<31>;
		interrupt-names =
			"TEST_LINE_31";
	};

	ispbe_level_aggr_ita_update_18_test: ispbe_level_aggr_ita_update_18_test {
		compatible = "google,gia-test";
		power-domains = <&sswrp_ispbe_pd>;
		interrupt-parent = <&ispbe_level_aggr_ita_update_18>;
		interrupts =
			<31>;
		interrupt-names =
			"TEST_LINE_31";
	};

	ispbe_level_aggr_ita_update_19_test: ispbe_level_aggr_ita_update_19_test {
		compatible = "google,gia-test";
		power-domains = <&sswrp_ispbe_pd>;
		interrupt-parent = <&ispbe_level_aggr_ita_update_19>;
		interrupts =
			<31>;
		interrupt-names =
			"TEST_LINE_31";
	};

	ispbe_level_aggr_ita_update_20_test: ispbe_level_aggr_ita_update_20_test {
		compatible = "google,gia-test";
		power-domains = <&sswrp_ispbe_pd>;
		interrupt-parent = <&ispbe_level_aggr_ita_update_20>;
		interrupts =
			<31>;
		interrupt-names =
			"TEST_LINE_31";
	};

	ispbe_level_aggr_ita_update_21_test: ispbe_level_aggr_ita_update_21_test {
		compatible = "google,gia-test";
		power-domains = <&sswrp_ispbe_pd>;
		interrupt-parent = <&ispbe_level_aggr_ita_update_21>;
		interrupts =
			<31>;
		interrupt-names =
			"TEST_LINE_31";
	};

	ispbe_level_aggr_ita_error_0_test: ispbe_level_aggr_ita_error_0_test {
		compatible = "google,gia-test";
		power-domains = <&sswrp_ispbe_pd>;
		interrupt-parent = <&ispbe_level_aggr_ita_error_0>;
		interrupts =
			<31>;
		interrupt-names =
			"TEST_LINE_31";
	};

	ispbe_level_aggr_ita_error_1_test: ispbe_level_aggr_ita_error_1_test {
		compatible = "google,gia-test";
		power-domains = <&sswrp_ispbe_pd>;
		interrupt-parent = <&ispbe_level_aggr_ita_error_1>;
		interrupts =
			<31>;
		interrupt-names =
			"TEST_LINE_31";
	};

	ispbe_level_aggr_ita_error_2_test: ispbe_level_aggr_ita_error_2_test {
		compatible = "google,gia-test";
		power-domains = <&sswrp_ispbe_pd>;
		interrupt-parent = <&ispbe_level_aggr_ita_error_2>;
		interrupts =
			<31>;
		interrupt-names =
			"TEST_LINE_31";
	};

	ispbe_level_aggr_ita_error_3_test: ispbe_level_aggr_ita_error_3_test {
		compatible = "google,gia-test";
		power-domains = <&sswrp_ispbe_pd>;
		interrupt-parent = <&ispbe_level_aggr_ita_error_3>;
		interrupts =
			<31>;
		interrupt-names =
			"TEST_LINE_31";
	};

	ispbe_level_aggr_ita_error_4_test: ispbe_level_aggr_ita_error_4_test {
		compatible = "google,gia-test";
		power-domains = <&sswrp_ispbe_pd>;
		interrupt-parent = <&ispbe_level_aggr_ita_error_4>;
		interrupts =
			<31>;
		interrupt-names =
			"TEST_LINE_31";
	};

	ispbe_level_aggr_ita_error_5_test: ispbe_level_aggr_ita_error_5_test {
		compatible = "google,gia-test";
		power-domains = <&sswrp_ispbe_pd>;
		interrupt-parent = <&ispbe_level_aggr_ita_error_5>;
		interrupts =
			<31>;
		interrupt-names =
			"TEST_LINE_31";
	};

	ispbe_level_aggr_ita_error_6_test: ispbe_level_aggr_ita_error_6_test {
		compatible = "google,gia-test";
		power-domains = <&sswrp_ispbe_pd>;
		interrupt-parent = <&ispbe_level_aggr_ita_error_6>;
		interrupts =
			<31>;
		interrupt-names =
			"TEST_LINE_31";
	};

	ispbe_level_aggr_ita_error_7_test: ispbe_level_aggr_ita_error_7_test {
		compatible = "google,gia-test";
		power-domains = <&sswrp_ispbe_pd>;
		interrupt-parent = <&ispbe_level_aggr_ita_error_7>;
		interrupts =
			<31>;
		interrupt-names =
			"TEST_LINE_31";
	};

	ispbe_level_aggr_ita_error_8_test: ispbe_level_aggr_ita_error_8_test {
		compatible = "google,gia-test";
		power-domains = <&sswrp_ispbe_pd>;
		interrupt-parent = <&ispbe_level_aggr_ita_error_8>;
		interrupts =
			<31>;
		interrupt-names =
			"TEST_LINE_31";
	};

	ispbe_level_aggr_ita_error_9_test: ispbe_level_aggr_ita_error_9_test {
		compatible = "google,gia-test";
		power-domains = <&sswrp_ispbe_pd>;
		interrupt-parent = <&ispbe_level_aggr_ita_error_9>;
		interrupts =
			<31>;
		interrupt-names =
			"TEST_LINE_31";
	};

	ispbe_level_aggr_ita_error_10_test: ispbe_level_aggr_ita_error_10_test {
		compatible = "google,gia-test";
		power-domains = <&sswrp_ispbe_pd>;
		interrupt-parent = <&ispbe_level_aggr_ita_error_10>;
		interrupts =
			<31>;
		interrupt-names =
			"TEST_LINE_31";
	};

	ispbe_level_aggr_ita_error_11_test: ispbe_level_aggr_ita_error_11_test {
		compatible = "google,gia-test";
		power-domains = <&sswrp_ispbe_pd>;
		interrupt-parent = <&ispbe_level_aggr_ita_error_11>;
		interrupts =
			<31>;
		interrupt-names =
			"TEST_LINE_31";
	};

	ispbe_level_aggr_ita_error_12_test: ispbe_level_aggr_ita_error_12_test {
		compatible = "google,gia-test";
		power-domains = <&sswrp_ispbe_pd>;
		interrupt-parent = <&ispbe_level_aggr_ita_error_12>;
		interrupts =
			<31>;
		interrupt-names =
			"TEST_LINE_31";
	};

	ispbe_level_aggr_ita_error_13_test: ispbe_level_aggr_ita_error_13_test {
		compatible = "google,gia-test";
		power-domains = <&sswrp_ispbe_pd>;
		interrupt-parent = <&ispbe_level_aggr_ita_error_13>;
		interrupts =
			<31>;
		interrupt-names =
			"TEST_LINE_31";
	};

	ispbe_level_aggr_ita_error_14_test: ispbe_level_aggr_ita_error_14_test {
		compatible = "google,gia-test";
		power-domains = <&sswrp_ispbe_pd>;
		interrupt-parent = <&ispbe_level_aggr_ita_error_14>;
		interrupts =
			<31>;
		interrupt-names =
			"TEST_LINE_31";
	};

	ispbe_level_aggr_ita_error_15_test: ispbe_level_aggr_ita_error_15_test {
		compatible = "google,gia-test";
		power-domains = <&sswrp_ispbe_pd>;
		interrupt-parent = <&ispbe_level_aggr_ita_error_15>;
		interrupts =
			<31>;
		interrupt-names =
			"TEST_LINE_31";
	};

	ispbe_level_aggr_ita_error_16_test: ispbe_level_aggr_ita_error_16_test {
		compatible = "google,gia-test";
		power-domains = <&sswrp_ispbe_pd>;
		interrupt-parent = <&ispbe_level_aggr_ita_error_16>;
		interrupts =
			<31>;
		interrupt-names =
			"TEST_LINE_31";
	};

	ispbe_level_aggr_ita_error_17_test: ispbe_level_aggr_ita_error_17_test {
		compatible = "google,gia-test";
		power-domains = <&sswrp_ispbe_pd>;
		interrupt-parent = <&ispbe_level_aggr_ita_error_17>;
		interrupts =
			<31>;
		interrupt-names =
			"TEST_LINE_31";
	};

	ispbe_level_aggr_ita_error_18_test: ispbe_level_aggr_ita_error_18_test {
		compatible = "google,gia-test";
		power-domains = <&sswrp_ispbe_pd>;
		interrupt-parent = <&ispbe_level_aggr_ita_error_18>;
		interrupts =
			<31>;
		interrupt-names =
			"TEST_LINE_31";
	};

	ispbe_level_aggr_ita_error_19_test: ispbe_level_aggr_ita_error_19_test {
		compatible = "google,gia-test";
		power-domains = <&sswrp_ispbe_pd>;
		interrupt-parent = <&ispbe_level_aggr_ita_error_19>;
		interrupts =
			<31>;
		interrupt-names =
			"TEST_LINE_31";
	};

	ispbe_level_aggr_ita_error_20_test: ispbe_level_aggr_ita_error_20_test {
		compatible = "google,gia-test";
		power-domains = <&sswrp_ispbe_pd>;
		interrupt-parent = <&ispbe_level_aggr_ita_error_20>;
		interrupts =
			<31>;
		interrupt-names =
			"TEST_LINE_31";
	};

	ispbe_level_aggr_ita_error_21_test: ispbe_level_aggr_ita_error_21_test {
		compatible = "google,gia-test";
		power-domains = <&sswrp_ispbe_pd>;
		interrupt-parent = <&ispbe_level_aggr_ita_error_21>;
		interrupts =
			<31>;
		interrupt-names =
			"TEST_LINE_31";
	};

	gsw_level_aggr_01_intr_test: gsw_level_aggr_01_intr_test {
		compatible = "google,gia-test";
		power-domains = <&sswrp_gsw_pd>;
		interrupt-parent = <&gsw_level_aggr_01_intr>;
		interrupts =
			<GSW_GIA_LEVEL_AGGR_01_DUMMY_GIA_ON_AC_GIA_PULSE_AGGR_0_INTR>,
			<GSW_GIA_LEVEL_AGGR_01_DUMMY_GIA_ON_AC_GIA_PULSE_AGGR_1_INTR>,
			<GSW_GIA_LEVEL_AGGR_01_DUMMY_GIA_ON_AC_GIA_PULSE_AGGR_2_INTR>,
			<GSW_GIA_LEVEL_AGGR_01_AUX_INNER_QCHWRAP_CORE_RFW_ON_AC_GIA_NS_INTR>,
			<GSW_GIA_LEVEL_AGGR_01_AUX_INNER_QCHWRAP_CORE_MFW0_ON_AC_GIA_NS_INTR>,
			<GSW_GIA_LEVEL_AGGR_01_AUX_INNER_QCHWRAP_CORE_MFW1_ON_AC_GIA_NS_INTR>,
			<GSW_GIA_LEVEL_AGGR_01_AUX_INNER_QCHWRAP_CORE_RA0_ON_AC_GIA_NS_INTR>,
			<GSW_GIA_LEVEL_AGGR_01_AUX_INNER_QCHWRAP_CORE_RA1_ON_AC_GIA_NS_INTR>,
			<GSW_GIA_LEVEL_AGGR_01_DUMMY_GIA_ON_AC_GIA_PULSE_AGGR_3_INTR>,
			<GSW_GIA_LEVEL_AGGR_01_DUMMY_GIA_ON_AC_GIA_PULSE_AGGR_7_INTR>,
			<GSW_GIA_LEVEL_AGGR_01_DUMMY_GIA_ON_AC_GIA_PULSE_AGGR_4_INTR>,
			<GSW_GIA_LEVEL_AGGR_01_DUMMY_GIA_ON_AC_GIA_PULSE_AGGR_8_INTR>,
			<GSW_GIA_LEVEL_AGGR_01_DUMMY_GIA_ON_AC_GIA_PULSE_AGGR_5_INTR>,
			<GSW_GIA_LEVEL_AGGR_01_DUMMY_GIA_ON_AC_GIA_PULSE_AGGR_9_INTR>,
			<GSW_GIA_LEVEL_AGGR_01_DUMMY_GIA_ON_AC_GIA_PULSE_AGGR_6_INTR>,
			<GSW_GIA_LEVEL_AGGR_01_DUMMY_GIA_ON_AC_GIA_PULSE_AGGR_10_INTR>;
		interrupt-names =
			"GSW_GIA_LEVEL_AGGR_01_DUMMY_GIA_ON_AC_GIA_PULSE_AGGR_0_INTR",
			"GSW_GIA_LEVEL_AGGR_01_DUMMY_GIA_ON_AC_GIA_PULSE_AGGR_1_INTR",
			"GSW_GIA_LEVEL_AGGR_01_DUMMY_GIA_ON_AC_GIA_PULSE_AGGR_2_INTR",
			"GSW_GIA_LEVEL_AGGR_01_AUX_INNER_QCHWRAP_CORE_RFW_ON_AC_GIA_NS_INTR",
			"GSW_GIA_LEVEL_AGGR_01_AUX_INNER_QCHWRAP_CORE_MFW0_ON_AC_GIA_NS_INTR",
			"GSW_GIA_LEVEL_AGGR_01_AUX_INNER_QCHWRAP_CORE_MFW1_ON_AC_GIA_NS_INTR",
			"GSW_GIA_LEVEL_AGGR_01_AUX_INNER_QCHWRAP_CORE_RA0_ON_AC_GIA_NS_INTR",
			"GSW_GIA_LEVEL_AGGR_01_AUX_INNER_QCHWRAP_CORE_RA1_ON_AC_GIA_NS_INTR",
			"GSW_GIA_LEVEL_AGGR_01_DUMMY_GIA_ON_AC_GIA_PULSE_AGGR_3_INTR",
			"GSW_GIA_LEVEL_AGGR_01_DUMMY_GIA_ON_AC_GIA_PULSE_AGGR_7_INTR",
			"GSW_GIA_LEVEL_AGGR_01_DUMMY_GIA_ON_AC_GIA_PULSE_AGGR_4_INTR",
			"GSW_GIA_LEVEL_AGGR_01_DUMMY_GIA_ON_AC_GIA_PULSE_AGGR_8_INTR",
			"GSW_GIA_LEVEL_AGGR_01_DUMMY_GIA_ON_AC_GIA_PULSE_AGGR_5_INTR",
			"GSW_GIA_LEVEL_AGGR_01_DUMMY_GIA_ON_AC_GIA_PULSE_AGGR_9_INTR",
			"GSW_GIA_LEVEL_AGGR_01_DUMMY_GIA_ON_AC_GIA_PULSE_AGGR_6_INTR",
			"GSW_GIA_LEVEL_AGGR_01_DUMMY_GIA_ON_AC_GIA_PULSE_AGGR_10_INTR";
	};

	lsioe_level_aggr_0_intr_test: lsioe_level_aggr_0_intr_test {
		compatible = "google,gia-test";
		power-domains = <&lsio_e_cli_gpio_pd>;
		interrupt-parent = <&lsioe_level_aggr_0_intr>;
		interrupts =
			<LSIOE_GIA_LEVEL_AGGR_0_AUX_AON_IOBANK_XLSIOE_CLI7_PIN0_IRQ>,
			<LSIOE_GIA_LEVEL_AGGR_0_AUX_AON_IOBANK_XLSIOE_CLI7_PIN1_IRQ>,
			<LSIOE_GIA_LEVEL_AGGR_0_AUX_AON_IOBANK_XLSIOE_CLI7_PIN2_IRQ>,
			<LSIOE_GIA_LEVEL_AGGR_0_AUX_AON_IOBANK_XLSIOE_CLI7_PIN3_IRQ>,
			<LSIOE_GIA_LEVEL_AGGR_0_AUX_AON_IOBANK_XLSIOE_CLI8_PIN0_IRQ>,
			<LSIOE_GIA_LEVEL_AGGR_0_AUX_AON_IOBANK_XLSIOE_CLI8_PIN1_IRQ>,
			<LSIOE_GIA_LEVEL_AGGR_0_AUX_AON_IOBANK_XLSIOE_CLI8_PIN2_IRQ>,
			<LSIOE_GIA_LEVEL_AGGR_0_AUX_AON_IOBANK_XLSIOE_CLI8_PIN3_IRQ>,
			<LSIOE_GIA_LEVEL_AGGR_0_AUX_AON_IOBANK_XLSIOE_CLI9_PIN0_IRQ>,
			<LSIOE_GIA_LEVEL_AGGR_0_AUX_AON_IOBANK_XLSIOE_CLI9_PIN1_IRQ>,
			<LSIOE_GIA_LEVEL_AGGR_0_AUX_AON_IOBANK_XLSIOE_CLI9_PIN2_IRQ>,
			<LSIOE_GIA_LEVEL_AGGR_0_AUX_AON_IOBANK_XLSIOE_CLI9_PIN3_IRQ>,
			<LSIOE_GIA_LEVEL_AGGR_0_AUX_AON_IOBANK_XLSIOE_CLI10_PIN0_IRQ>,
			<LSIOE_GIA_LEVEL_AGGR_0_AUX_AON_IOBANK_XLSIOE_CLI10_PIN1_IRQ>,
			<LSIOE_GIA_LEVEL_AGGR_0_AUX_AON_IOBANK_XLSIOE_CLI10_PIN2_IRQ>,
			<LSIOE_GIA_LEVEL_AGGR_0_AUX_AON_IOBANK_XLSIOE_CLI10_PIN3_IRQ>,
			<LSIOE_GIA_LEVEL_AGGR_0_AUX_AON_IOBANK_XLSIOE_CLI11_PIN0_IRQ>,
			<LSIOE_GIA_LEVEL_AGGR_0_AUX_AON_IOBANK_XLSIOE_CLI11_PIN1_IRQ>,
			<LSIOE_GIA_LEVEL_AGGR_0_AUX_AON_IOBANK_XLSIOE_CLI11_PIN2_IRQ>,
			<LSIOE_GIA_LEVEL_AGGR_0_AUX_AON_IOBANK_XLSIOE_CLI11_PIN3_IRQ>,
			<LSIOE_GIA_LEVEL_AGGR_0_AUX_AON_IOBANK_XLSIOE_CLI12_PIN0_IRQ>,
			<LSIOE_GIA_LEVEL_AGGR_0_AUX_AON_IOBANK_XLSIOE_CLI12_PIN1_IRQ>,
			<LSIOE_GIA_LEVEL_AGGR_0_AUX_AON_IOBANK_XLSIOE_CLI12_PIN2_IRQ>,
			<LSIOE_GIA_LEVEL_AGGR_0_AUX_AON_IOBANK_XLSIOE_CLI12_PIN3_IRQ>,
			<LSIOE_GIA_LEVEL_AGGR_0_AUX_AON_IOBANK_XLSIOE_CLI13_PIN0_IRQ>,
			<LSIOE_GIA_LEVEL_AGGR_0_AUX_AON_IOBANK_XLSIOE_CLI13_PIN1_IRQ>,
			<LSIOE_GIA_LEVEL_AGGR_0_AUX_AON_IOBANK_XLSIOE_CLI13_PIN2_IRQ>,
			<LSIOE_GIA_LEVEL_AGGR_0_AUX_AON_IOBANK_XLSIOE_CLI13_PIN3_IRQ>,
			<LSIOE_GIA_LEVEL_AGGR_0_AUX_AON_IOBANK_XLSIOE_CLI14_PIN0_IRQ>,
			<LSIOE_GIA_LEVEL_AGGR_0_AUX_AON_IOBANK_XLSIOE_CLI14_PIN1_IRQ>,
			<LSIOE_GIA_LEVEL_AGGR_0_AUX_AON_IOBANK_XLSIOE_CLI14_PIN2_IRQ>,
			<LSIOE_GIA_LEVEL_AGGR_0_AUX_AON_IOBANK_XLSIOE_CLI14_PIN3_IRQ>;
		interrupt-names =
			"LSIOE_GIA_LEVEL_AGGR_0_AUX_AON_IOBANK_XLSIOE_CLI7_PIN0_IRQ",
			"LSIOE_GIA_LEVEL_AGGR_0_AUX_AON_IOBANK_XLSIOE_CLI7_PIN1_IRQ",
			"LSIOE_GIA_LEVEL_AGGR_0_AUX_AON_IOBANK_XLSIOE_CLI7_PIN2_IRQ",
			"LSIOE_GIA_LEVEL_AGGR_0_AUX_AON_IOBANK_XLSIOE_CLI7_PIN3_IRQ",
			"LSIOE_GIA_LEVEL_AGGR_0_AUX_AON_IOBANK_XLSIOE_CLI8_PIN0_IRQ",
			"LSIOE_GIA_LEVEL_AGGR_0_AUX_AON_IOBANK_XLSIOE_CLI8_PIN1_IRQ",
			"LSIOE_GIA_LEVEL_AGGR_0_AUX_AON_IOBANK_XLSIOE_CLI8_PIN2_IRQ",
			"LSIOE_GIA_LEVEL_AGGR_0_AUX_AON_IOBANK_XLSIOE_CLI8_PIN3_IRQ",
			"LSIOE_GIA_LEVEL_AGGR_0_AUX_AON_IOBANK_XLSIOE_CLI9_PIN0_IRQ",
			"LSIOE_GIA_LEVEL_AGGR_0_AUX_AON_IOBANK_XLSIOE_CLI9_PIN1_IRQ",
			"LSIOE_GIA_LEVEL_AGGR_0_AUX_AON_IOBANK_XLSIOE_CLI9_PIN2_IRQ",
			"LSIOE_GIA_LEVEL_AGGR_0_AUX_AON_IOBANK_XLSIOE_CLI9_PIN3_IRQ",
			"LSIOE_GIA_LEVEL_AGGR_0_AUX_AON_IOBANK_XLSIOE_CLI10_PIN0_IRQ",
			"LSIOE_GIA_LEVEL_AGGR_0_AUX_AON_IOBANK_XLSIOE_CLI10_PIN1_IRQ",
			"LSIOE_GIA_LEVEL_AGGR_0_AUX_AON_IOBANK_XLSIOE_CLI10_PIN2_IRQ",
			"LSIOE_GIA_LEVEL_AGGR_0_AUX_AON_IOBANK_XLSIOE_CLI10_PIN3_IRQ",
			"LSIOE_GIA_LEVEL_AGGR_0_AUX_AON_IOBANK_XLSIOE_CLI11_PIN0_IRQ",
			"LSIOE_GIA_LEVEL_AGGR_0_AUX_AON_IOBANK_XLSIOE_CLI11_PIN1_IRQ",
			"LSIOE_GIA_LEVEL_AGGR_0_AUX_AON_IOBANK_XLSIOE_CLI11_PIN2_IRQ",
			"LSIOE_GIA_LEVEL_AGGR_0_AUX_AON_IOBANK_XLSIOE_CLI11_PIN3_IRQ",
			"LSIOE_GIA_LEVEL_AGGR_0_AUX_AON_IOBANK_XLSIOE_CLI12_PIN0_IRQ",
			"LSIOE_GIA_LEVEL_AGGR_0_AUX_AON_IOBANK_XLSIOE_CLI12_PIN1_IRQ",
			"LSIOE_GIA_LEVEL_AGGR_0_AUX_AON_IOBANK_XLSIOE_CLI12_PIN2_IRQ",
			"LSIOE_GIA_LEVEL_AGGR_0_AUX_AON_IOBANK_XLSIOE_CLI12_PIN3_IRQ",
			"LSIOE_GIA_LEVEL_AGGR_0_AUX_AON_IOBANK_XLSIOE_CLI13_PIN0_IRQ",
			"LSIOE_GIA_LEVEL_AGGR_0_AUX_AON_IOBANK_XLSIOE_CLI13_PIN1_IRQ",
			"LSIOE_GIA_LEVEL_AGGR_0_AUX_AON_IOBANK_XLSIOE_CLI13_PIN2_IRQ",
			"LSIOE_GIA_LEVEL_AGGR_0_AUX_AON_IOBANK_XLSIOE_CLI13_PIN3_IRQ",
			"LSIOE_GIA_LEVEL_AGGR_0_AUX_AON_IOBANK_XLSIOE_CLI14_PIN0_IRQ",
			"LSIOE_GIA_LEVEL_AGGR_0_AUX_AON_IOBANK_XLSIOE_CLI14_PIN1_IRQ",
			"LSIOE_GIA_LEVEL_AGGR_0_AUX_AON_IOBANK_XLSIOE_CLI14_PIN2_IRQ",
			"LSIOE_GIA_LEVEL_AGGR_0_AUX_AON_IOBANK_XLSIOE_CLI14_PIN3_IRQ";
	};

	lsioe_level_aggr_4_intr_test: lsioe_level_aggr_4_intr_test {
		compatible = "google,gia-test";
		power-domains = <&lsio_e_cli_gpio_pd>;
		interrupt-parent = <&lsioe_level_aggr_4_intr>;
		interrupts =
			<LSIOE_GIA_LEVEL_AGGR_4_IP_TOP_CLI7_CLI_INT>,
			<LSIOE_GIA_LEVEL_AGGR_4_IP_TOP_CLI8_CLI_INT>,
			<LSIOE_GIA_LEVEL_AGGR_4_IP_TOP_CLI9_CLI_INT>,
			<LSIOE_GIA_LEVEL_AGGR_4_IP_TOP_CLI10_CLI_INT>,
			<LSIOE_GIA_LEVEL_AGGR_4_IP_TOP_CLI11_CLI_INT>,
			<LSIOE_GIA_LEVEL_AGGR_4_IP_TOP_CLI12_CLI_INT>,
			<LSIOE_GIA_LEVEL_AGGR_4_IP_TOP_CLI13_CLI_INT>,
			<LSIOE_GIA_LEVEL_AGGR_4_IP_TOP_CLI14_CLI_INT>,
			<LSIOE_GIA_LEVEL_AGGR_4_IP_TOP_SPMI_O_IRQ>;
		interrupt-names =
			"LSIOE_GIA_LEVEL_AGGR_4_IP_TOP_CLI7_CLI_INT",
			"LSIOE_GIA_LEVEL_AGGR_4_IP_TOP_CLI8_CLI_INT",
			"LSIOE_GIA_LEVEL_AGGR_4_IP_TOP_CLI9_CLI_INT",
			"LSIOE_GIA_LEVEL_AGGR_4_IP_TOP_CLI10_CLI_INT",
			"LSIOE_GIA_LEVEL_AGGR_4_IP_TOP_CLI11_CLI_INT",
			"LSIOE_GIA_LEVEL_AGGR_4_IP_TOP_CLI12_CLI_INT",
			"LSIOE_GIA_LEVEL_AGGR_4_IP_TOP_CLI13_CLI_INT",
			"LSIOE_GIA_LEVEL_AGGR_4_IP_TOP_CLI14_CLI_INT",
			"LSIOE_GIA_LEVEL_AGGR_4_IP_TOP_SPMI_O_IRQ";
	};

	lsioe_level_aggr_13_intr_test: lsioe_level_aggr_13_intr_test {
		compatible = "google,gia-test";
		power-domains = <&lsio_e_cli_gpio_pd>;
		interrupt-parent = <&lsioe_level_aggr_13_intr>;
		interrupts =
			<LSIOE_GIA_LEVEL_AGGR_13_AUX_AON_RFW0_NS_INTR>,
			<LSIOE_GIA_LEVEL_AGGR_13_AUX_RFW1_NS_INTR>,
			<LSIOE_GIA_LEVEL_AGGR_13_AUX_GEM0_IRQ>;
		interrupt-names =
			"LSIOE_GIA_LEVEL_AGGR_13_AUX_AON_RFW0_NS_INTR",
			"LSIOE_GIA_LEVEL_AGGR_13_AUX_RFW1_NS_INTR",
			"LSIOE_GIA_LEVEL_AGGR_13_AUX_GEM0_IRQ";
	};

	lsion_level_aggr_0_intr_test: lsion_level_aggr_0_intr_test {
		compatible = "google,gia-test";
		power-domains = <&lsio_n_cli_gpio_pd>;
		interrupt-parent = <&lsion_level_aggr_0_intr>;
		interrupts =
			<LSION_GIA_LEVEL_AGGR_0_AUX_AON_IOBANK_XLSION_CLI15_PIN0_IRQ>,
			<LSION_GIA_LEVEL_AGGR_0_AUX_AON_IOBANK_XLSION_CLI15_PIN1_IRQ>,
			<LSION_GIA_LEVEL_AGGR_0_AUX_AON_IOBANK_XLSION_CLI15_PIN2_IRQ>,
			<LSION_GIA_LEVEL_AGGR_0_AUX_AON_IOBANK_XLSION_CLI15_PIN3_IRQ>,
			<LSION_GIA_LEVEL_AGGR_0_AUX_AON_IOBANK_XLSION_CLI16_PIN0_IRQ>,
			<LSION_GIA_LEVEL_AGGR_0_AUX_AON_IOBANK_XLSION_CLI16_PIN1_IRQ>,
			<LSION_GIA_LEVEL_AGGR_0_AUX_AON_IOBANK_XLSION_CLI16_PIN2_IRQ>,
			<LSION_GIA_LEVEL_AGGR_0_AUX_AON_IOBANK_XLSION_CLI16_PIN3_IRQ>;
		interrupt-names =
			"LSION_GIA_LEVEL_AGGR_0_AUX_AON_IOBANK_XLSION_CLI15_PIN0_IRQ",
			"LSION_GIA_LEVEL_AGGR_0_AUX_AON_IOBANK_XLSION_CLI15_PIN1_IRQ",
			"LSION_GIA_LEVEL_AGGR_0_AUX_AON_IOBANK_XLSION_CLI15_PIN2_IRQ",
			"LSION_GIA_LEVEL_AGGR_0_AUX_AON_IOBANK_XLSION_CLI15_PIN3_IRQ",
			"LSION_GIA_LEVEL_AGGR_0_AUX_AON_IOBANK_XLSION_CLI16_PIN0_IRQ",
			"LSION_GIA_LEVEL_AGGR_0_AUX_AON_IOBANK_XLSION_CLI16_PIN1_IRQ",
			"LSION_GIA_LEVEL_AGGR_0_AUX_AON_IOBANK_XLSION_CLI16_PIN2_IRQ",
			"LSION_GIA_LEVEL_AGGR_0_AUX_AON_IOBANK_XLSION_CLI16_PIN3_IRQ";
	};

	lsion_level_aggr_4_intr_test: lsion_level_aggr_4_intr_test {
		compatible = "google,gia-test";
		power-domains = <&lsio_n_cli_gpio_pd>;
		interrupt-parent = <&lsion_level_aggr_4_intr>;
		interrupts =
			<LSION_GIA_LEVEL_AGGR_4_IP_TOP_CLI_INT0_CLI_INT>,
			<LSION_GIA_LEVEL_AGGR_4_IP_TOP_CLI_INT1_CLI_INT>,
			<LSION_GIA_LEVEL_AGGR_4_IP_TOP_CLI_INT2_CLI_INT>,
			<LSION_GIA_LEVEL_AGGR_4_IP_TOP_CLI_INT3_CLI_INT>,
			<LSION_GIA_LEVEL_AGGR_4_IP_TOP_CLI_INT4_CLI_INT>,
			<LSION_GIA_LEVEL_AGGR_4_IP_TOP_CLI15_CLI_INT>,
			<LSION_GIA_LEVEL_AGGR_4_IP_TOP_CLI16_CLI_INT>;
		interrupt-names =
			"LSION_GIA_LEVEL_AGGR_4_IP_TOP_CLI_INT0_CLI_INT",
			"LSION_GIA_LEVEL_AGGR_4_IP_TOP_CLI_INT1_CLI_INT",
			"LSION_GIA_LEVEL_AGGR_4_IP_TOP_CLI_INT2_CLI_INT",
			"LSION_GIA_LEVEL_AGGR_4_IP_TOP_CLI_INT3_CLI_INT",
			"LSION_GIA_LEVEL_AGGR_4_IP_TOP_CLI_INT4_CLI_INT",
			"LSION_GIA_LEVEL_AGGR_4_IP_TOP_CLI15_CLI_INT",
			"LSION_GIA_LEVEL_AGGR_4_IP_TOP_CLI16_CLI_INT";
	};

	lsion_level_aggr_13_intr_test: lsion_level_aggr_13_intr_test {
		compatible = "google,gia-test";
		power-domains = <&lsio_n_cli_gpio_pd>;
		interrupt-parent = <&lsion_level_aggr_13_intr>;
		interrupts =
			<LSION_GIA_LEVEL_AGGR_13_AUX_AON_RFW0_NS_INTR>,
			<LSION_GIA_LEVEL_AGGR_13_AUX_RFW1_NS_INTR>,
			<LSION_GIA_LEVEL_AGGR_13_AUX_GEM0_IRQ>;
		interrupt-names =
			"LSION_GIA_LEVEL_AGGR_13_AUX_AON_RFW0_NS_INTR",
			"LSION_GIA_LEVEL_AGGR_13_AUX_RFW1_NS_INTR",
			"LSION_GIA_LEVEL_AGGR_13_AUX_GEM0_IRQ";
	};

	lsios_level_aggr_0_intr_test: lsios_level_aggr_0_intr_test {
		compatible = "google,gia-test";
		power-domains = <&lsio_s_cli_gpio_pd>;
		interrupt-parent = <&lsios_level_aggr_0_intr>;
		interrupts =
			<LSIOS_GIA_LEVEL_AGGR_0_AUX_AON_IOBANK_XLSIOS_CLI0_PIN0_IRQ>,
			<LSIOS_GIA_LEVEL_AGGR_0_AUX_AON_IOBANK_XLSIOS_CLI0_PIN1_IRQ>,
			<LSIOS_GIA_LEVEL_AGGR_0_AUX_AON_IOBANK_XLSIOS_CLI0_PIN2_IRQ>,
			<LSIOS_GIA_LEVEL_AGGR_0_AUX_AON_IOBANK_XLSIOS_CLI0_PIN3_IRQ>,
			<LSIOS_GIA_LEVEL_AGGR_0_AUX_AON_IOBANK_XLSIOS_CLI1_PIN0_IRQ>,
			<LSIOS_GIA_LEVEL_AGGR_0_AUX_AON_IOBANK_XLSIOS_CLI1_PIN1_IRQ>,
			<LSIOS_GIA_LEVEL_AGGR_0_AUX_AON_IOBANK_XLSIOS_CLI1_PIN2_IRQ>,
			<LSIOS_GIA_LEVEL_AGGR_0_AUX_AON_IOBANK_XLSIOS_CLI1_PIN3_IRQ>,
			<LSIOS_GIA_LEVEL_AGGR_0_AUX_AON_IOBANK_XLSIOS_CLI2_PIN0_IRQ>,
			<LSIOS_GIA_LEVEL_AGGR_0_AUX_AON_IOBANK_XLSIOS_CLI2_PIN1_IRQ>,
			<LSIOS_GIA_LEVEL_AGGR_0_AUX_AON_IOBANK_XLSIOS_CLI2_PIN2_IRQ>,
			<LSIOS_GIA_LEVEL_AGGR_0_AUX_AON_IOBANK_XLSIOS_CLI2_PIN3_IRQ>,
			<LSIOS_GIA_LEVEL_AGGR_0_AUX_AON_IOBANK_XLSIOS_CLI3_PIN0_IRQ>,
			<LSIOS_GIA_LEVEL_AGGR_0_AUX_AON_IOBANK_XLSIOS_CLI3_PIN1_IRQ>,
			<LSIOS_GIA_LEVEL_AGGR_0_AUX_AON_IOBANK_XLSIOS_CLI3_PIN2_IRQ>,
			<LSIOS_GIA_LEVEL_AGGR_0_AUX_AON_IOBANK_XLSIOS_CLI3_PIN3_IRQ>,
			<LSIOS_GIA_LEVEL_AGGR_0_AUX_AON_IOBANK_XLSIOS_CLI4_PIN0_IRQ>,
			<LSIOS_GIA_LEVEL_AGGR_0_AUX_AON_IOBANK_XLSIOS_CLI4_PIN1_IRQ>,
			<LSIOS_GIA_LEVEL_AGGR_0_AUX_AON_IOBANK_XLSIOS_CLI4_PIN2_IRQ>,
			<LSIOS_GIA_LEVEL_AGGR_0_AUX_AON_IOBANK_XLSIOS_CLI4_PIN3_IRQ>,
			<LSIOS_GIA_LEVEL_AGGR_0_AUX_AON_IOBANK_XLSIOS_CLI5_PIN0_IRQ>,
			<LSIOS_GIA_LEVEL_AGGR_0_AUX_AON_IOBANK_XLSIOS_CLI5_PIN1_IRQ>,
			<LSIOS_GIA_LEVEL_AGGR_0_AUX_AON_IOBANK_XLSIOS_CLI5_PIN2_IRQ>,
			<LSIOS_GIA_LEVEL_AGGR_0_AUX_AON_IOBANK_XLSIOS_CLI5_PIN3_IRQ>,
			<LSIOS_GIA_LEVEL_AGGR_0_AUX_AON_IOBANK_XLSIOS_CLI6_PIN0_IRQ>,
			<LSIOS_GIA_LEVEL_AGGR_0_AUX_AON_IOBANK_XLSIOS_CLI6_PIN1_IRQ>,
			<LSIOS_GIA_LEVEL_AGGR_0_AUX_AON_IOBANK_XLSIOS_CLI6_PIN2_IRQ>,
			<LSIOS_GIA_LEVEL_AGGR_0_AUX_AON_IOBANK_XLSIOS_CLI6_PIN3_IRQ>,
			<LSIOS_GIA_LEVEL_AGGR_0_AUX_AON_IOBANK_XLSIOS_GPIO0_IRQ>,
			<LSIOS_GIA_LEVEL_AGGR_0_AUX_AON_IOBANK_XLSIOS_GPIO1_IRQ>,
			<LSIOS_GIA_LEVEL_AGGR_0_AUX_AON_IOBANK_XLSIOS_GPIO2_IRQ>,
			<LSIOS_GIA_LEVEL_AGGR_0_AUX_AON_IOBANK_XLSIOS_GPIO3_IRQ>,
			<LSIOS_GIA_LEVEL_AGGR_0_AUX_AON_IOBANK_XLSIOS_GPIO4_IRQ>,
			<LSIOS_GIA_LEVEL_AGGR_0_AUX_AON_IOBANK_XLSIOS_GPIO5_IRQ>,
			<LSIOS_GIA_LEVEL_AGGR_0_AUX_AON_IOBANK_XLSIOS_MCLK0_IRQ>,
			<LSIOS_GIA_LEVEL_AGGR_0_AUX_AON_IOBANK_XLSIOS_MCLK1_IRQ>,
			<LSIOS_GIA_LEVEL_AGGR_0_AUX_AON_IOBANK_XLSIOS_MCLK2_IRQ>,
			<LSIOS_GIA_LEVEL_AGGR_0_AUX_AON_IOBANK_XLSIOS_MCLK3_IRQ>,
			<LSIOS_GIA_LEVEL_AGGR_0_AUX_AON_IOBANK_XLSIOS_MCLK4_IRQ>,
			<LSIOS_GIA_LEVEL_AGGR_0_AUX_AON_IOBANK_XLSIOS_MCLK5_IRQ>,
			<LSIOS_GIA_LEVEL_AGGR_0_AUX_AON_IOBANK_XLSIOS_MCLK6_IRQ>,
			<LSIOS_GIA_LEVEL_AGGR_0_AUX_AON_IOBANK_XLSIOS_MCLK7_IRQ>,
			<LSIOS_GIA_LEVEL_AGGR_0_AUX_AON_IOBANK_XLSIOS_PWM_0_IRQ>,
			<LSIOS_GIA_LEVEL_AGGR_0_AUX_AON_IOBANK_XLSIOS_PWM_1_IRQ>,
			<LSIOS_GIA_LEVEL_AGGR_0_AUX_AON_IOBANK_XLSIOS_PWM_2_IRQ>,
			<LSIOS_GIA_LEVEL_AGGR_0_AUX_AON_IOBANK_XLSIOS_VSYNC0_IRQ>,
			<LSIOS_GIA_LEVEL_AGGR_0_AUX_AON_IOBANK_XLSIOS_VSYNC1_IRQ>,
			<LSIOS_GIA_LEVEL_AGGR_0_AUX_AON_IOBANK_XLSIOS_VSYNC2_IRQ>,
			<LSIOS_GIA_LEVEL_AGGR_0_AUX_AON_IOBANK_XLSIOS_VSYNC3_IRQ>,
			<LSIOS_GIA_LEVEL_AGGR_0_AUX_AON_IOBANK_XLSIOS_VSYNC5_IRQ>,
			<LSIOS_GIA_LEVEL_AGGR_0_AUX_AON_IOBANK_XLSIOS_VSYNC6_IRQ>,
			<LSIOS_GIA_LEVEL_AGGR_0_AUX_AON_IOBANK_XLSIOS_VSYNC7_IRQ>,
			<LSIOS_GIA_LEVEL_AGGR_0_AUX_AON_IOBANK_XLSIOS_PRE_OCP_GPU_IRQ>,
			<LSIOS_GIA_LEVEL_AGGR_0_AUX_AON_IOBANK_XLSIOS_SOFT_PRE_OCP_GPU_IRQ>;
		interrupt-names =
			"LSIOS_GIA_LEVEL_AGGR_0_AUX_AON_IOBANK_XLSIOS_CLI0_PIN0_IRQ",
			"LSIOS_GIA_LEVEL_AGGR_0_AUX_AON_IOBANK_XLSIOS_CLI0_PIN1_IRQ",
			"LSIOS_GIA_LEVEL_AGGR_0_AUX_AON_IOBANK_XLSIOS_CLI0_PIN2_IRQ",
			"LSIOS_GIA_LEVEL_AGGR_0_AUX_AON_IOBANK_XLSIOS_CLI0_PIN3_IRQ",
			"LSIOS_GIA_LEVEL_AGGR_0_AUX_AON_IOBANK_XLSIOS_CLI1_PIN0_IRQ",
			"LSIOS_GIA_LEVEL_AGGR_0_AUX_AON_IOBANK_XLSIOS_CLI1_PIN1_IRQ",
			"LSIOS_GIA_LEVEL_AGGR_0_AUX_AON_IOBANK_XLSIOS_CLI1_PIN2_IRQ",
			"LSIOS_GIA_LEVEL_AGGR_0_AUX_AON_IOBANK_XLSIOS_CLI1_PIN3_IRQ",
			"LSIOS_GIA_LEVEL_AGGR_0_AUX_AON_IOBANK_XLSIOS_CLI2_PIN0_IRQ",
			"LSIOS_GIA_LEVEL_AGGR_0_AUX_AON_IOBANK_XLSIOS_CLI2_PIN1_IRQ",
			"LSIOS_GIA_LEVEL_AGGR_0_AUX_AON_IOBANK_XLSIOS_CLI2_PIN2_IRQ",
			"LSIOS_GIA_LEVEL_AGGR_0_AUX_AON_IOBANK_XLSIOS_CLI2_PIN3_IRQ",
			"LSIOS_GIA_LEVEL_AGGR_0_AUX_AON_IOBANK_XLSIOS_CLI3_PIN0_IRQ",
			"LSIOS_GIA_LEVEL_AGGR_0_AUX_AON_IOBANK_XLSIOS_CLI3_PIN1_IRQ",
			"LSIOS_GIA_LEVEL_AGGR_0_AUX_AON_IOBANK_XLSIOS_CLI3_PIN2_IRQ",
			"LSIOS_GIA_LEVEL_AGGR_0_AUX_AON_IOBANK_XLSIOS_CLI3_PIN3_IRQ",
			"LSIOS_GIA_LEVEL_AGGR_0_AUX_AON_IOBANK_XLSIOS_CLI4_PIN0_IRQ",
			"LSIOS_GIA_LEVEL_AGGR_0_AUX_AON_IOBANK_XLSIOS_CLI4_PIN1_IRQ",
			"LSIOS_GIA_LEVEL_AGGR_0_AUX_AON_IOBANK_XLSIOS_CLI4_PIN2_IRQ",
			"LSIOS_GIA_LEVEL_AGGR_0_AUX_AON_IOBANK_XLSIOS_CLI4_PIN3_IRQ",
			"LSIOS_GIA_LEVEL_AGGR_0_AUX_AON_IOBANK_XLSIOS_CLI5_PIN0_IRQ",
			"LSIOS_GIA_LEVEL_AGGR_0_AUX_AON_IOBANK_XLSIOS_CLI5_PIN1_IRQ",
			"LSIOS_GIA_LEVEL_AGGR_0_AUX_AON_IOBANK_XLSIOS_CLI5_PIN2_IRQ",
			"LSIOS_GIA_LEVEL_AGGR_0_AUX_AON_IOBANK_XLSIOS_CLI5_PIN3_IRQ",
			"LSIOS_GIA_LEVEL_AGGR_0_AUX_AON_IOBANK_XLSIOS_CLI6_PIN0_IRQ",
			"LSIOS_GIA_LEVEL_AGGR_0_AUX_AON_IOBANK_XLSIOS_CLI6_PIN1_IRQ",
			"LSIOS_GIA_LEVEL_AGGR_0_AUX_AON_IOBANK_XLSIOS_CLI6_PIN2_IRQ",
			"LSIOS_GIA_LEVEL_AGGR_0_AUX_AON_IOBANK_XLSIOS_CLI6_PIN3_IRQ",
			"LSIOS_GIA_LEVEL_AGGR_0_AUX_AON_IOBANK_XLSIOS_GPIO0_IRQ",
			"LSIOS_GIA_LEVEL_AGGR_0_AUX_AON_IOBANK_XLSIOS_GPIO1_IRQ",
			"LSIOS_GIA_LEVEL_AGGR_0_AUX_AON_IOBANK_XLSIOS_GPIO2_IRQ",
			"LSIOS_GIA_LEVEL_AGGR_0_AUX_AON_IOBANK_XLSIOS_GPIO3_IRQ",
			"LSIOS_GIA_LEVEL_AGGR_0_AUX_AON_IOBANK_XLSIOS_GPIO4_IRQ",
			"LSIOS_GIA_LEVEL_AGGR_0_AUX_AON_IOBANK_XLSIOS_GPIO5_IRQ",
			"LSIOS_GIA_LEVEL_AGGR_0_AUX_AON_IOBANK_XLSIOS_MCLK0_IRQ",
			"LSIOS_GIA_LEVEL_AGGR_0_AUX_AON_IOBANK_XLSIOS_MCLK1_IRQ",
			"LSIOS_GIA_LEVEL_AGGR_0_AUX_AON_IOBANK_XLSIOS_MCLK2_IRQ",
			"LSIOS_GIA_LEVEL_AGGR_0_AUX_AON_IOBANK_XLSIOS_MCLK3_IRQ",
			"LSIOS_GIA_LEVEL_AGGR_0_AUX_AON_IOBANK_XLSIOS_MCLK4_IRQ",
			"LSIOS_GIA_LEVEL_AGGR_0_AUX_AON_IOBANK_XLSIOS_MCLK5_IRQ",
			"LSIOS_GIA_LEVEL_AGGR_0_AUX_AON_IOBANK_XLSIOS_MCLK6_IRQ",
			"LSIOS_GIA_LEVEL_AGGR_0_AUX_AON_IOBANK_XLSIOS_MCLK7_IRQ",
			"LSIOS_GIA_LEVEL_AGGR_0_AUX_AON_IOBANK_XLSIOS_PWM_0_IRQ",
			"LSIOS_GIA_LEVEL_AGGR_0_AUX_AON_IOBANK_XLSIOS_PWM_1_IRQ",
			"LSIOS_GIA_LEVEL_AGGR_0_AUX_AON_IOBANK_XLSIOS_PWM_2_IRQ",
			"LSIOS_GIA_LEVEL_AGGR_0_AUX_AON_IOBANK_XLSIOS_VSYNC0_IRQ",
			"LSIOS_GIA_LEVEL_AGGR_0_AUX_AON_IOBANK_XLSIOS_VSYNC1_IRQ",
			"LSIOS_GIA_LEVEL_AGGR_0_AUX_AON_IOBANK_XLSIOS_VSYNC2_IRQ",
			"LSIOS_GIA_LEVEL_AGGR_0_AUX_AON_IOBANK_XLSIOS_VSYNC3_IRQ",
			"LSIOS_GIA_LEVEL_AGGR_0_AUX_AON_IOBANK_XLSIOS_VSYNC5_IRQ",
			"LSIOS_GIA_LEVEL_AGGR_0_AUX_AON_IOBANK_XLSIOS_VSYNC6_IRQ",
			"LSIOS_GIA_LEVEL_AGGR_0_AUX_AON_IOBANK_XLSIOS_VSYNC7_IRQ",
			"LSIOS_GIA_LEVEL_AGGR_0_AUX_AON_IOBANK_XLSIOS_PRE_OCP_GPU_IRQ",
			"LSIOS_GIA_LEVEL_AGGR_0_AUX_AON_IOBANK_XLSIOS_SOFT_PRE_OCP_GPU_IRQ";
	};

	lsios_level_aggr_4_intr_test: lsios_level_aggr_4_intr_test {
		compatible = "google,gia-test";
		power-domains = <&lsio_s_cli_gpio_pd>;
		interrupt-parent = <&lsios_level_aggr_4_intr>;
		interrupts =
			<LSIOS_GIA_LEVEL_AGGR_4_IP_TOP_CLI0_CLI_INT>,
			<LSIOS_GIA_LEVEL_AGGR_4_IP_TOP_CLI1_CLI_INT>,
			<LSIOS_GIA_LEVEL_AGGR_4_IP_TOP_CLI2_CLI_INT>,
			<LSIOS_GIA_LEVEL_AGGR_4_IP_TOP_CLI3_CLI_INT>,
			<LSIOS_GIA_LEVEL_AGGR_4_IP_TOP_CLI4_CLI_INT>,
			<LSIOS_GIA_LEVEL_AGGR_4_IP_TOP_CLI5_CLI_INT>,
			<LSIOS_GIA_LEVEL_AGGR_4_IP_TOP_CLI6_CLI_INT>,
			<LSIOS_GIA_LEVEL_AGGR_4_IP_TOP_FTPWMTMR010_TMR1_INTR>,
			<LSIOS_GIA_LEVEL_AGGR_4_IP_TOP_FTPWMTMR010_TMR2_INTR>,
			<LSIOS_GIA_LEVEL_AGGR_4_IP_TOP_FTPWMTMR010_TMR3_INTR>,
			<LSIOS_GIA_LEVEL_AGGR_4_IP_TOP_FTPWMTMR010_TMR4_INTR>,
			<LSIOS_GIA_LEVEL_AGGR_4_IP_TOP_QSPI_SSI_INTR>;
		interrupt-names =
			"LSIOS_GIA_LEVEL_AGGR_4_IP_TOP_CLI0_CLI_INT",
			"LSIOS_GIA_LEVEL_AGGR_4_IP_TOP_CLI1_CLI_INT",
			"LSIOS_GIA_LEVEL_AGGR_4_IP_TOP_CLI2_CLI_INT",
			"LSIOS_GIA_LEVEL_AGGR_4_IP_TOP_CLI3_CLI_INT",
			"LSIOS_GIA_LEVEL_AGGR_4_IP_TOP_CLI4_CLI_INT",
			"LSIOS_GIA_LEVEL_AGGR_4_IP_TOP_CLI5_CLI_INT",
			"LSIOS_GIA_LEVEL_AGGR_4_IP_TOP_CLI6_CLI_INT",
			"LSIOS_GIA_LEVEL_AGGR_4_IP_TOP_FTPWMTMR010_TMR1_INTR",
			"LSIOS_GIA_LEVEL_AGGR_4_IP_TOP_FTPWMTMR010_TMR2_INTR",
			"LSIOS_GIA_LEVEL_AGGR_4_IP_TOP_FTPWMTMR010_TMR3_INTR",
			"LSIOS_GIA_LEVEL_AGGR_4_IP_TOP_FTPWMTMR010_TMR4_INTR",
			"LSIOS_GIA_LEVEL_AGGR_4_IP_TOP_QSPI_SSI_INTR";
	};

	lsios_level_aggr_13_intr_test: lsios_level_aggr_13_intr_test {
		compatible = "google,gia-test";
		power-domains = <&lsio_s_cli_gpio_pd>;
		interrupt-parent = <&lsios_level_aggr_13_intr>;
		interrupts =
			<LSIOS_GIA_LEVEL_AGGR_13_AUX_AON_RFW0_NS_INTR>,
			<LSIOS_GIA_LEVEL_AGGR_13_AUX_RFW1_NS_INTR>,
			<LSIOS_GIA_LEVEL_AGGR_13_AUX_GEM0_IRQ>;
		interrupt-names =
			"LSIOS_GIA_LEVEL_AGGR_13_AUX_AON_RFW0_NS_INTR",
			"LSIOS_GIA_LEVEL_AGGR_13_AUX_RFW1_NS_INTR",
			"LSIOS_GIA_LEVEL_AGGR_13_AUX_GEM0_IRQ";
	};

	memss_multicast_aggr_0_intr_test: memss_multicast_aggr_0_intr_test {
		compatible = "google,gia-test";
		interrupt-parent = <&memss_multicast_aggr_0_intr>;
		interrupts =
			<MEMSS_GIA_MULTICAST_AGGR_0_INST_IP2_FAB_FMC_FMC_INT>;
		interrupt-names =
			"MEMSS_GIA_MULTICAST_AGGR_0_INST_IP2_FAB_FMC_FMC_INT";
	};

	memss_multicast_aggr_17_intr_test: memss_multicast_aggr_17_intr_test {
		compatible = "google,gia-test";
		interrupt-parent = <&memss_multicast_aggr_17_intr>;
		interrupts =
			<MEMSS_GIA_MULTICAST_AGGR_17_INST_IP2_FAB_FAB_DP_IXBAR0_IRQ>,
			<MEMSS_GIA_MULTICAST_AGGR_17_INST_IP2_FAB_FAB_DP_IXBAR1_IRQ>,
			<MEMSS_GIA_MULTICAST_AGGR_17_INST_IP2_FAB_FAB_DP_IXBAR2_IRQ>,
			<MEMSS_GIA_MULTICAST_AGGR_17_INST_IP2_FAB_FAB_DP_IXBAR3_IRQ>,
			<MEMSS_GIA_MULTICAST_AGGR_17_INST_IP2_FAB_FAB_DP_IXBAR5_IRQ>,
			<MEMSS_GIA_MULTICAST_AGGR_17_INST_IP2_FAB_FAB_DP_IXBAR6_IRQ>,
			<MEMSS_GIA_MULTICAST_AGGR_17_INST_IP2_FAB_FAB_DP_IXBAR8_IRQ>,
			<MEMSS_GIA_MULTICAST_AGGR_17_INST_IP2_FAB_FAB_CP_IXBAR0_IRQ>,
			<MEMSS_GIA_MULTICAST_AGGR_17_INST_IP2_FAB_FAB_CP_IXBAR1_IRQ>,
			<MEMSS_GIA_MULTICAST_AGGR_17_INST_IP2_FAB_GMCC_NOC_IRQ>,
			<MEMSS_GIA_MULTICAST_AGGR_17_INST_IP2_FAB_CPU_MTSX_ACELS_GEM_IRQ>,
			<MEMSS_GIA_MULTICAST_AGGR_17_INST_IP2_FAB_CPU_HND_ACELS_GEM_IRQ>,
			<MEMSS_GIA_MULTICAST_AGGR_17_INST_IP2_FAB_CPU_PCIEHNI_ACELS_GEM_IRQ>,
			<MEMSS_GIA_MULTICAST_AGGR_17_INST_IP2_FAB_HBWFAB_IWL_GEM_IRQ>,
			<MEMSS_GIA_MULTICAST_AGGR_17_INST_IP2_FAB_CPU_CTRLP_IWL_GEM_IRQ>,
			<MEMSS_GIA_MULTICAST_AGGR_17_INST_IP2_FAB_FABHBW_CTRLP_IWL_GEM_IRQ>;
		interrupt-names =
			"MEMSS_GIA_MULTICAST_AGGR_17_INST_IP2_FAB_FAB_DP_IXBAR0_IRQ",
			"MEMSS_GIA_MULTICAST_AGGR_17_INST_IP2_FAB_FAB_DP_IXBAR1_IRQ",
			"MEMSS_GIA_MULTICAST_AGGR_17_INST_IP2_FAB_FAB_DP_IXBAR2_IRQ",
			"MEMSS_GIA_MULTICAST_AGGR_17_INST_IP2_FAB_FAB_DP_IXBAR3_IRQ",
			"MEMSS_GIA_MULTICAST_AGGR_17_INST_IP2_FAB_FAB_DP_IXBAR5_IRQ",
			"MEMSS_GIA_MULTICAST_AGGR_17_INST_IP2_FAB_FAB_DP_IXBAR6_IRQ",
			"MEMSS_GIA_MULTICAST_AGGR_17_INST_IP2_FAB_FAB_DP_IXBAR8_IRQ",
			"MEMSS_GIA_MULTICAST_AGGR_17_INST_IP2_FAB_FAB_CP_IXBAR0_IRQ",
			"MEMSS_GIA_MULTICAST_AGGR_17_INST_IP2_FAB_FAB_CP_IXBAR1_IRQ",
			"MEMSS_GIA_MULTICAST_AGGR_17_INST_IP2_FAB_GMCC_NOC_IRQ",
			"MEMSS_GIA_MULTICAST_AGGR_17_INST_IP2_FAB_CPU_MTSX_ACELS_GEM_IRQ",
			"MEMSS_GIA_MULTICAST_AGGR_17_INST_IP2_FAB_CPU_HND_ACELS_GEM_IRQ",
			"MEMSS_GIA_MULTICAST_AGGR_17_INST_IP2_FAB_CPU_PCIEHNI_ACELS_GEM_IRQ",
			"MEMSS_GIA_MULTICAST_AGGR_17_INST_IP2_FAB_HBWFAB_IWL_GEM_IRQ",
			"MEMSS_GIA_MULTICAST_AGGR_17_INST_IP2_FAB_CPU_CTRLP_IWL_GEM_IRQ",
			"MEMSS_GIA_MULTICAST_AGGR_17_INST_IP2_FAB_FABHBW_CTRLP_IWL_GEM_IRQ";
	};

	memss_multicast_aggr_21_intr_test: memss_multicast_aggr_21_intr_test {
		compatible = "google,gia-test";
		interrupt-parent = <&memss_multicast_aggr_21_intr>;
		interrupts =
			<MEMSS_GIA_MULTICAST_AGGR_21_INST_IP2_FAB_SLC_FAB_DVFSMON_IRQ>,
			<MEMSS_GIA_MULTICAST_AGGR_21_INST_IP2_FAB_ACEL_CPU_DVFSMON_IRQ>,
			<MEMSS_GIA_MULTICAST_AGGR_21_INST_IP2_FAB_IWL_HBW_DVFSMON_IRQ>,
			<MEMSS_GIA_MULTICAST_AGGR_21_INST_IP2_FAB_IWL_RT_DVFSMON_IRQ>,
			<MEMSS_GIA_MULTICAST_AGGR_21_INST_IP2_FAB_IWL_STBY_DVFSMON_IRQ>;
		interrupt-names =
			"MEMSS_GIA_MULTICAST_AGGR_21_INST_IP2_FAB_SLC_FAB_DVFSMON_IRQ",
			"MEMSS_GIA_MULTICAST_AGGR_21_INST_IP2_FAB_ACEL_CPU_DVFSMON_IRQ",
			"MEMSS_GIA_MULTICAST_AGGR_21_INST_IP2_FAB_IWL_HBW_DVFSMON_IRQ",
			"MEMSS_GIA_MULTICAST_AGGR_21_INST_IP2_FAB_IWL_RT_DVFSMON_IRQ",
			"MEMSS_GIA_MULTICAST_AGGR_21_INST_IP2_FAB_IWL_STBY_DVFSMON_IRQ";
	};

	memss_multicast_aggr_11_intr_test: memss_multicast_aggr_11_intr_test {
		compatible = "google,gia-test";
		interrupt-parent = <&memss_multicast_aggr_11_intr>;
		interrupts =
			<MEMSS_GIA_MULTICAST_AGGR_11_INST_IP2_FAB_SLC_PPMFW0_NS_INTR>,
			<MEMSS_GIA_MULTICAST_AGGR_11_INST_IP2_FAB_SLC_PPMFW1_NS_INTR>,
			<MEMSS_GIA_MULTICAST_AGGR_11_INST_IP2_FAB_SLC_PPMFW2_NS_INTR>,
			<MEMSS_GIA_MULTICAST_AGGR_11_INST_IP2_FAB_SLC_PPMFW3_NS_INTR>;
		interrupt-names =
			"MEMSS_GIA_MULTICAST_AGGR_11_INST_IP2_FAB_SLC_PPMFW0_NS_INTR",
			"MEMSS_GIA_MULTICAST_AGGR_11_INST_IP2_FAB_SLC_PPMFW1_NS_INTR",
			"MEMSS_GIA_MULTICAST_AGGR_11_INST_IP2_FAB_SLC_PPMFW2_NS_INTR",
			"MEMSS_GIA_MULTICAST_AGGR_11_INST_IP2_FAB_SLC_PPMFW3_NS_INTR";
	};

	memss_multicast_aggr_5_intr_test: memss_multicast_aggr_5_intr_test {
		compatible = "google,gia-test";
		interrupt-parent = <&memss_multicast_aggr_5_intr>;
		interrupts =
			<MEMSS_GIA_MULTICAST_AGGR_5_INST_IP2_FAB_SLC_RFW_NS_INTR_RFW_NS_IRQ_GSLC>,
			<MEMSS_GIA_MULTICAST_AGGR_5_INST_IP2_FAB_LPCM_RFW_NS_INTR_RFW_NS_IRQ_LPCM>,
			<MEMSS_GIA_MULTICAST_AGGR_5_INST_IP2_FAB_FABMEM_RFW_NS_INTR_RFW_NS_IRQ_FABMEM>,
			<MEMSS_GIA_MULTICAST_AGGR_5_INST_IP2_FAB_CTRLFAB_RFW_NS_INTR_RFW_NS_IRQ_CTRLFAB>,
			<MEMSS_GIA_MULTICAST_AGGR_5_INST_IP2_FAB_FMC_RFW_NS_INTR_RFW_NS_IRQ_FMC>,
			<MEMSS_GIA_MULTICAST_AGGR_5_INST_IP2_FAB_GMCC_RFW_NS_INTR_RFW_NS_IRQ_GMCC>,
			<MEMSS_GIA_MULTICAST_AGGR_5_INST_IP2_FAB_DTA_RFW_NS_INTR_RFW_NS_IRQ_DTA>,
			<MEMSS_GIA_MULTICAST_AGGR_5_INST_IP2_FAB_DVFSMON_RFW_NS_INTR_RFW_NS_IRQ_DVFSMON>,
			<MEMSS_GIA_MULTICAST_AGGR_5_INST_IP2_FAB_GEM_FABMEM_CPU_ACEL_RFW_NS_INTR_RFW_NS_IRQ_GEM_CPU_ACEL>,
			<MEMSS_GIA_MULTICAST_AGGR_5_INST_IP2_FAB_RFW_CP_CPU_IWL_NS_INTR_RFW_NS_IRQ_GEM_CPU_CP>,
			<MEMSS_GIA_MULTICAST_AGGR_5_INST_IP2_FAB_RFW_FABMEM_CPU_HND_ACEL_NS_INTR_RFW_NS_IRQ_GEM_CPU_HND>,
			<MEMSS_GIA_MULTICAST_AGGR_5_INST_IP2_FAB_RFW_FABMEM_CPU_PCIEHNI_ACEL_NS_INTR_RFW_NS_IRQ_GEM_CPU_PCIE>,
			<MEMSS_GIA_MULTICAST_AGGR_5_INST_IP2_FAB_RFW_FABMEM_HBWFAB_IWL_NS_INTR_RFW_NS_IRQ_GEM_HBWFAB_IWL>,
			<MEMSS_GIA_MULTICAST_AGGR_5_INST_IP2_FAB_RFW_CP_HBWFAB_IWL_NS_INTR_RFW_NS_IRQ_GEM_HBWFAB_CP>,
			<MEMSS_GIA_MULTICAST_AGGR_5_INST_IP2_FAB_MAIN_RFW_NS_INTR_RFW_NS_IRQ_CFG>,
			<MEMSS_GIA_MULTICAST_AGGR_5_INST_IP2_FAB_DVFSMON_ACEL_CPU_RFW_NS_INTR_RFW_NS_IRQ_ACEL_CPU_DVFSMON>,
			<MEMSS_GIA_MULTICAST_AGGR_5_INST_IP2_FAB_DVFSMON_IWL_HBW_RFW_NS_INTR_RFW_NS_IRQ_IWL_HBW_DVFSMON>,
			<MEMSS_GIA_MULTICAST_AGGR_5_INST_IP2_FAB_DVFSMON_IWL_RT_RFW_NS_INTR_RFW_NS_IRQ_IWL_RT_DVFSMON>,
			<MEMSS_GIA_MULTICAST_AGGR_5_INST_IP2_FAB_DVFSMON_IWL_STBY_RFW_NS_INTR_RFW_NS_IRQ_IWL_STBY_DVFSMON>;
		interrupt-names =
			"MEMSS_GIA_MULTICAST_AGGR_5_INST_IP2_FAB_SLC_RFW_NS_INTR_RFW_NS_IRQ_GSLC",
			"MEMSS_GIA_MULTICAST_AGGR_5_INST_IP2_FAB_LPCM_RFW_NS_INTR_RFW_NS_IRQ_LPCM",
			"MEMSS_GIA_MULTICAST_AGGR_5_INST_IP2_FAB_FABMEM_RFW_NS_INTR_RFW_NS_IRQ_FABMEM",
			"MEMSS_GIA_MULTICAST_AGGR_5_INST_IP2_FAB_CTRLFAB_RFW_NS_INTR_RFW_NS_IRQ_CTRLFAB",
			"MEMSS_GIA_MULTICAST_AGGR_5_INST_IP2_FAB_FMC_RFW_NS_INTR_RFW_NS_IRQ_FMC",
			"MEMSS_GIA_MULTICAST_AGGR_5_INST_IP2_FAB_GMCC_RFW_NS_INTR_RFW_NS_IRQ_GMCC",
			"MEMSS_GIA_MULTICAST_AGGR_5_INST_IP2_FAB_DTA_RFW_NS_INTR_RFW_NS_IRQ_DTA",
			"MEMSS_GIA_MULTICAST_AGGR_5_INST_IP2_FAB_DVFSMON_RFW_NS_INTR_RFW_NS_IRQ_DVFSMON",
			"MEMSS_GIA_MULTICAST_AGGR_5_INST_IP2_FAB_GEM_FABMEM_CPU_ACEL_RFW_NS_INTR_RFW_NS_IRQ_GEM_CPU_ACEL",
			"MEMSS_GIA_MULTICAST_AGGR_5_INST_IP2_FAB_RFW_CP_CPU_IWL_NS_INTR_RFW_NS_IRQ_GEM_CPU_CP",
			"MEMSS_GIA_MULTICAST_AGGR_5_INST_IP2_FAB_RFW_FABMEM_CPU_HND_ACEL_NS_INTR_RFW_NS_IRQ_GEM_CPU_HND",
			"MEMSS_GIA_MULTICAST_AGGR_5_INST_IP2_FAB_RFW_FABMEM_CPU_PCIEHNI_ACEL_NS_INTR_RFW_NS_IRQ_GEM_CPU_PCIE",
			"MEMSS_GIA_MULTICAST_AGGR_5_INST_IP2_FAB_RFW_FABMEM_HBWFAB_IWL_NS_INTR_RFW_NS_IRQ_GEM_HBWFAB_IWL",
			"MEMSS_GIA_MULTICAST_AGGR_5_INST_IP2_FAB_RFW_CP_HBWFAB_IWL_NS_INTR_RFW_NS_IRQ_GEM_HBWFAB_CP",
			"MEMSS_GIA_MULTICAST_AGGR_5_INST_IP2_FAB_MAIN_RFW_NS_INTR_RFW_NS_IRQ_CFG",
			"MEMSS_GIA_MULTICAST_AGGR_5_INST_IP2_FAB_DVFSMON_ACEL_CPU_RFW_NS_INTR_RFW_NS_IRQ_ACEL_CPU_DVFSMON",
			"MEMSS_GIA_MULTICAST_AGGR_5_INST_IP2_FAB_DVFSMON_IWL_HBW_RFW_NS_INTR_RFW_NS_IRQ_IWL_HBW_DVFSMON",
			"MEMSS_GIA_MULTICAST_AGGR_5_INST_IP2_FAB_DVFSMON_IWL_RT_RFW_NS_INTR_RFW_NS_IRQ_IWL_RT_DVFSMON",
			"MEMSS_GIA_MULTICAST_AGGR_5_INST_IP2_FAB_DVFSMON_IWL_STBY_RFW_NS_INTR_RFW_NS_IRQ_IWL_STBY_DVFSMON";
	};

	tpu_level_aggr_0_intr_test: tpu_level_aggr_0_intr_test {
		compatible = "google,gia-test";
		power-domains = <&sswrp_tpu_pd>;
		interrupt-parent = <&tpu_level_aggr_0_intr>;
		interrupts =
			<TPU_GIA_LEVEL_AGGR_0_AUX_AON_RFW_LPCM_NS_INTR>,
			<TPU_GIA_LEVEL_AGGR_0_AUX_AON_RFW_NS_INTR>,
			<TPU_GIA_LEVEL_AGGR_0_AUX_LOGIC_CFG_BRIDGE_RFW_NS_INTR>,
			<TPU_GIA_LEVEL_AGGR_0_AUX_LOGIC_MFW_TBU0_NS_INTR>,
			<TPU_GIA_LEVEL_AGGR_0_AUX_LOGIC_MFW_TBU1_NS_INTR>,
			<TPU_GIA_LEVEL_AGGR_0_AUX_LOGIC_MFW_TBU2_NS_INTR>,
			<TPU_GIA_LEVEL_AGGR_0_AUX_LOGIC_MFW_TBU3_NS_INTR>,
			<TPU_GIA_LEVEL_AGGR_0_AUX_LOGIC_MAIN_ACELITE_RA0_NS_INTR>,
			<TPU_GIA_LEVEL_AGGR_0_AUX_LOGIC_MAIN_ACELITE_RA1_NS_INTR>,
			<TPU_GIA_LEVEL_AGGR_0_AUX_LOGIC_MAIN_ACELITE_RA2_NS_INTR>,
			<TPU_GIA_LEVEL_AGGR_0_AUX_LOGIC_MAIN_ACELITE_RA3_NS_INTR>,
			<TPU_GIA_LEVEL_AGGR_0_DUMMY_GIA_PULSE_AGGR_0_INTR>,
			<TPU_GIA_LEVEL_AGGR_0_DUMMY_GIA_PULSE_AGGR_1_INTR>,
			<TPU_GIA_LEVEL_AGGR_0_AUX_LOGIC_GEM_TCU_IRQ>,
			<TPU_GIA_LEVEL_AGGR_0_AUX_LOGIC_GEM_MAIN0_IRQ>,
			<TPU_GIA_LEVEL_AGGR_0_AUX_LOGIC_GEM_MAIN1_IRQ>,
			<TPU_GIA_LEVEL_AGGR_0_AUX_LOGIC_GEM_MAIN2_IRQ>,
			<TPU_GIA_LEVEL_AGGR_0_AUX_LOGIC_GEM_MAIN3_IRQ>,
			<TPU_GIA_LEVEL_AGGR_0_AUX_LOGIC_CTRLPLN_XBA0_ERR_IRQ>;
		interrupt-names =
			"TPU_GIA_LEVEL_AGGR_0_AUX_AON_RFW_LPCM_NS_INTR",
			"TPU_GIA_LEVEL_AGGR_0_AUX_AON_RFW_NS_INTR",
			"TPU_GIA_LEVEL_AGGR_0_AUX_LOGIC_CFG_BRIDGE_RFW_NS_INTR",
			"TPU_GIA_LEVEL_AGGR_0_AUX_LOGIC_MFW_TBU0_NS_INTR",
			"TPU_GIA_LEVEL_AGGR_0_AUX_LOGIC_MFW_TBU1_NS_INTR",
			"TPU_GIA_LEVEL_AGGR_0_AUX_LOGIC_MFW_TBU2_NS_INTR",
			"TPU_GIA_LEVEL_AGGR_0_AUX_LOGIC_MFW_TBU3_NS_INTR",
			"TPU_GIA_LEVEL_AGGR_0_AUX_LOGIC_MAIN_ACELITE_RA0_NS_INTR",
			"TPU_GIA_LEVEL_AGGR_0_AUX_LOGIC_MAIN_ACELITE_RA1_NS_INTR",
			"TPU_GIA_LEVEL_AGGR_0_AUX_LOGIC_MAIN_ACELITE_RA2_NS_INTR",
			"TPU_GIA_LEVEL_AGGR_0_AUX_LOGIC_MAIN_ACELITE_RA3_NS_INTR",
			"TPU_GIA_LEVEL_AGGR_0_DUMMY_GIA_PULSE_AGGR_0_INTR",
			"TPU_GIA_LEVEL_AGGR_0_DUMMY_GIA_PULSE_AGGR_1_INTR",
			"TPU_GIA_LEVEL_AGGR_0_AUX_LOGIC_GEM_TCU_IRQ",
			"TPU_GIA_LEVEL_AGGR_0_AUX_LOGIC_GEM_MAIN0_IRQ",
			"TPU_GIA_LEVEL_AGGR_0_AUX_LOGIC_GEM_MAIN1_IRQ",
			"TPU_GIA_LEVEL_AGGR_0_AUX_LOGIC_GEM_MAIN2_IRQ",
			"TPU_GIA_LEVEL_AGGR_0_AUX_LOGIC_GEM_MAIN3_IRQ",
			"TPU_GIA_LEVEL_AGGR_0_AUX_LOGIC_CTRLPLN_XBA0_ERR_IRQ";
	};

	tpu_pulse_aggr_0_intr_test: tpu_pulse_aggr_0_intr_test {
		compatible = "google,gia-test";
		power-domains = <&sswrp_tpu_pd>;
		interrupt-parent = <&tpu_pulse_aggr_0_intr>;
		interrupts =
			<TPU_GIA_PULSE_AGGR_0_AUX_LOGIC_SMMU_WRAPPER_TBU0_RAS_FHI>,
			<TPU_GIA_PULSE_AGGR_0_AUX_LOGIC_SMMU_WRAPPER_TBU0_RAS_ERI>,
			<TPU_GIA_PULSE_AGGR_0_AUX_LOGIC_SMMU_WRAPPER_TBU0_RAS_CRI>,
			<TPU_GIA_PULSE_AGGR_0_AUX_LOGIC_SMMU_WRAPPER_TBU0_PMU_IRPT>,
			<TPU_GIA_PULSE_AGGR_0_AUX_LOGIC_SMMU_WRAPPER_TBU1_RAS_FHI>,
			<TPU_GIA_PULSE_AGGR_0_AUX_LOGIC_SMMU_WRAPPER_TBU1_RAS_ERI>,
			<TPU_GIA_PULSE_AGGR_0_AUX_LOGIC_SMMU_WRAPPER_TBU1_RAS_CRI>,
			<TPU_GIA_PULSE_AGGR_0_AUX_LOGIC_SMMU_WRAPPER_TBU1_PMU_IRPT>,
			<TPU_GIA_PULSE_AGGR_0_AUX_LOGIC_SMMU_WRAPPER_TBU2_RAS_FHI>,
			<TPU_GIA_PULSE_AGGR_0_AUX_LOGIC_SMMU_WRAPPER_TBU2_RAS_ERI>,
			<TPU_GIA_PULSE_AGGR_0_AUX_LOGIC_SMMU_WRAPPER_TBU2_RAS_CRI>,
			<TPU_GIA_PULSE_AGGR_0_AUX_LOGIC_SMMU_WRAPPER_TBU2_PMU_IRPT>,
			<TPU_GIA_PULSE_AGGR_0_AUX_LOGIC_SMMU_WRAPPER_TBU3_RAS_FHI>,
			<TPU_GIA_PULSE_AGGR_0_AUX_LOGIC_SMMU_WRAPPER_TBU3_RAS_ERI>,
			<TPU_GIA_PULSE_AGGR_0_AUX_LOGIC_SMMU_WRAPPER_TBU3_RAS_CRI>,
			<TPU_GIA_PULSE_AGGR_0_AUX_LOGIC_SMMU_WRAPPER_TBU3_PMU_IRPT>,
			<TPU_GIA_PULSE_AGGR_0_AUX_LOGIC_SMMU_WRAPPER_TCU_RAS_FHI>,
			<TPU_GIA_PULSE_AGGR_0_AUX_LOGIC_SMMU_WRAPPER_TCU_RAS_ERI>,
			<TPU_GIA_PULSE_AGGR_0_AUX_LOGIC_SMMU_WRAPPER_TCU_RAS_CRI>,
			<TPU_GIA_PULSE_AGGR_0_AUX_LOGIC_SMMU_WRAPPER_TCU_PMU_IRPT>,
			<TPU_GIA_PULSE_AGGR_0_AUX_LOGIC_SMMU_WRAPPER_TCU_PRI_Q_IRPT_NS>,
			<TPU_GIA_PULSE_AGGR_0_AUX_LOGIC_SMMU_WRAPPER_TCU_GLOBAL_IRPT_NS>,
			<TPU_GIA_PULSE_AGGR_0_AUX_LOGIC_SMMU_WRAPPER_TCU_CMD_SYNC_IRPT_NS>,
			<TPU_GIA_PULSE_AGGR_0_AUX_LOGIC_SMMU_WRAPPER_TCU_EVENT_Q_IRPT_NS>;
		interrupt-names =
			"TPU_GIA_PULSE_AGGR_0_AUX_LOGIC_SMMU_WRAPPER_TBU0_RAS_FHI",
			"TPU_GIA_PULSE_AGGR_0_AUX_LOGIC_SMMU_WRAPPER_TBU0_RAS_ERI",
			"TPU_GIA_PULSE_AGGR_0_AUX_LOGIC_SMMU_WRAPPER_TBU0_RAS_CRI",
			"TPU_GIA_PULSE_AGGR_0_AUX_LOGIC_SMMU_WRAPPER_TBU0_PMU_IRPT",
			"TPU_GIA_PULSE_AGGR_0_AUX_LOGIC_SMMU_WRAPPER_TBU1_RAS_FHI",
			"TPU_GIA_PULSE_AGGR_0_AUX_LOGIC_SMMU_WRAPPER_TBU1_RAS_ERI",
			"TPU_GIA_PULSE_AGGR_0_AUX_LOGIC_SMMU_WRAPPER_TBU1_RAS_CRI",
			"TPU_GIA_PULSE_AGGR_0_AUX_LOGIC_SMMU_WRAPPER_TBU1_PMU_IRPT",
			"TPU_GIA_PULSE_AGGR_0_AUX_LOGIC_SMMU_WRAPPER_TBU2_RAS_FHI",
			"TPU_GIA_PULSE_AGGR_0_AUX_LOGIC_SMMU_WRAPPER_TBU2_RAS_ERI",
			"TPU_GIA_PULSE_AGGR_0_AUX_LOGIC_SMMU_WRAPPER_TBU2_RAS_CRI",
			"TPU_GIA_PULSE_AGGR_0_AUX_LOGIC_SMMU_WRAPPER_TBU2_PMU_IRPT",
			"TPU_GIA_PULSE_AGGR_0_AUX_LOGIC_SMMU_WRAPPER_TBU3_RAS_FHI",
			"TPU_GIA_PULSE_AGGR_0_AUX_LOGIC_SMMU_WRAPPER_TBU3_RAS_ERI",
			"TPU_GIA_PULSE_AGGR_0_AUX_LOGIC_SMMU_WRAPPER_TBU3_RAS_CRI",
			"TPU_GIA_PULSE_AGGR_0_AUX_LOGIC_SMMU_WRAPPER_TBU3_PMU_IRPT",
			"TPU_GIA_PULSE_AGGR_0_AUX_LOGIC_SMMU_WRAPPER_TCU_RAS_FHI",
			"TPU_GIA_PULSE_AGGR_0_AUX_LOGIC_SMMU_WRAPPER_TCU_RAS_ERI",
			"TPU_GIA_PULSE_AGGR_0_AUX_LOGIC_SMMU_WRAPPER_TCU_RAS_CRI",
			"TPU_GIA_PULSE_AGGR_0_AUX_LOGIC_SMMU_WRAPPER_TCU_PMU_IRPT",
			"TPU_GIA_PULSE_AGGR_0_AUX_LOGIC_SMMU_WRAPPER_TCU_PRI_Q_IRPT_NS",
			"TPU_GIA_PULSE_AGGR_0_AUX_LOGIC_SMMU_WRAPPER_TCU_GLOBAL_IRPT_NS",
			"TPU_GIA_PULSE_AGGR_0_AUX_LOGIC_SMMU_WRAPPER_TCU_CMD_SYNC_IRPT_NS",
			"TPU_GIA_PULSE_AGGR_0_AUX_LOGIC_SMMU_WRAPPER_TCU_EVENT_Q_IRPT_NS";
	};

	gdmc_level_aggr_0_intr_test: gdmc_level_aggr_0_intr_test {
		compatible = "google,gia-test";
		interrupt-parent = <&gdmc_level_aggr_0_intr>;
		interrupts =
			<GDMC_GIA_LEVEL_AGGR_0_INIT_WRAPPER_RA_TOP_RA_P6S8_RA_NS_INTR>,
			<GDMC_GIA_LEVEL_AGGR_0_XFW_WRAPPER_RFW_RFW_NS_INTR>,
			<GDMC_GIA_LEVEL_AGGR_0_XFW_WRAPPER_MFW_MFW_NS_INTR>,
			<GDMC_GIA_LEVEL_AGGR_0_INIT_WRAPPER_XFW_MFW_INIT_TOP_MFW_INIT_NS_INTR>,
			<GDMC_GIA_LEVEL_AGGR_0_GEM_TOP_IRQ>,
			<GDMC_GIA_LEVEL_AGGR_0_TOP_DHUB_ERR_IRQ>,
			<GDMC_GIA_LEVEL_AGGR_0_DUMMY_GIA_PULSE_AGGR_0_INTR>,
			<GDMC_GIA_LEVEL_AGGR_0_DUMMY_GIA_PULSE_AGGR_1_INTR>,
			<GDMC_GIA_LEVEL_AGGR_0_DUMMY_GIA_PULSE_AGGR_2_INTR>,
			<GDMC_GIA_LEVEL_AGGR_0_DUMMY_GIA_PULSE_AGGR_3_INTR>,
			<GDMC_GIA_LEVEL_AGGR_0_TOP_TSS_INST_ETR_BUFINTR>,
			<GDMC_GIA_LEVEL_AGGR_0_TOP_TSS_INST_ETS_BUFINTR>;
		interrupt-names =
			"GDMC_GIA_LEVEL_AGGR_0_INIT_WRAPPER_RA_TOP_RA_P6S8_RA_NS_INTR",
			"GDMC_GIA_LEVEL_AGGR_0_XFW_WRAPPER_RFW_RFW_NS_INTR",
			"GDMC_GIA_LEVEL_AGGR_0_XFW_WRAPPER_MFW_MFW_NS_INTR",
			"GDMC_GIA_LEVEL_AGGR_0_INIT_WRAPPER_XFW_MFW_INIT_TOP_MFW_INIT_NS_INTR",
			"GDMC_GIA_LEVEL_AGGR_0_GEM_TOP_IRQ",
			"GDMC_GIA_LEVEL_AGGR_0_TOP_DHUB_ERR_IRQ",
			"GDMC_GIA_LEVEL_AGGR_0_DUMMY_GIA_PULSE_AGGR_0_INTR",
			"GDMC_GIA_LEVEL_AGGR_0_DUMMY_GIA_PULSE_AGGR_1_INTR",
			"GDMC_GIA_LEVEL_AGGR_0_DUMMY_GIA_PULSE_AGGR_2_INTR",
			"GDMC_GIA_LEVEL_AGGR_0_DUMMY_GIA_PULSE_AGGR_3_INTR",
			"GDMC_GIA_LEVEL_AGGR_0_TOP_TSS_INST_ETR_BUFINTR",
			"GDMC_GIA_LEVEL_AGGR_0_TOP_TSS_INST_ETS_BUFINTR";
	};
};
